AUTOSAR XML (schema 4-0-3)
package /AUTOSAR_Dem/ImplementationDataTypes
  4 x impl type, all with category=TYPE_REFERENCE, implementation-data-type=uint8:
    Dem_OperationCycleIdType: compu {0=DEM_OPCYC_POWER}, range raw 0
    Dem_IndicatorIdType: range raw 0
    Dem_RatioIdType: range raw 0
    Dem_EnableConditionType
package /AUTOSAR_Dem/SwComponentTypes
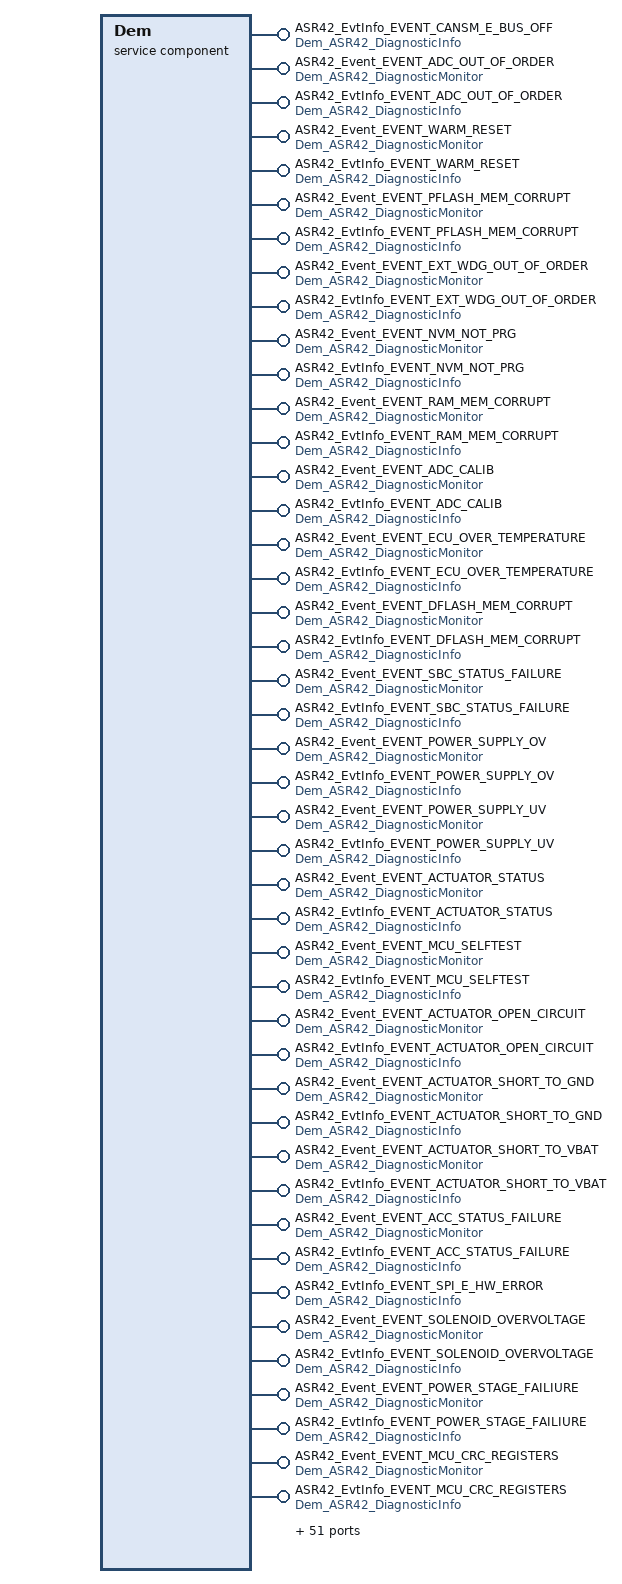
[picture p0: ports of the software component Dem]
  service sw component type Dem
    95 x provide port:
      ASR42_EvtInfo_EVENT_CANSM_E_BUS_OFF: provided-interface=Dem_ASR42_DiagnosticInfo
        provided-com-specs:
          operation=GetEventStatus, queue-length=1
          operation=GetEventFailed, queue-length=1
          operation=GetEventTested, queue-length=1
          operation=GetDTCOfEvent, queue-length=1
          operation=GetFaultDetectionCounter, queue-length=1
          operation=GetEventFreezeFrameData, queue-length=1
          operation=GetEventExtendedDataRecord, queue-length=1
          operation=GetDebouncingOfEvent, queue-length=1
          operation=GetEventExtendedDataRecordEx, queue-length=1
          operation=GetEventFreezeFrameDataEx, queue-length=1
      ASR42_Event_EVENT_ADC_OUT_OF_ORDER: provided-interface=Dem_ASR42_DiagnosticMonitor
        provided-com-specs:
          operation=SetEventStatus, queue-length=1
          operation=ResetEventStatus, queue-length=1
          operation=PrestoreFreezeFrame, queue-length=1
          operation=ClearPrestoredFreezeFrame, queue-length=1
          operation=ResetEventDebounceStatus, queue-length=1
      ASR42_EvtInfo_EVENT_ADC_OUT_OF_ORDER: provided-interface=Dem_ASR42_DiagnosticInfo
        provided-com-specs:
          operation=GetEventStatus, queue-length=1
          operation=GetEventFailed, queue-length=1
          operation=GetEventTested, queue-length=1
          operation=GetDTCOfEvent, queue-length=1
          operation=GetFaultDetectionCounter, queue-length=1
          operation=GetEventFreezeFrameData, queue-length=1
          operation=GetEventExtendedDataRecord, queue-length=1
          operation=GetDebouncingOfEvent, queue-length=1
          operation=GetEventExtendedDataRecordEx, queue-length=1
          operation=GetEventFreezeFrameDataEx, queue-length=1
      ASR42_Event_EVENT_WARM_RESET: provided-interface=Dem_ASR42_DiagnosticMonitor
        provided-com-specs:
          operation=SetEventStatus, queue-length=1
          operation=ResetEventStatus, queue-length=1
          operation=PrestoreFreezeFrame, queue-length=1
          operation=ClearPrestoredFreezeFrame, queue-length=1
          operation=ResetEventDebounceStatus, queue-length=1
      ASR42_EvtInfo_EVENT_WARM_RESET: provided-interface=Dem_ASR42_DiagnosticInfo
        provided-com-specs:
          operation=GetEventStatus, queue-length=1
          operation=GetEventFailed, queue-length=1
          operation=GetEventTested, queue-length=1
          operation=GetDTCOfEvent, queue-length=1
          operation=GetFaultDetectionCounter, queue-length=1
          operation=GetEventFreezeFrameData, queue-length=1
          operation=GetEventExtendedDataRecord, queue-length=1
          operation=GetDebouncingOfEvent, queue-length=1
          operation=GetEventExtendedDataRecordEx, queue-length=1
          operation=GetEventFreezeFrameDataEx, queue-length=1
      ASR42_Event_EVENT_PFLASH_MEM_CORRUPT: provided-interface=Dem_ASR42_DiagnosticMonitor
        provided-com-specs:
          operation=SetEventStatus, queue-length=1
          operation=ResetEventStatus, queue-length=1
          operation=PrestoreFreezeFrame, queue-length=1
          operation=ClearPrestoredFreezeFrame, queue-length=1
          operation=ResetEventDebounceStatus, queue-length=1
      ASR42_EvtInfo_EVENT_PFLASH_MEM_CORRUPT: provided-interface=Dem_ASR42_DiagnosticInfo
        provided-com-specs:
          operation=GetEventStatus, queue-length=1
          operation=GetEventFailed, queue-length=1
          operation=GetEventTested, queue-length=1
          operation=GetDTCOfEvent, queue-length=1
          operation=GetFaultDetectionCounter, queue-length=1
          operation=GetEventFreezeFrameData, queue-length=1
          operation=GetEventExtendedDataRecord, queue-length=1
          operation=GetDebouncingOfEvent, queue-length=1
          operation=GetEventExtendedDataRecordEx, queue-length=1
          operation=GetEventFreezeFrameDataEx, queue-length=1
      ASR42_Event_EVENT_EXT_WDG_OUT_OF_ORDER: provided-interface=Dem_ASR42_DiagnosticMonitor
        provided-com-specs:
          operation=SetEventStatus, queue-length=1
          operation=ResetEventStatus, queue-length=1
          operation=PrestoreFreezeFrame, queue-length=1
          operation=ClearPrestoredFreezeFrame, queue-length=1
          operation=ResetEventDebounceStatus, queue-length=1
      ASR42_EvtInfo_EVENT_EXT_WDG_OUT_OF_ORDER: provided-interface=Dem_ASR42_DiagnosticInfo
        provided-com-specs:
          operation=GetEventStatus, queue-length=1
          operation=GetEventFailed, queue-length=1
          operation=GetEventTested, queue-length=1
          operation=GetDTCOfEvent, queue-length=1
          operation=GetFaultDetectionCounter, queue-length=1
          operation=GetEventFreezeFrameData, queue-length=1
          operation=GetEventExtendedDataRecord, queue-length=1
          operation=GetDebouncingOfEvent, queue-length=1
          operation=GetEventExtendedDataRecordEx, queue-length=1
          operation=GetEventFreezeFrameDataEx, queue-length=1
      ASR42_Event_EVENT_NVM_NOT_PRG: provided-interface=Dem_ASR42_DiagnosticMonitor
        provided-com-specs:
          operation=SetEventStatus, queue-length=1
          operation=ResetEventStatus, queue-length=1
          operation=PrestoreFreezeFrame, queue-length=1
          operation=ClearPrestoredFreezeFrame, queue-length=1
          operation=ResetEventDebounceStatus, queue-length=1
      ASR42_EvtInfo_EVENT_NVM_NOT_PRG: provided-interface=Dem_ASR42_DiagnosticInfo
        provided-com-specs:
          operation=GetEventStatus, queue-length=1
          operation=GetEventFailed, queue-length=1
          operation=GetEventTested, queue-length=1
          operation=GetDTCOfEvent, queue-length=1
          operation=GetFaultDetectionCounter, queue-length=1
          operation=GetEventFreezeFrameData, queue-length=1
          operation=GetEventExtendedDataRecord, queue-length=1
          operation=GetDebouncingOfEvent, queue-length=1
          operation=GetEventExtendedDataRecordEx, queue-length=1
          operation=GetEventFreezeFrameDataEx, queue-length=1
      ASR42_Event_EVENT_RAM_MEM_CORRUPT: provided-interface=Dem_ASR42_DiagnosticMonitor
        provided-com-specs:
          operation=SetEventStatus, queue-length=1
          operation=ResetEventStatus, queue-length=1
          operation=PrestoreFreezeFrame, queue-length=1
          operation=ClearPrestoredFreezeFrame, queue-length=1
          operation=ResetEventDebounceStatus, queue-length=1
      ASR42_EvtInfo_EVENT_RAM_MEM_CORRUPT: provided-interface=Dem_ASR42_DiagnosticInfo
        provided-com-specs:
          operation=GetEventStatus, queue-length=1
          operation=GetEventFailed, queue-length=1
          operation=GetEventTested, queue-length=1
          operation=GetDTCOfEvent, queue-length=1
          operation=GetFaultDetectionCounter, queue-length=1
          operation=GetEventFreezeFrameData, queue-length=1
          operation=GetEventExtendedDataRecord, queue-length=1
          operation=GetDebouncingOfEvent, queue-length=1
          operation=GetEventExtendedDataRecordEx, queue-length=1
          operation=GetEventFreezeFrameDataEx, queue-length=1
      ASR42_Event_EVENT_ADC_CALIB: provided-interface=Dem_ASR42_DiagnosticMonitor
        provided-com-specs:
          operation=SetEventStatus, queue-length=1
          operation=ResetEventStatus, queue-length=1
          operation=PrestoreFreezeFrame, queue-length=1
          operation=ClearPrestoredFreezeFrame, queue-length=1
          operation=ResetEventDebounceStatus, queue-length=1
      ASR42_EvtInfo_EVENT_ADC_CALIB: provided-interface=Dem_ASR42_DiagnosticInfo
        provided-com-specs:
          operation=GetEventStatus, queue-length=1
          operation=GetEventFailed, queue-length=1
          operation=GetEventTested, queue-length=1
          operation=GetDTCOfEvent, queue-length=1
          operation=GetFaultDetectionCounter, queue-length=1
          operation=GetEventFreezeFrameData, queue-length=1
          operation=GetEventExtendedDataRecord, queue-length=1
          operation=GetDebouncingOfEvent, queue-length=1
          operation=GetEventExtendedDataRecordEx, queue-length=1
          operation=GetEventFreezeFrameDataEx, queue-length=1
      ASR42_Event_EVENT_ECU_OVER_TEMPERATURE: provided-interface=Dem_ASR42_DiagnosticMonitor
        provided-com-specs:
          operation=SetEventStatus, queue-length=1
          operation=ResetEventStatus, queue-length=1
          operation=PrestoreFreezeFrame, queue-length=1
          operation=ClearPrestoredFreezeFrame, queue-length=1
          operation=ResetEventDebounceStatus, queue-length=1
      ASR42_EvtInfo_EVENT_ECU_OVER_TEMPERATURE: provided-interface=Dem_ASR42_DiagnosticInfo
        provided-com-specs:
          operation=GetEventStatus, queue-length=1
          operation=GetEventFailed, queue-length=1
          operation=GetEventTested, queue-length=1
          operation=GetDTCOfEvent, queue-length=1
          operation=GetFaultDetectionCounter, queue-length=1
          operation=GetEventFreezeFrameData, queue-length=1
          operation=GetEventExtendedDataRecord, queue-length=1
          operation=GetDebouncingOfEvent, queue-length=1
          operation=GetEventExtendedDataRecordEx, queue-length=1
          operation=GetEventFreezeFrameDataEx, queue-length=1
      ASR42_Event_EVENT_DFLASH_MEM_CORRUPT: provided-interface=Dem_ASR42_DiagnosticMonitor
        provided-com-specs:
          operation=SetEventStatus, queue-length=1
          operation=ResetEventStatus, queue-length=1
          operation=PrestoreFreezeFrame, queue-length=1
          operation=ClearPrestoredFreezeFrame, queue-length=1
          operation=ResetEventDebounceStatus, queue-length=1
      ASR42_EvtInfo_EVENT_DFLASH_MEM_CORRUPT: provided-interface=Dem_ASR42_DiagnosticInfo
        provided-com-specs:
          operation=GetEventStatus, queue-length=1
          operation=GetEventFailed, queue-length=1
          operation=GetEventTested, queue-length=1
          operation=GetDTCOfEvent, queue-length=1
          operation=GetFaultDetectionCounter, queue-length=1
          operation=GetEventFreezeFrameData, queue-length=1
          operation=GetEventExtendedDataRecord, queue-length=1
          operation=GetDebouncingOfEvent, queue-length=1
          operation=GetEventExtendedDataRecordEx, queue-length=1
          operation=GetEventFreezeFrameDataEx, queue-length=1
      ASR42_Event_EVENT_SBC_STATUS_FAILURE: provided-interface=Dem_ASR42_DiagnosticMonitor
        provided-com-specs:
          operation=SetEventStatus, queue-length=1
          operation=ResetEventStatus, queue-length=1
          operation=PrestoreFreezeFrame, queue-length=1
          operation=ClearPrestoredFreezeFrame, queue-length=1
          operation=ResetEventDebounceStatus, queue-length=1
      ASR42_EvtInfo_EVENT_SBC_STATUS_FAILURE: provided-interface=Dem_ASR42_DiagnosticInfo
        provided-com-specs:
          operation=GetEventStatus, queue-length=1
          operation=GetEventFailed, queue-length=1
          operation=GetEventTested, queue-length=1
          operation=GetDTCOfEvent, queue-length=1
          operation=GetFaultDetectionCounter, queue-length=1
          operation=GetEventFreezeFrameData, queue-length=1
          operation=GetEventExtendedDataRecord, queue-length=1
          operation=GetDebouncingOfEvent, queue-length=1
          operation=GetEventExtendedDataRecordEx, queue-length=1
          operation=GetEventFreezeFrameDataEx, queue-length=1
      ASR42_Event_EVENT_POWER_SUPPLY_OV: provided-interface=Dem_ASR42_DiagnosticMonitor
        provided-com-specs:
          operation=SetEventStatus, queue-length=1
          operation=ResetEventStatus, queue-length=1
          operation=PrestoreFreezeFrame, queue-length=1
          operation=ClearPrestoredFreezeFrame, queue-length=1
          operation=ResetEventDebounceStatus, queue-length=1
      ASR42_EvtInfo_EVENT_POWER_SUPPLY_OV: provided-interface=Dem_ASR42_DiagnosticInfo
        provided-com-specs:
          operation=GetEventStatus, queue-length=1
          operation=GetEventFailed, queue-length=1
          operation=GetEventTested, queue-length=1
          operation=GetDTCOfEvent, queue-length=1
          operation=GetFaultDetectionCounter, queue-length=1
          operation=GetEventFreezeFrameData, queue-length=1
          operation=GetEventExtendedDataRecord, queue-length=1
          operation=GetDebouncingOfEvent, queue-length=1
          operation=GetEventExtendedDataRecordEx, queue-length=1
          operation=GetEventFreezeFrameDataEx, queue-length=1
      ASR42_Event_EVENT_POWER_SUPPLY_UV: provided-interface=Dem_ASR42_DiagnosticMonitor
        provided-com-specs:
          operation=SetEventStatus, queue-length=1
          operation=ResetEventStatus, queue-length=1
          operation=PrestoreFreezeFrame, queue-length=1
          operation=ClearPrestoredFreezeFrame, queue-length=1
          operation=ResetEventDebounceStatus, queue-length=1
      ASR42_EvtInfo_EVENT_POWER_SUPPLY_UV: provided-interface=Dem_ASR42_DiagnosticInfo
        provided-com-specs:
          operation=GetEventStatus, queue-length=1
          operation=GetEventFailed, queue-length=1
          operation=GetEventTested, queue-length=1
          operation=GetDTCOfEvent, queue-length=1
          operation=GetFaultDetectionCounter, queue-length=1
          operation=GetEventFreezeFrameData, queue-length=1
          operation=GetEventExtendedDataRecord, queue-length=1
          operation=GetDebouncingOfEvent, queue-length=1
          operation=GetEventExtendedDataRecordEx, queue-length=1
          operation=GetEventFreezeFrameDataEx, queue-length=1
      ASR42_Event_EVENT_ACTUATOR_STATUS: provided-interface=Dem_ASR42_DiagnosticMonitor
        provided-com-specs:
          operation=SetEventStatus, queue-length=1
          operation=ResetEventStatus, queue-length=1
          operation=PrestoreFreezeFrame, queue-length=1
          operation=ClearPrestoredFreezeFrame, queue-length=1
          operation=ResetEventDebounceStatus, queue-length=1
      ASR42_EvtInfo_EVENT_ACTUATOR_STATUS: provided-interface=Dem_ASR42_DiagnosticInfo
        provided-com-specs:
          operation=GetEventStatus, queue-length=1
          operation=GetEventFailed, queue-length=1
          operation=GetEventTested, queue-length=1
          operation=GetDTCOfEvent, queue-length=1
          operation=GetFaultDetectionCounter, queue-length=1
          operation=GetEventFreezeFrameData, queue-length=1
          operation=GetEventExtendedDataRecord, queue-length=1
          operation=GetDebouncingOfEvent, queue-length=1
          operation=GetEventExtendedDataRecordEx, queue-length=1
          operation=GetEventFreezeFrameDataEx, queue-length=1
      ASR42_Event_EVENT_MCU_SELFTEST: provided-interface=Dem_ASR42_DiagnosticMonitor
        provided-com-specs:
          operation=SetEventStatus, queue-length=1
          operation=ResetEventStatus, queue-length=1
          operation=PrestoreFreezeFrame, queue-length=1
          operation=ClearPrestoredFreezeFrame, queue-length=1
          operation=ResetEventDebounceStatus, queue-length=1
      ASR42_EvtInfo_EVENT_MCU_SELFTEST: provided-interface=Dem_ASR42_DiagnosticInfo
        provided-com-specs:
          operation=GetEventStatus, queue-length=1
          operation=GetEventFailed, queue-length=1
          operation=GetEventTested, queue-length=1
          operation=GetDTCOfEvent, queue-length=1
          operation=GetFaultDetectionCounter, queue-length=1
          operation=GetEventFreezeFrameData, queue-length=1
          operation=GetEventExtendedDataRecord, queue-length=1
          operation=GetDebouncingOfEvent, queue-length=1
          operation=GetEventExtendedDataRecordEx, queue-length=1
          operation=GetEventFreezeFrameDataEx, queue-length=1
      ASR42_Event_EVENT_ACTUATOR_OPEN_CIRCUIT: provided-interface=Dem_ASR42_DiagnosticMonitor
        provided-com-specs:
          operation=SetEventStatus, queue-length=1
          operation=ResetEventStatus, queue-length=1
          operation=PrestoreFreezeFrame, queue-length=1
          operation=ClearPrestoredFreezeFrame, queue-length=1
          operation=ResetEventDebounceStatus, queue-length=1
      ASR42_EvtInfo_EVENT_ACTUATOR_OPEN_CIRCUIT: provided-interface=Dem_ASR42_DiagnosticInfo
        provided-com-specs:
          operation=GetEventStatus, queue-length=1
          operation=GetEventFailed, queue-length=1
          operation=GetEventTested, queue-length=1
          operation=GetDTCOfEvent, queue-length=1
          operation=GetFaultDetectionCounter, queue-length=1
          operation=GetEventFreezeFrameData, queue-length=1
          operation=GetEventExtendedDataRecord, queue-length=1
          operation=GetDebouncingOfEvent, queue-length=1
          operation=GetEventExtendedDataRecordEx, queue-length=1
          operation=GetEventFreezeFrameDataEx, queue-length=1
      ASR42_Event_EVENT_ACTUATOR_SHORT_TO_GND: provided-interface=Dem_ASR42_DiagnosticMonitor
        provided-com-specs:
          operation=SetEventStatus, queue-length=1
          operation=ResetEventStatus, queue-length=1
          operation=PrestoreFreezeFrame, queue-length=1
          operation=ClearPrestoredFreezeFrame, queue-length=1
          operation=ResetEventDebounceStatus, queue-length=1
      ASR42_EvtInfo_EVENT_ACTUATOR_SHORT_TO_GND: provided-interface=Dem_ASR42_DiagnosticInfo
        provided-com-specs:
          operation=GetEventStatus, queue-length=1
          operation=GetEventFailed, queue-length=1
          operation=GetEventTested, queue-length=1
          operation=GetDTCOfEvent, queue-length=1
          operation=GetFaultDetectionCounter, queue-length=1
          operation=GetEventFreezeFrameData, queue-length=1
          operation=GetEventExtendedDataRecord, queue-length=1
          operation=GetDebouncingOfEvent, queue-length=1
          operation=GetEventExtendedDataRecordEx, queue-length=1
          operation=GetEventFreezeFrameDataEx, queue-length=1
      ASR42_Event_EVENT_ACTUATOR_SHORT_TO_VBAT: provided-interface=Dem_ASR42_DiagnosticMonitor
        provided-com-specs:
          operation=SetEventStatus, queue-length=1
          operation=ResetEventStatus, queue-length=1
          operation=PrestoreFreezeFrame, queue-length=1
          operation=ClearPrestoredFreezeFrame, queue-length=1
          operation=ResetEventDebounceStatus, queue-length=1
      ASR42_EvtInfo_EVENT_ACTUATOR_SHORT_TO_VBAT: provided-interface=Dem_ASR42_DiagnosticInfo
        provided-com-specs:
          operation=GetEventStatus, queue-length=1
          operation=GetEventFailed, queue-length=1
          operation=GetEventTested, queue-length=1
          operation=GetDTCOfEvent, queue-length=1
          operation=GetFaultDetectionCounter, queue-length=1
          operation=GetEventFreezeFrameData, queue-length=1
          operation=GetEventExtendedDataRecord, queue-length=1
          operation=GetDebouncingOfEvent, queue-length=1
          operation=GetEventExtendedDataRecordEx, queue-length=1
          operation=GetEventFreezeFrameDataEx, queue-length=1
      ASR42_Event_EVENT_ACC_STATUS_FAILURE: provided-interface=Dem_ASR42_DiagnosticMonitor
        provided-com-specs:
          operation=SetEventStatus, queue-length=1
          operation=ResetEventStatus, queue-length=1
          operation=PrestoreFreezeFrame, queue-length=1
          operation=ClearPrestoredFreezeFrame, queue-length=1
          operation=ResetEventDebounceStatus, queue-length=1
      ASR42_EvtInfo_EVENT_ACC_STATUS_FAILURE: provided-interface=Dem_ASR42_DiagnosticInfo
        provided-com-specs:
          operation=GetEventStatus, queue-length=1
          operation=GetEventFailed, queue-length=1
          operation=GetEventTested, queue-length=1
          operation=GetDTCOfEvent, queue-length=1
          operation=GetFaultDetectionCounter, queue-length=1
          operation=GetEventFreezeFrameData, queue-length=1
          operation=GetEventExtendedDataRecord, queue-length=1
          operation=GetDebouncingOfEvent, queue-length=1
          operation=GetEventExtendedDataRecordEx, queue-length=1
          operation=GetEventFreezeFrameDataEx, queue-length=1
      ASR42_EvtInfo_EVENT_SPI_E_HW_ERROR: provided-interface=Dem_ASR42_DiagnosticInfo
        provided-com-specs:
          operation=GetEventStatus, queue-length=1
          operation=GetEventFailed, queue-length=1
          operation=GetEventTested, queue-length=1
          operation=GetDTCOfEvent, queue-length=1
          operation=GetFaultDetectionCounter, queue-length=1
          operation=GetEventFreezeFrameData, queue-length=1
          operation=GetEventExtendedDataRecord, queue-length=1
          operation=GetDebouncingOfEvent, queue-length=1
          operation=GetEventExtendedDataRecordEx, queue-length=1
          operation=GetEventFreezeFrameDataEx, queue-length=1
      ASR42_Event_EVENT_SOLENOID_OVERVOLTAGE: provided-interface=Dem_ASR42_DiagnosticMonitor
        provided-com-specs:
          operation=SetEventStatus, queue-length=1
          operation=ResetEventStatus, queue-length=1
          operation=PrestoreFreezeFrame, queue-length=1
          operation=ClearPrestoredFreezeFrame, queue-length=1
          operation=ResetEventDebounceStatus, queue-length=1
      ASR42_EvtInfo_EVENT_SOLENOID_OVERVOLTAGE: provided-interface=Dem_ASR42_DiagnosticInfo
        provided-com-specs:
          operation=GetEventStatus, queue-length=1
          operation=GetEventFailed, queue-length=1
          operation=GetEventTested, queue-length=1
          operation=GetDTCOfEvent, queue-length=1
          operation=GetFaultDetectionCounter, queue-length=1
          operation=GetEventFreezeFrameData, queue-length=1
          operation=GetEventExtendedDataRecord, queue-length=1
          operation=GetDebouncingOfEvent, queue-length=1
          operation=GetEventExtendedDataRecordEx, queue-length=1
          operation=GetEventFreezeFrameDataEx, queue-length=1
      ASR42_Event_EVENT_POWER_STAGE_FAILIURE: provided-interface=Dem_ASR42_DiagnosticMonitor
        provided-com-specs:
          operation=SetEventStatus, queue-length=1
          operation=ResetEventStatus, queue-length=1
          operation=PrestoreFreezeFrame, queue-length=1
          operation=ClearPrestoredFreezeFrame, queue-length=1
          operation=ResetEventDebounceStatus, queue-length=1
      ASR42_EvtInfo_EVENT_POWER_STAGE_FAILIURE: provided-interface=Dem_ASR42_DiagnosticInfo
        provided-com-specs:
          operation=GetEventStatus, queue-length=1
          operation=GetEventFailed, queue-length=1
          operation=GetEventTested, queue-length=1
          operation=GetDTCOfEvent, queue-length=1
          operation=GetFaultDetectionCounter, queue-length=1
          operation=GetEventFreezeFrameData, queue-length=1
          operation=GetEventExtendedDataRecord, queue-length=1
          operation=GetDebouncingOfEvent, queue-length=1
          operation=GetEventExtendedDataRecordEx, queue-length=1
          operation=GetEventFreezeFrameDataEx, queue-length=1
      ASR42_Event_EVENT_MCU_CRC_REGISTERS: provided-interface=Dem_ASR42_DiagnosticMonitor
        provided-com-specs:
          operation=SetEventStatus, queue-length=1
          operation=ResetEventStatus, queue-length=1
          operation=PrestoreFreezeFrame, queue-length=1
          operation=ClearPrestoredFreezeFrame, queue-length=1
          operation=ResetEventDebounceStatus, queue-length=1
      ASR42_EvtInfo_EVENT_MCU_CRC_REGISTERS: provided-interface=Dem_ASR42_DiagnosticInfo
        provided-com-specs:
          operation=GetEventStatus, queue-length=1
          operation=GetEventFailed, queue-length=1
          operation=GetEventTested, queue-length=1
          operation=GetDTCOfEvent, queue-length=1
          operation=GetFaultDetectionCounter, queue-length=1
          operation=GetEventFreezeFrameData, queue-length=1
          operation=GetEventExtendedDataRecord, queue-length=1
          operation=GetDebouncingOfEvent, queue-length=1
          operation=GetEventExtendedDataRecordEx, queue-length=1
          operation=GetEventFreezeFrameDataEx, queue-length=1
      ASR42_GeneralEvtInfo: provided-interface=Dem_ASR42_GeneralDiagnosticInfo
        provided-com-specs:
          operation=GetEventStatus, queue-length=1
          operation=GetEventFailed, queue-length=1
          operation=GetEventTested, queue-length=1
          operation=GetDTCOfEvent, queue-length=1
          operation=GetFaultDetectionCounter, queue-length=1
          operation=GetEventFreezeFrameData, queue-length=1
          operation=GetEventExtendedDataRecord, queue-length=1
          operation=GetDebouncingOfEvent, queue-length=1
          operation=GetEventExtendedDataRecordEx, queue-length=1
          operation=GetEventFreezeFrameDataEx, queue-length=1
      ASR42_OpCycle_DEM_OPCYC_POWER: provided-com-specs=[{operation=SetOperationCycleState, queue-length=1}, {operation=SetCycleQualified, queue-length=1}], provided-interface=Dem_ASR42_OperationCycle
      ASR42_OverflowIndPrimaryMemory: provided-interface=Dem_ASR42_EvMemOverflowIndication
        provided-com-specs:
          operation=GetEventMemoryOverflow, queue-length=1
          operation=GetNumberOfEventMemoryEntries, queue-length=1
      EvtInfo_EVENT_CANSM_E_BUS_OFF: provided-interface=DiagnosticInfo
        provided-com-specs:
          operation=GetEventStatus, queue-length=1
          operation=GetEventFailed, queue-length=1
          operation=GetEventTested, queue-length=1
          operation=GetDTCOfEvent, queue-length=1
          operation=GetFaultDetectionCounter, queue-length=1
          operation=GetEventFreezeFrameData, queue-length=1
          operation=GetEventExtendedDataRecord, queue-length=1
          operation=GetDebouncingOfEvent, queue-length=1
          operation=GetEventExtendedDataRecordEx, queue-length=1
          operation=GetEventFreezeFrameDataEx, queue-length=1
      Event_EVENT_ADC_OUT_OF_ORDER: provided-interface=DiagnosticMonitor
        provided-com-specs:
          operation=SetEventStatus, queue-length=1
          operation=ResetEventStatus, queue-length=1
          operation=PrestoreFreezeFrame, queue-length=1
          operation=ClearPrestoredFreezeFrame, queue-length=1
          operation=ResetEventDebounceStatus, queue-length=1
      EvtInfo_EVENT_ADC_OUT_OF_ORDER: provided-interface=DiagnosticInfo
        provided-com-specs:
          operation=GetEventStatus, queue-length=1
          operation=GetEventFailed, queue-length=1
          operation=GetEventTested, queue-length=1
          operation=GetDTCOfEvent, queue-length=1
          operation=GetFaultDetectionCounter, queue-length=1
          operation=GetEventFreezeFrameData, queue-length=1
          operation=GetEventExtendedDataRecord, queue-length=1
          operation=GetDebouncingOfEvent, queue-length=1
          operation=GetEventExtendedDataRecordEx, queue-length=1
          operation=GetEventFreezeFrameDataEx, queue-length=1
      Event_EVENT_WARM_RESET: provided-interface=DiagnosticMonitor
        provided-com-specs:
          operation=SetEventStatus, queue-length=1
          operation=ResetEventStatus, queue-length=1
          operation=PrestoreFreezeFrame, queue-length=1
          operation=ClearPrestoredFreezeFrame, queue-length=1
          operation=ResetEventDebounceStatus, queue-length=1
      EvtInfo_EVENT_WARM_RESET: provided-interface=DiagnosticInfo
        provided-com-specs:
          operation=GetEventStatus, queue-length=1
          operation=GetEventFailed, queue-length=1
          operation=GetEventTested, queue-length=1
          operation=GetDTCOfEvent, queue-length=1
          operation=GetFaultDetectionCounter, queue-length=1
          operation=GetEventFreezeFrameData, queue-length=1
          operation=GetEventExtendedDataRecord, queue-length=1
          operation=GetDebouncingOfEvent, queue-length=1
          operation=GetEventExtendedDataRecordEx, queue-length=1
          operation=GetEventFreezeFrameDataEx, queue-length=1
      Event_EVENT_PFLASH_MEM_CORRUPT: provided-interface=DiagnosticMonitor
        provided-com-specs:
          operation=SetEventStatus, queue-length=1
          operation=ResetEventStatus, queue-length=1
          operation=PrestoreFreezeFrame, queue-length=1
          operation=ClearPrestoredFreezeFrame, queue-length=1
          operation=ResetEventDebounceStatus, queue-length=1
      EvtInfo_EVENT_PFLASH_MEM_CORRUPT: provided-interface=DiagnosticInfo
        provided-com-specs:
          operation=GetEventStatus, queue-length=1
          operation=GetEventFailed, queue-length=1
          operation=GetEventTested, queue-length=1
          operation=GetDTCOfEvent, queue-length=1
          operation=GetFaultDetectionCounter, queue-length=1
          operation=GetEventFreezeFrameData, queue-length=1
          operation=GetEventExtendedDataRecord, queue-length=1
          operation=GetDebouncingOfEvent, queue-length=1
          operation=GetEventExtendedDataRecordEx, queue-length=1
          operation=GetEventFreezeFrameDataEx, queue-length=1
      Event_EVENT_EXT_WDG_OUT_OF_ORDER: provided-interface=DiagnosticMonitor
        provided-com-specs:
          operation=SetEventStatus, queue-length=1
          operation=ResetEventStatus, queue-length=1
          operation=PrestoreFreezeFrame, queue-length=1
          operation=ClearPrestoredFreezeFrame, queue-length=1
          operation=ResetEventDebounceStatus, queue-length=1
      EvtInfo_EVENT_EXT_WDG_OUT_OF_ORDER: provided-interface=DiagnosticInfo
        provided-com-specs:
          operation=GetEventStatus, queue-length=1
          operation=GetEventFailed, queue-length=1
          operation=GetEventTested, queue-length=1
          operation=GetDTCOfEvent, queue-length=1
          operation=GetFaultDetectionCounter, queue-length=1
          operation=GetEventFreezeFrameData, queue-length=1
          operation=GetEventExtendedDataRecord, queue-length=1
          operation=GetDebouncingOfEvent, queue-length=1
          operation=GetEventExtendedDataRecordEx, queue-length=1
          operation=GetEventFreezeFrameDataEx, queue-length=1
      Event_EVENT_NVM_NOT_PRG: provided-interface=DiagnosticMonitor
        provided-com-specs:
          operation=SetEventStatus, queue-length=1
          operation=ResetEventStatus, queue-length=1
          operation=PrestoreFreezeFrame, queue-length=1
          operation=ClearPrestoredFreezeFrame, queue-length=1
          operation=ResetEventDebounceStatus, queue-length=1
      EvtInfo_EVENT_NVM_NOT_PRG: provided-interface=DiagnosticInfo
        provided-com-specs:
          operation=GetEventStatus, queue-length=1
          operation=GetEventFailed, queue-length=1
          operation=GetEventTested, queue-length=1
          operation=GetDTCOfEvent, queue-length=1
          operation=GetFaultDetectionCounter, queue-length=1
          operation=GetEventFreezeFrameData, queue-length=1
          operation=GetEventExtendedDataRecord, queue-length=1
          operation=GetDebouncingOfEvent, queue-length=1
          operation=GetEventExtendedDataRecordEx, queue-length=1
          operation=GetEventFreezeFrameDataEx, queue-length=1
      Event_EVENT_RAM_MEM_CORRUPT: provided-interface=DiagnosticMonitor
        provided-com-specs:
          operation=SetEventStatus, queue-length=1
          operation=ResetEventStatus, queue-length=1
          operation=PrestoreFreezeFrame, queue-length=1
          operation=ClearPrestoredFreezeFrame, queue-length=1
          operation=ResetEventDebounceStatus, queue-length=1
      EvtInfo_EVENT_RAM_MEM_CORRUPT: provided-interface=DiagnosticInfo
        provided-com-specs:
          operation=GetEventStatus, queue-length=1
          operation=GetEventFailed, queue-length=1
          operation=GetEventTested, queue-length=1
          operation=GetDTCOfEvent, queue-length=1
          operation=GetFaultDetectionCounter, queue-length=1
          operation=GetEventFreezeFrameData, queue-length=1
          operation=GetEventExtendedDataRecord, queue-length=1
          operation=GetDebouncingOfEvent, queue-length=1
          operation=GetEventExtendedDataRecordEx, queue-length=1
          operation=GetEventFreezeFrameDataEx, queue-length=1
      Event_EVENT_ADC_CALIB: provided-interface=DiagnosticMonitor
        provided-com-specs:
          operation=SetEventStatus, queue-length=1
          operation=ResetEventStatus, queue-length=1
          operation=PrestoreFreezeFrame, queue-length=1
          operation=ClearPrestoredFreezeFrame, queue-length=1
          operation=ResetEventDebounceStatus, queue-length=1
      EvtInfo_EVENT_ADC_CALIB: provided-interface=DiagnosticInfo
        provided-com-specs:
          operation=GetEventStatus, queue-length=1
          operation=GetEventFailed, queue-length=1
          operation=GetEventTested, queue-length=1
          operation=GetDTCOfEvent, queue-length=1
          operation=GetFaultDetectionCounter, queue-length=1
          operation=GetEventFreezeFrameData, queue-length=1
          operation=GetEventExtendedDataRecord, queue-length=1
          operation=GetDebouncingOfEvent, queue-length=1
          operation=GetEventExtendedDataRecordEx, queue-length=1
          operation=GetEventFreezeFrameDataEx, queue-length=1
      Event_EVENT_ECU_OVER_TEMPERATURE: provided-interface=DiagnosticMonitor
        provided-com-specs:
          operation=SetEventStatus, queue-length=1
          operation=ResetEventStatus, queue-length=1
          operation=PrestoreFreezeFrame, queue-length=1
          operation=ClearPrestoredFreezeFrame, queue-length=1
          operation=ResetEventDebounceStatus, queue-length=1
      EvtInfo_EVENT_ECU_OVER_TEMPERATURE: provided-interface=DiagnosticInfo
        provided-com-specs:
          operation=GetEventStatus, queue-length=1
          operation=GetEventFailed, queue-length=1
          operation=GetEventTested, queue-length=1
          operation=GetDTCOfEvent, queue-length=1
          operation=GetFaultDetectionCounter, queue-length=1
          operation=GetEventFreezeFrameData, queue-length=1
          operation=GetEventExtendedDataRecord, queue-length=1
          operation=GetDebouncingOfEvent, queue-length=1
          operation=GetEventExtendedDataRecordEx, queue-length=1
          operation=GetEventFreezeFrameDataEx, queue-length=1
      Event_EVENT_DFLASH_MEM_CORRUPT: provided-interface=DiagnosticMonitor
        provided-com-specs:
          operation=SetEventStatus, queue-length=1
          operation=ResetEventStatus, queue-length=1
          operation=PrestoreFreezeFrame, queue-length=1
          operation=ClearPrestoredFreezeFrame, queue-length=1
          operation=ResetEventDebounceStatus, queue-length=1
      EvtInfo_EVENT_DFLASH_MEM_CORRUPT: provided-interface=DiagnosticInfo
        provided-com-specs:
          operation=GetEventStatus, queue-length=1
          operation=GetEventFailed, queue-length=1
          operation=GetEventTested, queue-length=1
          operation=GetDTCOfEvent, queue-length=1
          operation=GetFaultDetectionCounter, queue-length=1
          operation=GetEventFreezeFrameData, queue-length=1
          operation=GetEventExtendedDataRecord, queue-length=1
          operation=GetDebouncingOfEvent, queue-length=1
          operation=GetEventExtendedDataRecordEx, queue-length=1
          operation=GetEventFreezeFrameDataEx, queue-length=1
      Event_EVENT_SBC_STATUS_FAILURE: provided-interface=DiagnosticMonitor
        provided-com-specs:
          operation=SetEventStatus, queue-length=1
          operation=ResetEventStatus, queue-length=1
          operation=PrestoreFreezeFrame, queue-length=1
          operation=ClearPrestoredFreezeFrame, queue-length=1
          operation=ResetEventDebounceStatus, queue-length=1
      EvtInfo_EVENT_SBC_STATUS_FAILURE: provided-interface=DiagnosticInfo
        provided-com-specs:
          operation=GetEventStatus, queue-length=1
          operation=GetEventFailed, queue-length=1
          operation=GetEventTested, queue-length=1
          operation=GetDTCOfEvent, queue-length=1
          operation=GetFaultDetectionCounter, queue-length=1
          operation=GetEventFreezeFrameData, queue-length=1
          operation=GetEventExtendedDataRecord, queue-length=1
          operation=GetDebouncingOfEvent, queue-length=1
          operation=GetEventExtendedDataRecordEx, queue-length=1
          operation=GetEventFreezeFrameDataEx, queue-length=1
      Event_EVENT_POWER_SUPPLY_OV: provided-interface=DiagnosticMonitor
        provided-com-specs:
          operation=SetEventStatus, queue-length=1
          operation=ResetEventStatus, queue-length=1
          operation=PrestoreFreezeFrame, queue-length=1
          operation=ClearPrestoredFreezeFrame, queue-length=1
          operation=ResetEventDebounceStatus, queue-length=1
      EvtInfo_EVENT_POWER_SUPPLY_OV: provided-interface=DiagnosticInfo
        provided-com-specs:
          operation=GetEventStatus, queue-length=1
          operation=GetEventFailed, queue-length=1
          operation=GetEventTested, queue-length=1
          operation=GetDTCOfEvent, queue-length=1
          operation=GetFaultDetectionCounter, queue-length=1
          operation=GetEventFreezeFrameData, queue-length=1
          operation=GetEventExtendedDataRecord, queue-length=1
          operation=GetDebouncingOfEvent, queue-length=1
          operation=GetEventExtendedDataRecordEx, queue-length=1
          operation=GetEventFreezeFrameDataEx, queue-length=1
      Event_EVENT_POWER_SUPPLY_UV: provided-interface=DiagnosticMonitor
        provided-com-specs:
          operation=SetEventStatus, queue-length=1
          operation=ResetEventStatus, queue-length=1
          operation=PrestoreFreezeFrame, queue-length=1
          operation=ClearPrestoredFreezeFrame, queue-length=1
          operation=ResetEventDebounceStatus, queue-length=1
      EvtInfo_EVENT_POWER_SUPPLY_UV: provided-interface=DiagnosticInfo
        provided-com-specs:
          operation=GetEventStatus, queue-length=1
          operation=GetEventFailed, queue-length=1
          operation=GetEventTested, queue-length=1
          operation=GetDTCOfEvent, queue-length=1
          operation=GetFaultDetectionCounter, queue-length=1
          operation=GetEventFreezeFrameData, queue-length=1
          operation=GetEventExtendedDataRecord, queue-length=1
          operation=GetDebouncingOfEvent, queue-length=1
          operation=GetEventExtendedDataRecordEx, queue-length=1
          operation=GetEventFreezeFrameDataEx, queue-length=1
      Event_EVENT_ACTUATOR_STATUS: provided-interface=DiagnosticMonitor
        provided-com-specs:
          operation=SetEventStatus, queue-length=1
          operation=ResetEventStatus, queue-length=1
          operation=PrestoreFreezeFrame, queue-length=1
          operation=ClearPrestoredFreezeFrame, queue-length=1
          operation=ResetEventDebounceStatus, queue-length=1
      EvtInfo_EVENT_ACTUATOR_STATUS: provided-interface=DiagnosticInfo
        provided-com-specs:
          operation=GetEventStatus, queue-length=1
          operation=GetEventFailed, queue-length=1
          operation=GetEventTested, queue-length=1
          operation=GetDTCOfEvent, queue-length=1
          operation=GetFaultDetectionCounter, queue-length=1
          operation=GetEventFreezeFrameData, queue-length=1
          operation=GetEventExtendedDataRecord, queue-length=1
          operation=GetDebouncingOfEvent, queue-length=1
          operation=GetEventExtendedDataRecordEx, queue-length=1
          operation=GetEventFreezeFrameDataEx, queue-length=1
      Event_EVENT_MCU_SELFTEST: provided-interface=DiagnosticMonitor
        provided-com-specs:
          operation=SetEventStatus, queue-length=1
          operation=ResetEventStatus, queue-length=1
          operation=PrestoreFreezeFrame, queue-length=1
          operation=ClearPrestoredFreezeFrame, queue-length=1
          operation=ResetEventDebounceStatus, queue-length=1
      EvtInfo_EVENT_MCU_SELFTEST: provided-interface=DiagnosticInfo
        provided-com-specs:
          operation=GetEventStatus, queue-length=1
          operation=GetEventFailed, queue-length=1
          operation=GetEventTested, queue-length=1
          operation=GetDTCOfEvent, queue-length=1
          operation=GetFaultDetectionCounter, queue-length=1
          operation=GetEventFreezeFrameData, queue-length=1
          operation=GetEventExtendedDataRecord, queue-length=1
          operation=GetDebouncingOfEvent, queue-length=1
          operation=GetEventExtendedDataRecordEx, queue-length=1
          operation=GetEventFreezeFrameDataEx, queue-length=1
      Event_EVENT_ACTUATOR_OPEN_CIRCUIT: provided-interface=DiagnosticMonitor
        provided-com-specs:
          operation=SetEventStatus, queue-length=1
          operation=ResetEventStatus, queue-length=1
          operation=PrestoreFreezeFrame, queue-length=1
          operation=ClearPrestoredFreezeFrame, queue-length=1
          operation=ResetEventDebounceStatus, queue-length=1
      EvtInfo_EVENT_ACTUATOR_OPEN_CIRCUIT: provided-interface=DiagnosticInfo
        provided-com-specs:
          operation=GetEventStatus, queue-length=1
          operation=GetEventFailed, queue-length=1
          operation=GetEventTested, queue-length=1
          operation=GetDTCOfEvent, queue-length=1
          operation=GetFaultDetectionCounter, queue-length=1
          operation=GetEventFreezeFrameData, queue-length=1
          operation=GetEventExtendedDataRecord, queue-length=1
          operation=GetDebouncingOfEvent, queue-length=1
          operation=GetEventExtendedDataRecordEx, queue-length=1
          operation=GetEventFreezeFrameDataEx, queue-length=1
      Event_EVENT_ACTUATOR_SHORT_TO_GND: provided-interface=DiagnosticMonitor
        provided-com-specs:
          operation=SetEventStatus, queue-length=1
          operation=ResetEventStatus, queue-length=1
          operation=PrestoreFreezeFrame, queue-length=1
          operation=ClearPrestoredFreezeFrame, queue-length=1
          operation=ResetEventDebounceStatus, queue-length=1
      EvtInfo_EVENT_ACTUATOR_SHORT_TO_GND: provided-interface=DiagnosticInfo
        provided-com-specs:
          operation=GetEventStatus, queue-length=1
          operation=GetEventFailed, queue-length=1
          operation=GetEventTested, queue-length=1
          operation=GetDTCOfEvent, queue-length=1
          operation=GetFaultDetectionCounter, queue-length=1
          operation=GetEventFreezeFrameData, queue-length=1
          operation=GetEventExtendedDataRecord, queue-length=1
          operation=GetDebouncingOfEvent, queue-length=1
          operation=GetEventExtendedDataRecordEx, queue-length=1
          operation=GetEventFreezeFrameDataEx, queue-length=1
      Event_EVENT_ACTUATOR_SHORT_TO_VBAT: provided-interface=DiagnosticMonitor
        provided-com-specs:
          operation=SetEventStatus, queue-length=1
          operation=ResetEventStatus, queue-length=1
          operation=PrestoreFreezeFrame, queue-length=1
          operation=ClearPrestoredFreezeFrame, queue-length=1
          operation=ResetEventDebounceStatus, queue-length=1
      EvtInfo_EVENT_ACTUATOR_SHORT_TO_VBAT: provided-interface=DiagnosticInfo
        provided-com-specs:
          operation=GetEventStatus, queue-length=1
          operation=GetEventFailed, queue-length=1
          operation=GetEventTested, queue-length=1
          operation=GetDTCOfEvent, queue-length=1
          operation=GetFaultDetectionCounter, queue-length=1
          operation=GetEventFreezeFrameData, queue-length=1
          operation=GetEventExtendedDataRecord, queue-length=1
          operation=GetDebouncingOfEvent, queue-length=1
          operation=GetEventExtendedDataRecordEx, queue-length=1
          operation=GetEventFreezeFrameDataEx, queue-length=1
      Event_EVENT_ACC_STATUS_FAILURE: provided-interface=DiagnosticMonitor
        provided-com-specs:
          operation=SetEventStatus, queue-length=1
          operation=ResetEventStatus, queue-length=1
          operation=PrestoreFreezeFrame, queue-length=1
          operation=ClearPrestoredFreezeFrame, queue-length=1
          operation=ResetEventDebounceStatus, queue-length=1
      EvtInfo_EVENT_ACC_STATUS_FAILURE: provided-interface=DiagnosticInfo
        provided-com-specs:
          operation=GetEventStatus, queue-length=1
          operation=GetEventFailed, queue-length=1
          operation=GetEventTested, queue-length=1
          operation=GetDTCOfEvent, queue-length=1
          operation=GetFaultDetectionCounter, queue-length=1
          operation=GetEventFreezeFrameData, queue-length=1
          operation=GetEventExtendedDataRecord, queue-length=1
          operation=GetDebouncingOfEvent, queue-length=1
          operation=GetEventExtendedDataRecordEx, queue-length=1
          operation=GetEventFreezeFrameDataEx, queue-length=1
      EvtInfo_EVENT_SPI_E_HW_ERROR: provided-interface=DiagnosticInfo
        provided-com-specs:
          operation=GetEventStatus, queue-length=1
          operation=GetEventFailed, queue-length=1
          operation=GetEventTested, queue-length=1
          operation=GetDTCOfEvent, queue-length=1
          operation=GetFaultDetectionCounter, queue-length=1
          operation=GetEventFreezeFrameData, queue-length=1
          operation=GetEventExtendedDataRecord, queue-length=1
          operation=GetDebouncingOfEvent, queue-length=1
          operation=GetEventExtendedDataRecordEx, queue-length=1
          operation=GetEventFreezeFrameDataEx, queue-length=1
      Event_EVENT_SOLENOID_OVERVOLTAGE: provided-interface=DiagnosticMonitor
        provided-com-specs:
          operation=SetEventStatus, queue-length=1
          operation=ResetEventStatus, queue-length=1
          operation=PrestoreFreezeFrame, queue-length=1
          operation=ClearPrestoredFreezeFrame, queue-length=1
          operation=ResetEventDebounceStatus, queue-length=1
      EvtInfo_EVENT_SOLENOID_OVERVOLTAGE: provided-interface=DiagnosticInfo
        provided-com-specs:
          operation=GetEventStatus, queue-length=1
          operation=GetEventFailed, queue-length=1
          operation=GetEventTested, queue-length=1
          operation=GetDTCOfEvent, queue-length=1
          operation=GetFaultDetectionCounter, queue-length=1
          operation=GetEventFreezeFrameData, queue-length=1
          operation=GetEventExtendedDataRecord, queue-length=1
          operation=GetDebouncingOfEvent, queue-length=1
          operation=GetEventExtendedDataRecordEx, queue-length=1
          operation=GetEventFreezeFrameDataEx, queue-length=1
      Event_EVENT_POWER_STAGE_FAILIURE: provided-interface=DiagnosticMonitor
        provided-com-specs:
          operation=SetEventStatus, queue-length=1
          operation=ResetEventStatus, queue-length=1
          operation=PrestoreFreezeFrame, queue-length=1
          operation=ClearPrestoredFreezeFrame, queue-length=1
          operation=ResetEventDebounceStatus, queue-length=1
      EvtInfo_EVENT_POWER_STAGE_FAILIURE: provided-interface=DiagnosticInfo
        provided-com-specs:
          operation=GetEventStatus, queue-length=1
          operation=GetEventFailed, queue-length=1
          operation=GetEventTested, queue-length=1
          operation=GetDTCOfEvent, queue-length=1
          operation=GetFaultDetectionCounter, queue-length=1
          operation=GetEventFreezeFrameData, queue-length=1
          operation=GetEventExtendedDataRecord, queue-length=1
          operation=GetDebouncingOfEvent, queue-length=1
          operation=GetEventExtendedDataRecordEx, queue-length=1
          operation=GetEventFreezeFrameDataEx, queue-length=1
      Event_EVENT_MCU_CRC_REGISTERS: provided-interface=DiagnosticMonitor
        provided-com-specs:
          operation=SetEventStatus, queue-length=1
          operation=ResetEventStatus, queue-length=1
          operation=PrestoreFreezeFrame, queue-length=1
          operation=ClearPrestoredFreezeFrame, queue-length=1
          operation=ResetEventDebounceStatus, queue-length=1
      EvtInfo_EVENT_MCU_CRC_REGISTERS: provided-interface=DiagnosticInfo
        provided-com-specs:
          operation=GetEventStatus, queue-length=1
          operation=GetEventFailed, queue-length=1
          operation=GetEventTested, queue-length=1
          operation=GetDTCOfEvent, queue-length=1
          operation=GetFaultDetectionCounter, queue-length=1
          operation=GetEventFreezeFrameData, queue-length=1
          operation=GetEventExtendedDataRecord, queue-length=1
          operation=GetDebouncingOfEvent, queue-length=1
          operation=GetEventExtendedDataRecordEx, queue-length=1
          operation=GetEventFreezeFrameDataEx, queue-length=1
      GeneralEvtInfo: provided-interface=GeneralDiagnosticInfo
        provided-com-specs:
          operation=GetEventStatus, queue-length=1
          operation=GetEventFailed, queue-length=1
          operation=GetEventTested, queue-length=1
          operation=GetDTCOfEvent, queue-length=1
          operation=GetFaultDetectionCounter, queue-length=1
          operation=GetEventFreezeFrameData, queue-length=1
          operation=GetEventExtendedDataRecord, queue-length=1
          operation=GetDebouncingOfEvent, queue-length=1
          operation=GetEventExtendedDataRecordEx, queue-length=1
          operation=GetEventFreezeFrameDataEx, queue-length=1
      OpCycle_DEM_OPCYC_POWER: provided-com-specs=[{operation=SetOperationCycleState, queue-length=1}, {operation=SetCycleQualified, queue-length=1}], provided-interface=OperationCycle
      OverflowIndPrimaryMemory: provided-interface=EvMemOverflowIndication
        provided-com-specs:
          operation=GetEventMemoryOverflow, queue-length=1
          operation=GetNumberOfEventMemoryEntries, queue-length=1
      CddIf: server-com-spec{operation=ClearDTC, queue-length=1}, provided-interface=CddIf
    behavior DemIntBeh: handle-termination-and-restart=NO-SUPPORT, included-data-type-set=data-type=[Dem_ASR42_EventStatusType, Dem_ASR42_InitMonitorReasonType, Dem_ASR42_IndicatorStatusType, Dem_EventStatusType, Dem_InitMonitorReasonType, Dem_IndicatorStatusType, Dem_EnableConditionType]
      699 x operation invoked event:
        ASR42_EV_GetEventStatus_EvtEVENT_CANSM_E_BUS_OFF: start-on-event=RE_GetEventStatus, operation=ASR42_EvtInfo_EVENT_CANSM_E_BUS_OFF.GetEventStatus
        ASR42_EV_GetEventFailed_EvtEVENT_CANSM_E_BUS_OFF: start-on-event=RE_GetEventFailed, operation=ASR42_EvtInfo_EVENT_CANSM_E_BUS_OFF.GetEventFailed
        ASR42_EV_GetEventTested_EvtEVENT_CANSM_E_BUS_OFF: start-on-event=RE_GetEventTested, operation=ASR42_EvtInfo_EVENT_CANSM_E_BUS_OFF.GetEventTested
        ASR42_EV_GetDTCOfEvent_EvtEVENT_CANSM_E_BUS_OFF: start-on-event=RE_GetDTCOfEvent, operation=ASR42_EvtInfo_EVENT_CANSM_E_BUS_OFF.GetDTCOfEvent
        ASR42_EV_GetFDC_EvtEVENT_CANSM_E_BUS_OFF: start-on-event=RE_GetFaultDetectionCounter, operation=ASR42_EvtInfo_EVENT_CANSM_E_BUS_OFF.GetFaultDetectionCounter
        ASR42_EV_GetEventFF_EvtEVENT_CANSM_E_BUS_OFF: start-on-event=RE_GetEventFreezeFrameData, operation=ASR42_EvtInfo_EVENT_CANSM_E_BUS_OFF.GetEventFreezeFrameData
        ASR42_EV_GetEventEDR_EvtEVENT_CANSM_E_BUS_OFF: start-on-event=RE_GetEventExtendedDataRecord, operation=ASR42_EvtInfo_EVENT_CANSM_E_BUS_OFF.GetEventExtendedDataRecord
        ASR42_EV_GetDebouncingOfEvent_EvtEVENT_CANSM_E_BUS_OFF: start-on-event=RE_GetDebouncingOfEvent, operation=ASR42_EvtInfo_EVENT_CANSM_E_BUS_OFF.GetDebouncingOfEvent
        ASR42_EV_GetEventFFEx_EvtEVENT_CANSM_E_BUS_OFF: start-on-event=RE_GetEventFreezeFrameDataEx, operation=ASR42_EvtInfo_EVENT_CANSM_E_BUS_OFF.GetEventFreezeFrameDataEx
        ASR42_EV_GetEventEDREx_EvtEVENT_CANSM_E_BUS_OFF: start-on-event=RE_GetEventExtendedDataRecordEx, operation=ASR42_EvtInfo_EVENT_CANSM_E_BUS_OFF.GetEventExtendedDataRecordEx
        ASR42_EV_SetEventStatus_EvtEVENT_ADC_OUT_OF_ORDER: start-on-event=RE_SetEventStatus, operation=ASR42_Event_EVENT_ADC_OUT_OF_ORDER.SetEventStatus
        ASR42_EV_ResetEventStatus_EvtEVENT_ADC_OUT_OF_ORDER: start-on-event=RE_ResetEventStatus, operation=ASR42_Event_EVENT_ADC_OUT_OF_ORDER.ResetEventStatus
        ASR42_EV_PrestoreFreezeFrame_EvtEVENT_ADC_OUT_OF_ORDER: start-on-event=RE_PrestoreFreezeFrame, operation=ASR42_Event_EVENT_ADC_OUT_OF_ORDER.PrestoreFreezeFrame
        ASR42_EV_ClearPrestoredFF_EvtEVENT_ADC_OUT_OF_ORDER: start-on-event=RE_ClearPrestoredFreezeFrame, operation=ASR42_Event_EVENT_ADC_OUT_OF_ORDER.ClearPrestoredFreezeFrame
        ASR42_EV_ResetEventDebounceStatus_EvtEVENT_ADC_OUT_OF_ORDER: start-on-event=RE_ResetEventDebounceStatus, operation=ASR42_Event_EVENT_ADC_OUT_OF_ORDER.ResetEventDebounceStatus
        ASR42_EV_GetEventStatus_EvtEVENT_ADC_OUT_OF_ORDER: start-on-event=RE_GetEventStatus, operation=ASR42_EvtInfo_EVENT_ADC_OUT_OF_ORDER.GetEventStatus
        ASR42_EV_GetEventFailed_EvtEVENT_ADC_OUT_OF_ORDER: start-on-event=RE_GetEventFailed, operation=ASR42_EvtInfo_EVENT_ADC_OUT_OF_ORDER.GetEventFailed
        ASR42_EV_GetEventTested_EvtEVENT_ADC_OUT_OF_ORDER: start-on-event=RE_GetEventTested, operation=ASR42_EvtInfo_EVENT_ADC_OUT_OF_ORDER.GetEventTested
        ASR42_EV_GetDTCOfEvent_EvtEVENT_ADC_OUT_OF_ORDER: start-on-event=RE_GetDTCOfEvent, operation=ASR42_EvtInfo_EVENT_ADC_OUT_OF_ORDER.GetDTCOfEvent
        ASR42_EV_GetFDC_EvtEVENT_ADC_OUT_OF_ORDER: start-on-event=RE_GetFaultDetectionCounter, operation=ASR42_EvtInfo_EVENT_ADC_OUT_OF_ORDER.GetFaultDetectionCounter
        ASR42_EV_GetEventFF_EvtEVENT_ADC_OUT_OF_ORDER: start-on-event=RE_GetEventFreezeFrameData, operation=ASR42_EvtInfo_EVENT_ADC_OUT_OF_ORDER.GetEventFreezeFrameData
        ASR42_EV_GetEventEDR_EvtEVENT_ADC_OUT_OF_ORDER: start-on-event=RE_GetEventExtendedDataRecord, operation=ASR42_EvtInfo_EVENT_ADC_OUT_OF_ORDER.GetEventExtendedDataRecord
        ASR42_EV_GetDebouncingOfEvent_EvtEVENT_ADC_OUT_OF_ORDER: start-on-event=RE_GetDebouncingOfEvent, operation=ASR42_EvtInfo_EVENT_ADC_OUT_OF_ORDER.GetDebouncingOfEvent
        ASR42_EV_GetEventFFEx_EvtEVENT_ADC_OUT_OF_ORDER: start-on-event=RE_GetEventFreezeFrameDataEx, operation=ASR42_EvtInfo_EVENT_ADC_OUT_OF_ORDER.GetEventFreezeFrameDataEx
        ASR42_EV_GetEventEDREx_EvtEVENT_ADC_OUT_OF_ORDER: start-on-event=RE_GetEventExtendedDataRecordEx, operation=ASR42_EvtInfo_EVENT_ADC_OUT_OF_ORDER.GetEventExtendedDataRecordEx
        ASR42_EV_SetEventStatus_EvtEVENT_WARM_RESET: start-on-event=RE_SetEventStatus, operation=ASR42_Event_EVENT_WARM_RESET.SetEventStatus
        ASR42_EV_ResetEventStatus_EvtEVENT_WARM_RESET: start-on-event=RE_ResetEventStatus, operation=ASR42_Event_EVENT_WARM_RESET.ResetEventStatus
        ASR42_EV_PrestoreFreezeFrame_EvtEVENT_WARM_RESET: start-on-event=RE_PrestoreFreezeFrame, operation=ASR42_Event_EVENT_WARM_RESET.PrestoreFreezeFrame
        ASR42_EV_ClearPrestoredFF_EvtEVENT_WARM_RESET: start-on-event=RE_ClearPrestoredFreezeFrame, operation=ASR42_Event_EVENT_WARM_RESET.ClearPrestoredFreezeFrame
        ASR42_EV_ResetEventDebounceStatus_EvtEVENT_WARM_RESET: start-on-event=RE_ResetEventDebounceStatus, operation=ASR42_Event_EVENT_WARM_RESET.ResetEventDebounceStatus
        ASR42_EV_GetEventStatus_EvtEVENT_WARM_RESET: start-on-event=RE_GetEventStatus, operation=ASR42_EvtInfo_EVENT_WARM_RESET.GetEventStatus
        ASR42_EV_GetEventFailed_EvtEVENT_WARM_RESET: start-on-event=RE_GetEventFailed, operation=ASR42_EvtInfo_EVENT_WARM_RESET.GetEventFailed
        ASR42_EV_GetEventTested_EvtEVENT_WARM_RESET: start-on-event=RE_GetEventTested, operation=ASR42_EvtInfo_EVENT_WARM_RESET.GetEventTested
        ASR42_EV_GetDTCOfEvent_EvtEVENT_WARM_RESET: start-on-event=RE_GetDTCOfEvent, operation=ASR42_EvtInfo_EVENT_WARM_RESET.GetDTCOfEvent
        ASR42_EV_GetFDC_EvtEVENT_WARM_RESET: start-on-event=RE_GetFaultDetectionCounter, operation=ASR42_EvtInfo_EVENT_WARM_RESET.GetFaultDetectionCounter
        ASR42_EV_GetEventFF_EvtEVENT_WARM_RESET: start-on-event=RE_GetEventFreezeFrameData, operation=ASR42_EvtInfo_EVENT_WARM_RESET.GetEventFreezeFrameData
        ASR42_EV_GetEventEDR_EvtEVENT_WARM_RESET: start-on-event=RE_GetEventExtendedDataRecord, operation=ASR42_EvtInfo_EVENT_WARM_RESET.GetEventExtendedDataRecord
        ASR42_EV_GetDebouncingOfEvent_EvtEVENT_WARM_RESET: start-on-event=RE_GetDebouncingOfEvent, operation=ASR42_EvtInfo_EVENT_WARM_RESET.GetDebouncingOfEvent
        ASR42_EV_GetEventFFEx_EvtEVENT_WARM_RESET: start-on-event=RE_GetEventFreezeFrameDataEx, operation=ASR42_EvtInfo_EVENT_WARM_RESET.GetEventFreezeFrameDataEx
        ASR42_EV_GetEventEDREx_EvtEVENT_WARM_RESET: start-on-event=RE_GetEventExtendedDataRecordEx, operation=ASR42_EvtInfo_EVENT_WARM_RESET.GetEventExtendedDataRecordEx
        ASR42_EV_SetEventStatus_EvtEVENT_PFLASH_MEM_CORRUPT: start-on-event=RE_SetEventStatus, operation=ASR42_Event_EVENT_PFLASH_MEM_CORRUPT.SetEventStatus
        ASR42_EV_ResetEventStatus_EvtEVENT_PFLASH_MEM_CORRUPT: start-on-event=RE_ResetEventStatus, operation=ASR42_Event_EVENT_PFLASH_MEM_CORRUPT.ResetEventStatus
        ASR42_EV_PrestoreFreezeFrame_EvtEVENT_PFLASH_MEM_CORRUPT: start-on-event=RE_PrestoreFreezeFrame, operation=ASR42_Event_EVENT_PFLASH_MEM_CORRUPT.PrestoreFreezeFrame
        ASR42_EV_ClearPrestoredFF_EvtEVENT_PFLASH_MEM_CORRUPT: start-on-event=RE_ClearPrestoredFreezeFrame, operation=ASR42_Event_EVENT_PFLASH_MEM_CORRUPT.ClearPrestoredFreezeFrame
        ASR42_EV_ResetEventDebounceStatus_EvtEVENT_PFLASH_MEM_CORRUPT: start-on-event=RE_ResetEventDebounceStatus, operation=ASR42_Event_EVENT_PFLASH_MEM_CORRUPT.ResetEventDebounceStatus
        ASR42_EV_GetEventStatus_EvtEVENT_PFLASH_MEM_CORRUPT: start-on-event=RE_GetEventStatus, operation=ASR42_EvtInfo_EVENT_PFLASH_MEM_CORRUPT.GetEventStatus
        ASR42_EV_GetEventFailed_EvtEVENT_PFLASH_MEM_CORRUPT: start-on-event=RE_GetEventFailed, operation=ASR42_EvtInfo_EVENT_PFLASH_MEM_CORRUPT.GetEventFailed
        ASR42_EV_GetEventTested_EvtEVENT_PFLASH_MEM_CORRUPT: start-on-event=RE_GetEventTested, operation=ASR42_EvtInfo_EVENT_PFLASH_MEM_CORRUPT.GetEventTested
        ASR42_EV_GetDTCOfEvent_EvtEVENT_PFLASH_MEM_CORRUPT: start-on-event=RE_GetDTCOfEvent, operation=ASR42_EvtInfo_EVENT_PFLASH_MEM_CORRUPT.GetDTCOfEvent
        ASR42_EV_GetFDC_EvtEVENT_PFLASH_MEM_CORRUPT: start-on-event=RE_GetFaultDetectionCounter, operation=ASR42_EvtInfo_EVENT_PFLASH_MEM_CORRUPT.GetFaultDetectionCounter
        ASR42_EV_GetEventFF_EvtEVENT_PFLASH_MEM_CORRUPT: start-on-event=RE_GetEventFreezeFrameData, operation=ASR42_EvtInfo_EVENT_PFLASH_MEM_CORRUPT.GetEventFreezeFrameData
        ASR42_EV_GetEventEDR_EvtEVENT_PFLASH_MEM_CORRUPT: start-on-event=RE_GetEventExtendedDataRecord, operation=ASR42_EvtInfo_EVENT_PFLASH_MEM_CORRUPT.GetEventExtendedDataRecord
        ASR42_EV_GetDebouncingOfEvent_EvtEVENT_PFLASH_MEM_CORRUPT: start-on-event=RE_GetDebouncingOfEvent, operation=ASR42_EvtInfo_EVENT_PFLASH_MEM_CORRUPT.GetDebouncingOfEvent
        ASR42_EV_GetEventFFEx_EvtEVENT_PFLASH_MEM_CORRUPT: start-on-event=RE_GetEventFreezeFrameDataEx, operation=ASR42_EvtInfo_EVENT_PFLASH_MEM_CORRUPT.GetEventFreezeFrameDataEx
        ASR42_EV_GetEventEDREx_EvtEVENT_PFLASH_MEM_CORRUPT: start-on-event=RE_GetEventExtendedDataRecordEx, operation=ASR42_EvtInfo_EVENT_PFLASH_MEM_CORRUPT.GetEventExtendedDataRecordEx
        ASR42_EV_SetEventStatus_EvtEVENT_EXT_WDG_OUT_OF_ORDER: start-on-event=RE_SetEventStatus, operation=ASR42_Event_EVENT_EXT_WDG_OUT_OF_ORDER.SetEventStatus
        ASR42_EV_ResetEventStatus_EvtEVENT_EXT_WDG_OUT_OF_ORDER: start-on-event=RE_ResetEventStatus, operation=ASR42_Event_EVENT_EXT_WDG_OUT_OF_ORDER.ResetEventStatus
        ASR42_EV_PrestoreFreezeFrame_EvtEVENT_EXT_WDG_OUT_OF_ORDER: start-on-event=RE_PrestoreFreezeFrame, operation=ASR42_Event_EVENT_EXT_WDG_OUT_OF_ORDER.PrestoreFreezeFrame
        ASR42_EV_ClearPrestoredFF_EvtEVENT_EXT_WDG_OUT_OF_ORDER: start-on-event=RE_ClearPrestoredFreezeFrame, operation=ASR42_Event_EVENT_EXT_WDG_OUT_OF_ORDER.ClearPrestoredFreezeFrame
        ASR42_EV_ResetEventDebounceStatus_EvtEVENT_EXT_WDG_OUT_OF_ORDER: start-on-event=RE_ResetEventDebounceStatus, operation=ASR42_Event_EVENT_EXT_WDG_OUT_OF_ORDER.ResetEventDebounceStatus
        ASR42_EV_GetEventStatus_EvtEVENT_EXT_WDG_OUT_OF_ORDER: start-on-event=RE_GetEventStatus, operation=ASR42_EvtInfo_EVENT_EXT_WDG_OUT_OF_ORDER.GetEventStatus
        ASR42_EV_GetEventFailed_EvtEVENT_EXT_WDG_OUT_OF_ORDER: start-on-event=RE_GetEventFailed, operation=ASR42_EvtInfo_EVENT_EXT_WDG_OUT_OF_ORDER.GetEventFailed
        ASR42_EV_GetEventTested_EvtEVENT_EXT_WDG_OUT_OF_ORDER: start-on-event=RE_GetEventTested, operation=ASR42_EvtInfo_EVENT_EXT_WDG_OUT_OF_ORDER.GetEventTested
        ASR42_EV_GetDTCOfEvent_EvtEVENT_EXT_WDG_OUT_OF_ORDER: start-on-event=RE_GetDTCOfEvent, operation=ASR42_EvtInfo_EVENT_EXT_WDG_OUT_OF_ORDER.GetDTCOfEvent
        ASR42_EV_GetFDC_EvtEVENT_EXT_WDG_OUT_OF_ORDER: start-on-event=RE_GetFaultDetectionCounter, operation=ASR42_EvtInfo_EVENT_EXT_WDG_OUT_OF_ORDER.GetFaultDetectionCounter
        ASR42_EV_GetEventFF_EvtEVENT_EXT_WDG_OUT_OF_ORDER: start-on-event=RE_GetEventFreezeFrameData, operation=ASR42_EvtInfo_EVENT_EXT_WDG_OUT_OF_ORDER.GetEventFreezeFrameData
        ASR42_EV_GetEventEDR_EvtEVENT_EXT_WDG_OUT_OF_ORDER: start-on-event=RE_GetEventExtendedDataRecord, operation=ASR42_EvtInfo_EVENT_EXT_WDG_OUT_OF_ORDER.GetEventExtendedDataRecord
        ASR42_EV_GetDebouncingOfEvent_EvtEVENT_EXT_WDG_OUT_OF_ORDER: start-on-event=RE_GetDebouncingOfEvent, operation=ASR42_EvtInfo_EVENT_EXT_WDG_OUT_OF_ORDER.GetDebouncingOfEvent
        ASR42_EV_GetEventFFEx_EvtEVENT_EXT_WDG_OUT_OF_ORDER: start-on-event=RE_GetEventFreezeFrameDataEx, operation=ASR42_EvtInfo_EVENT_EXT_WDG_OUT_OF_ORDER.GetEventFreezeFrameDataEx
        ASR42_EV_GetEventEDREx_EvtEVENT_EXT_WDG_OUT_OF_ORDER: start-on-event=RE_GetEventExtendedDataRecordEx, operation=ASR42_EvtInfo_EVENT_EXT_WDG_OUT_OF_ORDER.GetEventExtendedDataRecordEx
        ASR42_EV_SetEventStatus_EvtEVENT_NVM_NOT_PRG: start-on-event=RE_SetEventStatus, operation=ASR42_Event_EVENT_NVM_NOT_PRG.SetEventStatus
        ASR42_EV_ResetEventStatus_EvtEVENT_NVM_NOT_PRG: start-on-event=RE_ResetEventStatus, operation=ASR42_Event_EVENT_NVM_NOT_PRG.ResetEventStatus
        ASR42_EV_PrestoreFreezeFrame_EvtEVENT_NVM_NOT_PRG: start-on-event=RE_PrestoreFreezeFrame, operation=ASR42_Event_EVENT_NVM_NOT_PRG.PrestoreFreezeFrame
        ASR42_EV_ClearPrestoredFF_EvtEVENT_NVM_NOT_PRG: start-on-event=RE_ClearPrestoredFreezeFrame, operation=ASR42_Event_EVENT_NVM_NOT_PRG.ClearPrestoredFreezeFrame
        ASR42_EV_ResetEventDebounceStatus_EvtEVENT_NVM_NOT_PRG: start-on-event=RE_ResetEventDebounceStatus, operation=ASR42_Event_EVENT_NVM_NOT_PRG.ResetEventDebounceStatus
        ASR42_EV_GetEventStatus_EvtEVENT_NVM_NOT_PRG: start-on-event=RE_GetEventStatus, operation=ASR42_EvtInfo_EVENT_NVM_NOT_PRG.GetEventStatus
        ASR42_EV_GetEventFailed_EvtEVENT_NVM_NOT_PRG: start-on-event=RE_GetEventFailed, operation=ASR42_EvtInfo_EVENT_NVM_NOT_PRG.GetEventFailed
        ASR42_EV_GetEventTested_EvtEVENT_NVM_NOT_PRG: start-on-event=RE_GetEventTested, operation=ASR42_EvtInfo_EVENT_NVM_NOT_PRG.GetEventTested
        ASR42_EV_GetDTCOfEvent_EvtEVENT_NVM_NOT_PRG: start-on-event=RE_GetDTCOfEvent, operation=ASR42_EvtInfo_EVENT_NVM_NOT_PRG.GetDTCOfEvent
        ASR42_EV_GetFDC_EvtEVENT_NVM_NOT_PRG: start-on-event=RE_GetFaultDetectionCounter, operation=ASR42_EvtInfo_EVENT_NVM_NOT_PRG.GetFaultDetectionCounter
        ASR42_EV_GetEventFF_EvtEVENT_NVM_NOT_PRG: start-on-event=RE_GetEventFreezeFrameData, operation=ASR42_EvtInfo_EVENT_NVM_NOT_PRG.GetEventFreezeFrameData
        ASR42_EV_GetEventEDR_EvtEVENT_NVM_NOT_PRG: start-on-event=RE_GetEventExtendedDataRecord, operation=ASR42_EvtInfo_EVENT_NVM_NOT_PRG.GetEventExtendedDataRecord
        ASR42_EV_GetDebouncingOfEvent_EvtEVENT_NVM_NOT_PRG: start-on-event=RE_GetDebouncingOfEvent, operation=ASR42_EvtInfo_EVENT_NVM_NOT_PRG.GetDebouncingOfEvent
        ASR42_EV_GetEventFFEx_EvtEVENT_NVM_NOT_PRG: start-on-event=RE_GetEventFreezeFrameDataEx, operation=ASR42_EvtInfo_EVENT_NVM_NOT_PRG.GetEventFreezeFrameDataEx
        ASR42_EV_GetEventEDREx_EvtEVENT_NVM_NOT_PRG: start-on-event=RE_GetEventExtendedDataRecordEx, operation=ASR42_EvtInfo_EVENT_NVM_NOT_PRG.GetEventExtendedDataRecordEx
        ASR42_EV_SetEventStatus_EvtEVENT_RAM_MEM_CORRUPT: start-on-event=RE_SetEventStatus, operation=ASR42_Event_EVENT_RAM_MEM_CORRUPT.SetEventStatus
        ASR42_EV_ResetEventStatus_EvtEVENT_RAM_MEM_CORRUPT: start-on-event=RE_ResetEventStatus, operation=ASR42_Event_EVENT_RAM_MEM_CORRUPT.ResetEventStatus
        ASR42_EV_PrestoreFreezeFrame_EvtEVENT_RAM_MEM_CORRUPT: start-on-event=RE_PrestoreFreezeFrame, operation=ASR42_Event_EVENT_RAM_MEM_CORRUPT.PrestoreFreezeFrame
        ASR42_EV_ClearPrestoredFF_EvtEVENT_RAM_MEM_CORRUPT: start-on-event=RE_ClearPrestoredFreezeFrame, operation=ASR42_Event_EVENT_RAM_MEM_CORRUPT.ClearPrestoredFreezeFrame
        ASR42_EV_ResetEventDebounceStatus_EvtEVENT_RAM_MEM_CORRUPT: start-on-event=RE_ResetEventDebounceStatus, operation=ASR42_Event_EVENT_RAM_MEM_CORRUPT.ResetEventDebounceStatus
        ASR42_EV_GetEventStatus_EvtEVENT_RAM_MEM_CORRUPT: start-on-event=RE_GetEventStatus, operation=ASR42_EvtInfo_EVENT_RAM_MEM_CORRUPT.GetEventStatus
        ASR42_EV_GetEventFailed_EvtEVENT_RAM_MEM_CORRUPT: start-on-event=RE_GetEventFailed, operation=ASR42_EvtInfo_EVENT_RAM_MEM_CORRUPT.GetEventFailed
        ASR42_EV_GetEventTested_EvtEVENT_RAM_MEM_CORRUPT: start-on-event=RE_GetEventTested, operation=ASR42_EvtInfo_EVENT_RAM_MEM_CORRUPT.GetEventTested
        ASR42_EV_GetDTCOfEvent_EvtEVENT_RAM_MEM_CORRUPT: start-on-event=RE_GetDTCOfEvent, operation=ASR42_EvtInfo_EVENT_RAM_MEM_CORRUPT.GetDTCOfEvent
        ASR42_EV_GetFDC_EvtEVENT_RAM_MEM_CORRUPT: start-on-event=RE_GetFaultDetectionCounter, operation=ASR42_EvtInfo_EVENT_RAM_MEM_CORRUPT.GetFaultDetectionCounter
        ASR42_EV_GetEventFF_EvtEVENT_RAM_MEM_CORRUPT: start-on-event=RE_GetEventFreezeFrameData, operation=ASR42_EvtInfo_EVENT_RAM_MEM_CORRUPT.GetEventFreezeFrameData
        ASR42_EV_GetEventEDR_EvtEVENT_RAM_MEM_CORRUPT: start-on-event=RE_GetEventExtendedDataRecord, operation=ASR42_EvtInfo_EVENT_RAM_MEM_CORRUPT.GetEventExtendedDataRecord
        ASR42_EV_GetDebouncingOfEvent_EvtEVENT_RAM_MEM_CORRUPT: start-on-event=RE_GetDebouncingOfEvent, operation=ASR42_EvtInfo_EVENT_RAM_MEM_CORRUPT.GetDebouncingOfEvent
        ASR42_EV_GetEventFFEx_EvtEVENT_RAM_MEM_CORRUPT: start-on-event=RE_GetEventFreezeFrameDataEx, operation=ASR42_EvtInfo_EVENT_RAM_MEM_CORRUPT.GetEventFreezeFrameDataEx
        ASR42_EV_GetEventEDREx_EvtEVENT_RAM_MEM_CORRUPT: start-on-event=RE_GetEventExtendedDataRecordEx, operation=ASR42_EvtInfo_EVENT_RAM_MEM_CORRUPT.GetEventExtendedDataRecordEx
        ASR42_EV_SetEventStatus_EvtEVENT_ADC_CALIB: start-on-event=RE_SetEventStatus, operation=ASR42_Event_EVENT_ADC_CALIB.SetEventStatus
        ASR42_EV_ResetEventStatus_EvtEVENT_ADC_CALIB: start-on-event=RE_ResetEventStatus, operation=ASR42_Event_EVENT_ADC_CALIB.ResetEventStatus
        ASR42_EV_PrestoreFreezeFrame_EvtEVENT_ADC_CALIB: start-on-event=RE_PrestoreFreezeFrame, operation=ASR42_Event_EVENT_ADC_CALIB.PrestoreFreezeFrame
        ASR42_EV_ClearPrestoredFF_EvtEVENT_ADC_CALIB: start-on-event=RE_ClearPrestoredFreezeFrame, operation=ASR42_Event_EVENT_ADC_CALIB.ClearPrestoredFreezeFrame
        ASR42_EV_ResetEventDebounceStatus_EvtEVENT_ADC_CALIB: start-on-event=RE_ResetEventDebounceStatus, operation=ASR42_Event_EVENT_ADC_CALIB.ResetEventDebounceStatus
        ASR42_EV_GetEventStatus_EvtEVENT_ADC_CALIB: start-on-event=RE_GetEventStatus, operation=ASR42_EvtInfo_EVENT_ADC_CALIB.GetEventStatus
        ASR42_EV_GetEventFailed_EvtEVENT_ADC_CALIB: start-on-event=RE_GetEventFailed, operation=ASR42_EvtInfo_EVENT_ADC_CALIB.GetEventFailed
        ASR42_EV_GetEventTested_EvtEVENT_ADC_CALIB: start-on-event=RE_GetEventTested, operation=ASR42_EvtInfo_EVENT_ADC_CALIB.GetEventTested
        ASR42_EV_GetDTCOfEvent_EvtEVENT_ADC_CALIB: start-on-event=RE_GetDTCOfEvent, operation=ASR42_EvtInfo_EVENT_ADC_CALIB.GetDTCOfEvent
        ASR42_EV_GetFDC_EvtEVENT_ADC_CALIB: start-on-event=RE_GetFaultDetectionCounter, operation=ASR42_EvtInfo_EVENT_ADC_CALIB.GetFaultDetectionCounter
        ASR42_EV_GetEventFF_EvtEVENT_ADC_CALIB: start-on-event=RE_GetEventFreezeFrameData, operation=ASR42_EvtInfo_EVENT_ADC_CALIB.GetEventFreezeFrameData
        ASR42_EV_GetEventEDR_EvtEVENT_ADC_CALIB: start-on-event=RE_GetEventExtendedDataRecord, operation=ASR42_EvtInfo_EVENT_ADC_CALIB.GetEventExtendedDataRecord
        ASR42_EV_GetDebouncingOfEvent_EvtEVENT_ADC_CALIB: start-on-event=RE_GetDebouncingOfEvent, operation=ASR42_EvtInfo_EVENT_ADC_CALIB.GetDebouncingOfEvent
        ASR42_EV_GetEventFFEx_EvtEVENT_ADC_CALIB: start-on-event=RE_GetEventFreezeFrameDataEx, operation=ASR42_EvtInfo_EVENT_ADC_CALIB.GetEventFreezeFrameDataEx
        ASR42_EV_GetEventEDREx_EvtEVENT_ADC_CALIB: start-on-event=RE_GetEventExtendedDataRecordEx, operation=ASR42_EvtInfo_EVENT_ADC_CALIB.GetEventExtendedDataRecordEx
        ASR42_EV_SetEventStatus_EvtEVENT_ECU_OVER_TEMPERATURE: start-on-event=RE_SetEventStatus, operation=ASR42_Event_EVENT_ECU_OVER_TEMPERATURE.SetEventStatus
        ASR42_EV_ResetEventStatus_EvtEVENT_ECU_OVER_TEMPERATURE: start-on-event=RE_ResetEventStatus, operation=ASR42_Event_EVENT_ECU_OVER_TEMPERATURE.ResetEventStatus
        ASR42_EV_PrestoreFreezeFrame_EvtEVENT_ECU_OVER_TEMPERATURE: start-on-event=RE_PrestoreFreezeFrame, operation=ASR42_Event_EVENT_ECU_OVER_TEMPERATURE.PrestoreFreezeFrame
        ASR42_EV_ClearPrestoredFF_EvtEVENT_ECU_OVER_TEMPERATURE: start-on-event=RE_ClearPrestoredFreezeFrame, operation=ASR42_Event_EVENT_ECU_OVER_TEMPERATURE.ClearPrestoredFreezeFrame
        ASR42_EV_ResetEventDebounceStatus_EvtEVENT_ECU_OVER_TEMPERATURE: start-on-event=RE_ResetEventDebounceStatus, operation=ASR42_Event_EVENT_ECU_OVER_TEMPERATURE.ResetEventDebounceStatus
        ASR42_EV_GetEventStatus_EvtEVENT_ECU_OVER_TEMPERATURE: start-on-event=RE_GetEventStatus, operation=ASR42_EvtInfo_EVENT_ECU_OVER_TEMPERATURE.GetEventStatus
        ASR42_EV_GetEventFailed_EvtEVENT_ECU_OVER_TEMPERATURE: start-on-event=RE_GetEventFailed, operation=ASR42_EvtInfo_EVENT_ECU_OVER_TEMPERATURE.GetEventFailed
        ASR42_EV_GetEventTested_EvtEVENT_ECU_OVER_TEMPERATURE: start-on-event=RE_GetEventTested, operation=ASR42_EvtInfo_EVENT_ECU_OVER_TEMPERATURE.GetEventTested
        ASR42_EV_GetDTCOfEvent_EvtEVENT_ECU_OVER_TEMPERATURE: start-on-event=RE_GetDTCOfEvent, operation=ASR42_EvtInfo_EVENT_ECU_OVER_TEMPERATURE.GetDTCOfEvent
        ASR42_EV_GetFDC_EvtEVENT_ECU_OVER_TEMPERATURE: start-on-event=RE_GetFaultDetectionCounter, operation=ASR42_EvtInfo_EVENT_ECU_OVER_TEMPERATURE.GetFaultDetectionCounter
        ASR42_EV_GetEventFF_EvtEVENT_ECU_OVER_TEMPERATURE: start-on-event=RE_GetEventFreezeFrameData, operation=ASR42_EvtInfo_EVENT_ECU_OVER_TEMPERATURE.GetEventFreezeFrameData
        ASR42_EV_GetEventEDR_EvtEVENT_ECU_OVER_TEMPERATURE: start-on-event=RE_GetEventExtendedDataRecord, operation=ASR42_EvtInfo_EVENT_ECU_OVER_TEMPERATURE.GetEventExtendedDataRecord
        ASR42_EV_GetDebouncingOfEvent_EvtEVENT_ECU_OVER_TEMPERATURE: start-on-event=RE_GetDebouncingOfEvent, operation=ASR42_EvtInfo_EVENT_ECU_OVER_TEMPERATURE.GetDebouncingOfEvent
        ASR42_EV_GetEventFFEx_EvtEVENT_ECU_OVER_TEMPERATURE: start-on-event=RE_GetEventFreezeFrameDataEx, operation=ASR42_EvtInfo_EVENT_ECU_OVER_TEMPERATURE.GetEventFreezeFrameDataEx
        ASR42_EV_GetEventEDREx_EvtEVENT_ECU_OVER_TEMPERATURE: start-on-event=RE_GetEventExtendedDataRecordEx, operation=ASR42_EvtInfo_EVENT_ECU_OVER_TEMPERATURE.GetEventExtendedDataRecordEx
        ASR42_EV_SetEventStatus_EvtEVENT_DFLASH_MEM_CORRUPT: start-on-event=RE_SetEventStatus, operation=ASR42_Event_EVENT_DFLASH_MEM_CORRUPT.SetEventStatus
        ASR42_EV_ResetEventStatus_EvtEVENT_DFLASH_MEM_CORRUPT: start-on-event=RE_ResetEventStatus, operation=ASR42_Event_EVENT_DFLASH_MEM_CORRUPT.ResetEventStatus
        ASR42_EV_PrestoreFreezeFrame_EvtEVENT_DFLASH_MEM_CORRUPT: start-on-event=RE_PrestoreFreezeFrame, operation=ASR42_Event_EVENT_DFLASH_MEM_CORRUPT.PrestoreFreezeFrame
        ASR42_EV_ClearPrestoredFF_EvtEVENT_DFLASH_MEM_CORRUPT: start-on-event=RE_ClearPrestoredFreezeFrame, operation=ASR42_Event_EVENT_DFLASH_MEM_CORRUPT.ClearPrestoredFreezeFrame
        ASR42_EV_ResetEventDebounceStatus_EvtEVENT_DFLASH_MEM_CORRUPT: start-on-event=RE_ResetEventDebounceStatus, operation=ASR42_Event_EVENT_DFLASH_MEM_CORRUPT.ResetEventDebounceStatus
        ASR42_EV_GetEventStatus_EvtEVENT_DFLASH_MEM_CORRUPT: start-on-event=RE_GetEventStatus, operation=ASR42_EvtInfo_EVENT_DFLASH_MEM_CORRUPT.GetEventStatus
        ASR42_EV_GetEventFailed_EvtEVENT_DFLASH_MEM_CORRUPT: start-on-event=RE_GetEventFailed, operation=ASR42_EvtInfo_EVENT_DFLASH_MEM_CORRUPT.GetEventFailed
        ASR42_EV_GetEventTested_EvtEVENT_DFLASH_MEM_CORRUPT: start-on-event=RE_GetEventTested, operation=ASR42_EvtInfo_EVENT_DFLASH_MEM_CORRUPT.GetEventTested
        ASR42_EV_GetDTCOfEvent_EvtEVENT_DFLASH_MEM_CORRUPT: start-on-event=RE_GetDTCOfEvent, operation=ASR42_EvtInfo_EVENT_DFLASH_MEM_CORRUPT.GetDTCOfEvent
        ASR42_EV_GetFDC_EvtEVENT_DFLASH_MEM_CORRUPT: start-on-event=RE_GetFaultDetectionCounter, operation=ASR42_EvtInfo_EVENT_DFLASH_MEM_CORRUPT.GetFaultDetectionCounter
        ASR42_EV_GetEventFF_EvtEVENT_DFLASH_MEM_CORRUPT: start-on-event=RE_GetEventFreezeFrameData, operation=ASR42_EvtInfo_EVENT_DFLASH_MEM_CORRUPT.GetEventFreezeFrameData
        ASR42_EV_GetEventEDR_EvtEVENT_DFLASH_MEM_CORRUPT: start-on-event=RE_GetEventExtendedDataRecord, operation=ASR42_EvtInfo_EVENT_DFLASH_MEM_CORRUPT.GetEventExtendedDataRecord
        ASR42_EV_GetDebouncingOfEvent_EvtEVENT_DFLASH_MEM_CORRUPT: start-on-event=RE_GetDebouncingOfEvent, operation=ASR42_EvtInfo_EVENT_DFLASH_MEM_CORRUPT.GetDebouncingOfEvent
        ASR42_EV_GetEventFFEx_EvtEVENT_DFLASH_MEM_CORRUPT: start-on-event=RE_GetEventFreezeFrameDataEx, operation=ASR42_EvtInfo_EVENT_DFLASH_MEM_CORRUPT.GetEventFreezeFrameDataEx
        ASR42_EV_GetEventEDREx_EvtEVENT_DFLASH_MEM_CORRUPT: start-on-event=RE_GetEventExtendedDataRecordEx, operation=ASR42_EvtInfo_EVENT_DFLASH_MEM_CORRUPT.GetEventExtendedDataRecordEx
        ASR42_EV_SetEventStatus_EvtEVENT_SBC_STATUS_FAILURE: start-on-event=RE_SetEventStatus, operation=ASR42_Event_EVENT_SBC_STATUS_FAILURE.SetEventStatus
        ASR42_EV_ResetEventStatus_EvtEVENT_SBC_STATUS_FAILURE: start-on-event=RE_ResetEventStatus, operation=ASR42_Event_EVENT_SBC_STATUS_FAILURE.ResetEventStatus
        ASR42_EV_PrestoreFreezeFrame_EvtEVENT_SBC_STATUS_FAILURE: start-on-event=RE_PrestoreFreezeFrame, operation=ASR42_Event_EVENT_SBC_STATUS_FAILURE.PrestoreFreezeFrame
        ASR42_EV_ClearPrestoredFF_EvtEVENT_SBC_STATUS_FAILURE: start-on-event=RE_ClearPrestoredFreezeFrame, operation=ASR42_Event_EVENT_SBC_STATUS_FAILURE.ClearPrestoredFreezeFrame
        ASR42_EV_ResetEventDebounceStatus_EvtEVENT_SBC_STATUS_FAILURE: start-on-event=RE_ResetEventDebounceStatus, operation=ASR42_Event_EVENT_SBC_STATUS_FAILURE.ResetEventDebounceStatus
        ASR42_EV_GetEventStatus_EvtEVENT_SBC_STATUS_FAILURE: start-on-event=RE_GetEventStatus, operation=ASR42_EvtInfo_EVENT_SBC_STATUS_FAILURE.GetEventStatus
        ASR42_EV_GetEventFailed_EvtEVENT_SBC_STATUS_FAILURE: start-on-event=RE_GetEventFailed, operation=ASR42_EvtInfo_EVENT_SBC_STATUS_FAILURE.GetEventFailed
        ASR42_EV_GetEventTested_EvtEVENT_SBC_STATUS_FAILURE: start-on-event=RE_GetEventTested, operation=ASR42_EvtInfo_EVENT_SBC_STATUS_FAILURE.GetEventTested
        ASR42_EV_GetDTCOfEvent_EvtEVENT_SBC_STATUS_FAILURE: start-on-event=RE_GetDTCOfEvent, operation=ASR42_EvtInfo_EVENT_SBC_STATUS_FAILURE.GetDTCOfEvent
        ASR42_EV_GetFDC_EvtEVENT_SBC_STATUS_FAILURE: start-on-event=RE_GetFaultDetectionCounter, operation=ASR42_EvtInfo_EVENT_SBC_STATUS_FAILURE.GetFaultDetectionCounter
        ASR42_EV_GetEventFF_EvtEVENT_SBC_STATUS_FAILURE: start-on-event=RE_GetEventFreezeFrameData, operation=ASR42_EvtInfo_EVENT_SBC_STATUS_FAILURE.GetEventFreezeFrameData
        ASR42_EV_GetEventEDR_EvtEVENT_SBC_STATUS_FAILURE: start-on-event=RE_GetEventExtendedDataRecord, operation=ASR42_EvtInfo_EVENT_SBC_STATUS_FAILURE.GetEventExtendedDataRecord
        ASR42_EV_GetDebouncingOfEvent_EvtEVENT_SBC_STATUS_FAILURE: start-on-event=RE_GetDebouncingOfEvent, operation=ASR42_EvtInfo_EVENT_SBC_STATUS_FAILURE.GetDebouncingOfEvent
        ASR42_EV_GetEventFFEx_EvtEVENT_SBC_STATUS_FAILURE: start-on-event=RE_GetEventFreezeFrameDataEx, operation=ASR42_EvtInfo_EVENT_SBC_STATUS_FAILURE.GetEventFreezeFrameDataEx
        ASR42_EV_GetEventEDREx_EvtEVENT_SBC_STATUS_FAILURE: start-on-event=RE_GetEventExtendedDataRecordEx, operation=ASR42_EvtInfo_EVENT_SBC_STATUS_FAILURE.GetEventExtendedDataRecordEx
        ASR42_EV_SetEventStatus_EvtEVENT_POWER_SUPPLY_OV: start-on-event=RE_SetEventStatus, operation=ASR42_Event_EVENT_POWER_SUPPLY_OV.SetEventStatus
        ASR42_EV_ResetEventStatus_EvtEVENT_POWER_SUPPLY_OV: start-on-event=RE_ResetEventStatus, operation=ASR42_Event_EVENT_POWER_SUPPLY_OV.ResetEventStatus
        ASR42_EV_PrestoreFreezeFrame_EvtEVENT_POWER_SUPPLY_OV: start-on-event=RE_PrestoreFreezeFrame, operation=ASR42_Event_EVENT_POWER_SUPPLY_OV.PrestoreFreezeFrame
        ASR42_EV_ClearPrestoredFF_EvtEVENT_POWER_SUPPLY_OV: start-on-event=RE_ClearPrestoredFreezeFrame, operation=ASR42_Event_EVENT_POWER_SUPPLY_OV.ClearPrestoredFreezeFrame
        ASR42_EV_ResetEventDebounceStatus_EvtEVENT_POWER_SUPPLY_OV: start-on-event=RE_ResetEventDebounceStatus, operation=ASR42_Event_EVENT_POWER_SUPPLY_OV.ResetEventDebounceStatus
        ASR42_EV_GetEventStatus_EvtEVENT_POWER_SUPPLY_OV: start-on-event=RE_GetEventStatus, operation=ASR42_EvtInfo_EVENT_POWER_SUPPLY_OV.GetEventStatus
        ASR42_EV_GetEventFailed_EvtEVENT_POWER_SUPPLY_OV: start-on-event=RE_GetEventFailed, operation=ASR42_EvtInfo_EVENT_POWER_SUPPLY_OV.GetEventFailed
        ASR42_EV_GetEventTested_EvtEVENT_POWER_SUPPLY_OV: start-on-event=RE_GetEventTested, operation=ASR42_EvtInfo_EVENT_POWER_SUPPLY_OV.GetEventTested
        ASR42_EV_GetDTCOfEvent_EvtEVENT_POWER_SUPPLY_OV: start-on-event=RE_GetDTCOfEvent, operation=ASR42_EvtInfo_EVENT_POWER_SUPPLY_OV.GetDTCOfEvent
        ASR42_EV_GetFDC_EvtEVENT_POWER_SUPPLY_OV: start-on-event=RE_GetFaultDetectionCounter, operation=ASR42_EvtInfo_EVENT_POWER_SUPPLY_OV.GetFaultDetectionCounter
        ASR42_EV_GetEventFF_EvtEVENT_POWER_SUPPLY_OV: start-on-event=RE_GetEventFreezeFrameData, operation=ASR42_EvtInfo_EVENT_POWER_SUPPLY_OV.GetEventFreezeFrameData
        ASR42_EV_GetEventEDR_EvtEVENT_POWER_SUPPLY_OV: start-on-event=RE_GetEventExtendedDataRecord, operation=ASR42_EvtInfo_EVENT_POWER_SUPPLY_OV.GetEventExtendedDataRecord
        ASR42_EV_GetDebouncingOfEvent_EvtEVENT_POWER_SUPPLY_OV: start-on-event=RE_GetDebouncingOfEvent, operation=ASR42_EvtInfo_EVENT_POWER_SUPPLY_OV.GetDebouncingOfEvent
        ASR42_EV_GetEventFFEx_EvtEVENT_POWER_SUPPLY_OV: start-on-event=RE_GetEventFreezeFrameDataEx, operation=ASR42_EvtInfo_EVENT_POWER_SUPPLY_OV.GetEventFreezeFrameDataEx
        ASR42_EV_GetEventEDREx_EvtEVENT_POWER_SUPPLY_OV: start-on-event=RE_GetEventExtendedDataRecordEx, operation=ASR42_EvtInfo_EVENT_POWER_SUPPLY_OV.GetEventExtendedDataRecordEx
        ASR42_EV_SetEventStatus_EvtEVENT_POWER_SUPPLY_UV: start-on-event=RE_SetEventStatus, operation=ASR42_Event_EVENT_POWER_SUPPLY_UV.SetEventStatus
        ASR42_EV_ResetEventStatus_EvtEVENT_POWER_SUPPLY_UV: start-on-event=RE_ResetEventStatus, operation=ASR42_Event_EVENT_POWER_SUPPLY_UV.ResetEventStatus
        ASR42_EV_PrestoreFreezeFrame_EvtEVENT_POWER_SUPPLY_UV: start-on-event=RE_PrestoreFreezeFrame, operation=ASR42_Event_EVENT_POWER_SUPPLY_UV.PrestoreFreezeFrame
        ASR42_EV_ClearPrestoredFF_EvtEVENT_POWER_SUPPLY_UV: start-on-event=RE_ClearPrestoredFreezeFrame, operation=ASR42_Event_EVENT_POWER_SUPPLY_UV.ClearPrestoredFreezeFrame
        ASR42_EV_ResetEventDebounceStatus_EvtEVENT_POWER_SUPPLY_UV: start-on-event=RE_ResetEventDebounceStatus, operation=ASR42_Event_EVENT_POWER_SUPPLY_UV.ResetEventDebounceStatus
        ASR42_EV_GetEventStatus_EvtEVENT_POWER_SUPPLY_UV: start-on-event=RE_GetEventStatus, operation=ASR42_EvtInfo_EVENT_POWER_SUPPLY_UV.GetEventStatus
        ASR42_EV_GetEventFailed_EvtEVENT_POWER_SUPPLY_UV: start-on-event=RE_GetEventFailed, operation=ASR42_EvtInfo_EVENT_POWER_SUPPLY_UV.GetEventFailed
        ASR42_EV_GetEventTested_EvtEVENT_POWER_SUPPLY_UV: start-on-event=RE_GetEventTested, operation=ASR42_EvtInfo_EVENT_POWER_SUPPLY_UV.GetEventTested
        ASR42_EV_GetDTCOfEvent_EvtEVENT_POWER_SUPPLY_UV: start-on-event=RE_GetDTCOfEvent, operation=ASR42_EvtInfo_EVENT_POWER_SUPPLY_UV.GetDTCOfEvent
        ASR42_EV_GetFDC_EvtEVENT_POWER_SUPPLY_UV: start-on-event=RE_GetFaultDetectionCounter, operation=ASR42_EvtInfo_EVENT_POWER_SUPPLY_UV.GetFaultDetectionCounter
        ASR42_EV_GetEventFF_EvtEVENT_POWER_SUPPLY_UV: start-on-event=RE_GetEventFreezeFrameData, operation=ASR42_EvtInfo_EVENT_POWER_SUPPLY_UV.GetEventFreezeFrameData
        ASR42_EV_GetEventEDR_EvtEVENT_POWER_SUPPLY_UV: start-on-event=RE_GetEventExtendedDataRecord, operation=ASR42_EvtInfo_EVENT_POWER_SUPPLY_UV.GetEventExtendedDataRecord
        ASR42_EV_GetDebouncingOfEvent_EvtEVENT_POWER_SUPPLY_UV: start-on-event=RE_GetDebouncingOfEvent, operation=ASR42_EvtInfo_EVENT_POWER_SUPPLY_UV.GetDebouncingOfEvent
        ASR42_EV_GetEventFFEx_EvtEVENT_POWER_SUPPLY_UV: start-on-event=RE_GetEventFreezeFrameDataEx, operation=ASR42_EvtInfo_EVENT_POWER_SUPPLY_UV.GetEventFreezeFrameDataEx
        ASR42_EV_GetEventEDREx_EvtEVENT_POWER_SUPPLY_UV: start-on-event=RE_GetEventExtendedDataRecordEx, operation=ASR42_EvtInfo_EVENT_POWER_SUPPLY_UV.GetEventExtendedDataRecordEx
        ASR42_EV_SetEventStatus_EvtEVENT_ACTUATOR_STATUS: start-on-event=RE_SetEventStatus, operation=ASR42_Event_EVENT_ACTUATOR_STATUS.SetEventStatus
        ASR42_EV_ResetEventStatus_EvtEVENT_ACTUATOR_STATUS: start-on-event=RE_ResetEventStatus, operation=ASR42_Event_EVENT_ACTUATOR_STATUS.ResetEventStatus
        ASR42_EV_PrestoreFreezeFrame_EvtEVENT_ACTUATOR_STATUS: start-on-event=RE_PrestoreFreezeFrame, operation=ASR42_Event_EVENT_ACTUATOR_STATUS.PrestoreFreezeFrame
        ASR42_EV_ClearPrestoredFF_EvtEVENT_ACTUATOR_STATUS: start-on-event=RE_ClearPrestoredFreezeFrame, operation=ASR42_Event_EVENT_ACTUATOR_STATUS.ClearPrestoredFreezeFrame
        ASR42_EV_ResetEventDebounceStatus_EvtEVENT_ACTUATOR_STATUS: start-on-event=RE_ResetEventDebounceStatus, operation=ASR42_Event_EVENT_ACTUATOR_STATUS.ResetEventDebounceStatus
        ASR42_EV_GetEventStatus_EvtEVENT_ACTUATOR_STATUS: start-on-event=RE_GetEventStatus, operation=ASR42_EvtInfo_EVENT_ACTUATOR_STATUS.GetEventStatus
        ASR42_EV_GetEventFailed_EvtEVENT_ACTUATOR_STATUS: start-on-event=RE_GetEventFailed, operation=ASR42_EvtInfo_EVENT_ACTUATOR_STATUS.GetEventFailed
        ASR42_EV_GetEventTested_EvtEVENT_ACTUATOR_STATUS: start-on-event=RE_GetEventTested, operation=ASR42_EvtInfo_EVENT_ACTUATOR_STATUS.GetEventTested
        ASR42_EV_GetDTCOfEvent_EvtEVENT_ACTUATOR_STATUS: start-on-event=RE_GetDTCOfEvent, operation=ASR42_EvtInfo_EVENT_ACTUATOR_STATUS.GetDTCOfEvent
        ASR42_EV_GetFDC_EvtEVENT_ACTUATOR_STATUS: start-on-event=RE_GetFaultDetectionCounter, operation=ASR42_EvtInfo_EVENT_ACTUATOR_STATUS.GetFaultDetectionCounter
        ASR42_EV_GetEventFF_EvtEVENT_ACTUATOR_STATUS: start-on-event=RE_GetEventFreezeFrameData, operation=ASR42_EvtInfo_EVENT_ACTUATOR_STATUS.GetEventFreezeFrameData
        ASR42_EV_GetEventEDR_EvtEVENT_ACTUATOR_STATUS: start-on-event=RE_GetEventExtendedDataRecord, operation=ASR42_EvtInfo_EVENT_ACTUATOR_STATUS.GetEventExtendedDataRecord
        ASR42_EV_GetDebouncingOfEvent_EvtEVENT_ACTUATOR_STATUS: start-on-event=RE_GetDebouncingOfEvent, operation=ASR42_EvtInfo_EVENT_ACTUATOR_STATUS.GetDebouncingOfEvent
        ASR42_EV_GetEventFFEx_EvtEVENT_ACTUATOR_STATUS: start-on-event=RE_GetEventFreezeFrameDataEx, operation=ASR42_EvtInfo_EVENT_ACTUATOR_STATUS.GetEventFreezeFrameDataEx
        ASR42_EV_GetEventEDREx_EvtEVENT_ACTUATOR_STATUS: start-on-event=RE_GetEventExtendedDataRecordEx, operation=ASR42_EvtInfo_EVENT_ACTUATOR_STATUS.GetEventExtendedDataRecordEx
        ASR42_EV_SetEventStatus_EvtEVENT_MCU_SELFTEST: start-on-event=RE_SetEventStatus, operation=ASR42_Event_EVENT_MCU_SELFTEST.SetEventStatus
        ASR42_EV_ResetEventStatus_EvtEVENT_MCU_SELFTEST: start-on-event=RE_ResetEventStatus, operation=ASR42_Event_EVENT_MCU_SELFTEST.ResetEventStatus
        ASR42_EV_PrestoreFreezeFrame_EvtEVENT_MCU_SELFTEST: start-on-event=RE_PrestoreFreezeFrame, operation=ASR42_Event_EVENT_MCU_SELFTEST.PrestoreFreezeFrame
        ASR42_EV_ClearPrestoredFF_EvtEVENT_MCU_SELFTEST: start-on-event=RE_ClearPrestoredFreezeFrame, operation=ASR42_Event_EVENT_MCU_SELFTEST.ClearPrestoredFreezeFrame
        ASR42_EV_ResetEventDebounceStatus_EvtEVENT_MCU_SELFTEST: start-on-event=RE_ResetEventDebounceStatus, operation=ASR42_Event_EVENT_MCU_SELFTEST.ResetEventDebounceStatus
        ASR42_EV_GetEventStatus_EvtEVENT_MCU_SELFTEST: start-on-event=RE_GetEventStatus, operation=ASR42_EvtInfo_EVENT_MCU_SELFTEST.GetEventStatus
        ASR42_EV_GetEventFailed_EvtEVENT_MCU_SELFTEST: start-on-event=RE_GetEventFailed, operation=ASR42_EvtInfo_EVENT_MCU_SELFTEST.GetEventFailed
        ASR42_EV_GetEventTested_EvtEVENT_MCU_SELFTEST: start-on-event=RE_GetEventTested, operation=ASR42_EvtInfo_EVENT_MCU_SELFTEST.GetEventTested
        ASR42_EV_GetDTCOfEvent_EvtEVENT_MCU_SELFTEST: start-on-event=RE_GetDTCOfEvent, operation=ASR42_EvtInfo_EVENT_MCU_SELFTEST.GetDTCOfEvent
        ASR42_EV_GetFDC_EvtEVENT_MCU_SELFTEST: start-on-event=RE_GetFaultDetectionCounter, operation=ASR42_EvtInfo_EVENT_MCU_SELFTEST.GetFaultDetectionCounter
        ASR42_EV_GetEventFF_EvtEVENT_MCU_SELFTEST: start-on-event=RE_GetEventFreezeFrameData, operation=ASR42_EvtInfo_EVENT_MCU_SELFTEST.GetEventFreezeFrameData
        ASR42_EV_GetEventEDR_EvtEVENT_MCU_SELFTEST: start-on-event=RE_GetEventExtendedDataRecord, operation=ASR42_EvtInfo_EVENT_MCU_SELFTEST.GetEventExtendedDataRecord
        ASR42_EV_GetDebouncingOfEvent_EvtEVENT_MCU_SELFTEST: start-on-event=RE_GetDebouncingOfEvent, operation=ASR42_EvtInfo_EVENT_MCU_SELFTEST.GetDebouncingOfEvent
        ASR42_EV_GetEventFFEx_EvtEVENT_MCU_SELFTEST: start-on-event=RE_GetEventFreezeFrameDataEx, operation=ASR42_EvtInfo_EVENT_MCU_SELFTEST.GetEventFreezeFrameDataEx
        ASR42_EV_GetEventEDREx_EvtEVENT_MCU_SELFTEST: start-on-event=RE_GetEventExtendedDataRecordEx, operation=ASR42_EvtInfo_EVENT_MCU_SELFTEST.GetEventExtendedDataRecordEx
        ASR42_EV_SetEventStatus_EvtEVENT_ACTUATOR_OPEN_CIRCUIT: start-on-event=RE_SetEventStatus, operation=ASR42_Event_EVENT_ACTUATOR_OPEN_CIRCUIT.SetEventStatus
        ASR42_EV_ResetEventStatus_EvtEVENT_ACTUATOR_OPEN_CIRCUIT: start-on-event=RE_ResetEventStatus, operation=ASR42_Event_EVENT_ACTUATOR_OPEN_CIRCUIT.ResetEventStatus
        ASR42_EV_PrestoreFreezeFrame_EvtEVENT_ACTUATOR_OPEN_CIRCUIT: start-on-event=RE_PrestoreFreezeFrame, operation=ASR42_Event_EVENT_ACTUATOR_OPEN_CIRCUIT.PrestoreFreezeFrame
        ASR42_EV_ClearPrestoredFF_EvtEVENT_ACTUATOR_OPEN_CIRCUIT: start-on-event=RE_ClearPrestoredFreezeFrame, operation=ASR42_Event_EVENT_ACTUATOR_OPEN_CIRCUIT.ClearPrestoredFreezeFrame
        ASR42_EV_ResetEventDebounceStatus_EvtEVENT_ACTUATOR_OPEN_CIRCUIT: start-on-event=RE_ResetEventDebounceStatus, operation=ASR42_Event_EVENT_ACTUATOR_OPEN_CIRCUIT.ResetEventDebounceStatus
        ASR42_EV_GetEventStatus_EvtEVENT_ACTUATOR_OPEN_CIRCUIT: start-on-event=RE_GetEventStatus, operation=ASR42_EvtInfo_EVENT_ACTUATOR_OPEN_CIRCUIT.GetEventStatus
        ASR42_EV_GetEventFailed_EvtEVENT_ACTUATOR_OPEN_CIRCUIT: start-on-event=RE_GetEventFailed, operation=ASR42_EvtInfo_EVENT_ACTUATOR_OPEN_CIRCUIT.GetEventFailed
        ASR42_EV_GetEventTested_EvtEVENT_ACTUATOR_OPEN_CIRCUIT: start-on-event=RE_GetEventTested, operation=ASR42_EvtInfo_EVENT_ACTUATOR_OPEN_CIRCUIT.GetEventTested
        ASR42_EV_GetDTCOfEvent_EvtEVENT_ACTUATOR_OPEN_CIRCUIT: start-on-event=RE_GetDTCOfEvent, operation=ASR42_EvtInfo_EVENT_ACTUATOR_OPEN_CIRCUIT.GetDTCOfEvent
        ASR42_EV_GetFDC_EvtEVENT_ACTUATOR_OPEN_CIRCUIT: start-on-event=RE_GetFaultDetectionCounter, operation=ASR42_EvtInfo_EVENT_ACTUATOR_OPEN_CIRCUIT.GetFaultDetectionCounter
        ASR42_EV_GetEventFF_EvtEVENT_ACTUATOR_OPEN_CIRCUIT: start-on-event=RE_GetEventFreezeFrameData, operation=ASR42_EvtInfo_EVENT_ACTUATOR_OPEN_CIRCUIT.GetEventFreezeFrameData
        ASR42_EV_GetEventEDR_EvtEVENT_ACTUATOR_OPEN_CIRCUIT: start-on-event=RE_GetEventExtendedDataRecord, operation=ASR42_EvtInfo_EVENT_ACTUATOR_OPEN_CIRCUIT.GetEventExtendedDataRecord
        ASR42_EV_GetDebouncingOfEvent_EvtEVENT_ACTUATOR_OPEN_CIRCUIT: start-on-event=RE_GetDebouncingOfEvent, operation=ASR42_EvtInfo_EVENT_ACTUATOR_OPEN_CIRCUIT.GetDebouncingOfEvent
        ASR42_EV_GetEventFFEx_EvtEVENT_ACTUATOR_OPEN_CIRCUIT: start-on-event=RE_GetEventFreezeFrameDataEx, operation=ASR42_EvtInfo_EVENT_ACTUATOR_OPEN_CIRCUIT.GetEventFreezeFrameDataEx
        ASR42_EV_GetEventEDREx_EvtEVENT_ACTUATOR_OPEN_CIRCUIT: start-on-event=RE_GetEventExtendedDataRecordEx, operation=ASR42_EvtInfo_EVENT_ACTUATOR_OPEN_CIRCUIT.GetEventExtendedDataRecordEx
        ASR42_EV_SetEventStatus_EvtEVENT_ACTUATOR_SHORT_TO_GND: start-on-event=RE_SetEventStatus, operation=ASR42_Event_EVENT_ACTUATOR_SHORT_TO_GND.SetEventStatus
        ASR42_EV_ResetEventStatus_EvtEVENT_ACTUATOR_SHORT_TO_GND: start-on-event=RE_ResetEventStatus, operation=ASR42_Event_EVENT_ACTUATOR_SHORT_TO_GND.ResetEventStatus
        ASR42_EV_PrestoreFreezeFrame_EvtEVENT_ACTUATOR_SHORT_TO_GND: start-on-event=RE_PrestoreFreezeFrame, operation=ASR42_Event_EVENT_ACTUATOR_SHORT_TO_GND.PrestoreFreezeFrame
        ASR42_EV_ClearPrestoredFF_EvtEVENT_ACTUATOR_SHORT_TO_GND: start-on-event=RE_ClearPrestoredFreezeFrame, operation=ASR42_Event_EVENT_ACTUATOR_SHORT_TO_GND.ClearPrestoredFreezeFrame
        ASR42_EV_ResetEventDebounceStatus_EvtEVENT_ACTUATOR_SHORT_TO_GND: start-on-event=RE_ResetEventDebounceStatus, operation=ASR42_Event_EVENT_ACTUATOR_SHORT_TO_GND.ResetEventDebounceStatus
        ASR42_EV_GetEventStatus_EvtEVENT_ACTUATOR_SHORT_TO_GND: start-on-event=RE_GetEventStatus, operation=ASR42_EvtInfo_EVENT_ACTUATOR_SHORT_TO_GND.GetEventStatus
        ASR42_EV_GetEventFailed_EvtEVENT_ACTUATOR_SHORT_TO_GND: start-on-event=RE_GetEventFailed, operation=ASR42_EvtInfo_EVENT_ACTUATOR_SHORT_TO_GND.GetEventFailed
        ASR42_EV_GetEventTested_EvtEVENT_ACTUATOR_SHORT_TO_GND: start-on-event=RE_GetEventTested, operation=ASR42_EvtInfo_EVENT_ACTUATOR_SHORT_TO_GND.GetEventTested
        ASR42_EV_GetDTCOfEvent_EvtEVENT_ACTUATOR_SHORT_TO_GND: start-on-event=RE_GetDTCOfEvent, operation=ASR42_EvtInfo_EVENT_ACTUATOR_SHORT_TO_GND.GetDTCOfEvent
        ASR42_EV_GetFDC_EvtEVENT_ACTUATOR_SHORT_TO_GND: start-on-event=RE_GetFaultDetectionCounter, operation=ASR42_EvtInfo_EVENT_ACTUATOR_SHORT_TO_GND.GetFaultDetectionCounter
        ASR42_EV_GetEventFF_EvtEVENT_ACTUATOR_SHORT_TO_GND: start-on-event=RE_GetEventFreezeFrameData, operation=ASR42_EvtInfo_EVENT_ACTUATOR_SHORT_TO_GND.GetEventFreezeFrameData
        ASR42_EV_GetEventEDR_EvtEVENT_ACTUATOR_SHORT_TO_GND: start-on-event=RE_GetEventExtendedDataRecord, operation=ASR42_EvtInfo_EVENT_ACTUATOR_SHORT_TO_GND.GetEventExtendedDataRecord
        ASR42_EV_GetDebouncingOfEvent_EvtEVENT_ACTUATOR_SHORT_TO_GND: start-on-event=RE_GetDebouncingOfEvent, operation=ASR42_EvtInfo_EVENT_ACTUATOR_SHORT_TO_GND.GetDebouncingOfEvent
        ASR42_EV_GetEventFFEx_EvtEVENT_ACTUATOR_SHORT_TO_GND: start-on-event=RE_GetEventFreezeFrameDataEx, operation=ASR42_EvtInfo_EVENT_ACTUATOR_SHORT_TO_GND.GetEventFreezeFrameDataEx
        ASR42_EV_GetEventEDREx_EvtEVENT_ACTUATOR_SHORT_TO_GND: start-on-event=RE_GetEventExtendedDataRecordEx, operation=ASR42_EvtInfo_EVENT_ACTUATOR_SHORT_TO_GND.GetEventExtendedDataRecordEx
        ASR42_EV_SetEventStatus_EvtEVENT_ACTUATOR_SHORT_TO_VBAT: start-on-event=RE_SetEventStatus, operation=ASR42_Event_EVENT_ACTUATOR_SHORT_TO_VBAT.SetEventStatus
        ASR42_EV_ResetEventStatus_EvtEVENT_ACTUATOR_SHORT_TO_VBAT: start-on-event=RE_ResetEventStatus, operation=ASR42_Event_EVENT_ACTUATOR_SHORT_TO_VBAT.ResetEventStatus
        ASR42_EV_PrestoreFreezeFrame_EvtEVENT_ACTUATOR_SHORT_TO_VBAT: start-on-event=RE_PrestoreFreezeFrame, operation=ASR42_Event_EVENT_ACTUATOR_SHORT_TO_VBAT.PrestoreFreezeFrame
        ASR42_EV_ClearPrestoredFF_EvtEVENT_ACTUATOR_SHORT_TO_VBAT: start-on-event=RE_ClearPrestoredFreezeFrame, operation=ASR42_Event_EVENT_ACTUATOR_SHORT_TO_VBAT.ClearPrestoredFreezeFrame
        ASR42_EV_ResetEventDebounceStatus_EvtEVENT_ACTUATOR_SHORT_TO_VBAT: start-on-event=RE_ResetEventDebounceStatus, operation=ASR42_Event_EVENT_ACTUATOR_SHORT_TO_VBAT.ResetEventDebounceStatus
        ASR42_EV_GetEventStatus_EvtEVENT_ACTUATOR_SHORT_TO_VBAT: start-on-event=RE_GetEventStatus, operation=ASR42_EvtInfo_EVENT_ACTUATOR_SHORT_TO_VBAT.GetEventStatus
        ASR42_EV_GetEventFailed_EvtEVENT_ACTUATOR_SHORT_TO_VBAT: start-on-event=RE_GetEventFailed, operation=ASR42_EvtInfo_EVENT_ACTUATOR_SHORT_TO_VBAT.GetEventFailed
        ASR42_EV_GetEventTested_EvtEVENT_ACTUATOR_SHORT_TO_VBAT: start-on-event=RE_GetEventTested, operation=ASR42_EvtInfo_EVENT_ACTUATOR_SHORT_TO_VBAT.GetEventTested
        ASR42_EV_GetDTCOfEvent_EvtEVENT_ACTUATOR_SHORT_TO_VBAT: start-on-event=RE_GetDTCOfEvent, operation=ASR42_EvtInfo_EVENT_ACTUATOR_SHORT_TO_VBAT.GetDTCOfEvent
        ASR42_EV_GetFDC_EvtEVENT_ACTUATOR_SHORT_TO_VBAT: start-on-event=RE_GetFaultDetectionCounter, operation=ASR42_EvtInfo_EVENT_ACTUATOR_SHORT_TO_VBAT.GetFaultDetectionCounter
        ASR42_EV_GetEventFF_EvtEVENT_ACTUATOR_SHORT_TO_VBAT: start-on-event=RE_GetEventFreezeFrameData, operation=ASR42_EvtInfo_EVENT_ACTUATOR_SHORT_TO_VBAT.GetEventFreezeFrameData
        ASR42_EV_GetEventEDR_EvtEVENT_ACTUATOR_SHORT_TO_VBAT: start-on-event=RE_GetEventExtendedDataRecord, operation=ASR42_EvtInfo_EVENT_ACTUATOR_SHORT_TO_VBAT.GetEventExtendedDataRecord
        ASR42_EV_GetDebouncingOfEvent_EvtEVENT_ACTUATOR_SHORT_TO_VBAT: start-on-event=RE_GetDebouncingOfEvent, operation=ASR42_EvtInfo_EVENT_ACTUATOR_SHORT_TO_VBAT.GetDebouncingOfEvent
        ASR42_EV_GetEventFFEx_EvtEVENT_ACTUATOR_SHORT_TO_VBAT: start-on-event=RE_GetEventFreezeFrameDataEx, operation=ASR42_EvtInfo_EVENT_ACTUATOR_SHORT_TO_VBAT.GetEventFreezeFrameDataEx
        ASR42_EV_GetEventEDREx_EvtEVENT_ACTUATOR_SHORT_TO_VBAT: start-on-event=RE_GetEventExtendedDataRecordEx, operation=ASR42_EvtInfo_EVENT_ACTUATOR_SHORT_TO_VBAT.GetEventExtendedDataRecordEx
        ASR42_EV_SetEventStatus_EvtEVENT_ACC_STATUS_FAILURE: start-on-event=RE_SetEventStatus, operation=ASR42_Event_EVENT_ACC_STATUS_FAILURE.SetEventStatus
        ASR42_EV_ResetEventStatus_EvtEVENT_ACC_STATUS_FAILURE: start-on-event=RE_ResetEventStatus, operation=ASR42_Event_EVENT_ACC_STATUS_FAILURE.ResetEventStatus
        ASR42_EV_PrestoreFreezeFrame_EvtEVENT_ACC_STATUS_FAILURE: start-on-event=RE_PrestoreFreezeFrame, operation=ASR42_Event_EVENT_ACC_STATUS_FAILURE.PrestoreFreezeFrame
        ASR42_EV_ClearPrestoredFF_EvtEVENT_ACC_STATUS_FAILURE: start-on-event=RE_ClearPrestoredFreezeFrame, operation=ASR42_Event_EVENT_ACC_STATUS_FAILURE.ClearPrestoredFreezeFrame
        ASR42_EV_ResetEventDebounceStatus_EvtEVENT_ACC_STATUS_FAILURE: start-on-event=RE_ResetEventDebounceStatus, operation=ASR42_Event_EVENT_ACC_STATUS_FAILURE.ResetEventDebounceStatus
        ASR42_EV_GetEventStatus_EvtEVENT_ACC_STATUS_FAILURE: start-on-event=RE_GetEventStatus, operation=ASR42_EvtInfo_EVENT_ACC_STATUS_FAILURE.GetEventStatus
        ASR42_EV_GetEventFailed_EvtEVENT_ACC_STATUS_FAILURE: start-on-event=RE_GetEventFailed, operation=ASR42_EvtInfo_EVENT_ACC_STATUS_FAILURE.GetEventFailed
        ASR42_EV_GetEventTested_EvtEVENT_ACC_STATUS_FAILURE: start-on-event=RE_GetEventTested, operation=ASR42_EvtInfo_EVENT_ACC_STATUS_FAILURE.GetEventTested
        ASR42_EV_GetDTCOfEvent_EvtEVENT_ACC_STATUS_FAILURE: start-on-event=RE_GetDTCOfEvent, operation=ASR42_EvtInfo_EVENT_ACC_STATUS_FAILURE.GetDTCOfEvent
        ASR42_EV_GetFDC_EvtEVENT_ACC_STATUS_FAILURE: start-on-event=RE_GetFaultDetectionCounter, operation=ASR42_EvtInfo_EVENT_ACC_STATUS_FAILURE.GetFaultDetectionCounter
        ASR42_EV_GetEventFF_EvtEVENT_ACC_STATUS_FAILURE: start-on-event=RE_GetEventFreezeFrameData, operation=ASR42_EvtInfo_EVENT_ACC_STATUS_FAILURE.GetEventFreezeFrameData
        ASR42_EV_GetEventEDR_EvtEVENT_ACC_STATUS_FAILURE: start-on-event=RE_GetEventExtendedDataRecord, operation=ASR42_EvtInfo_EVENT_ACC_STATUS_FAILURE.GetEventExtendedDataRecord
        ASR42_EV_GetDebouncingOfEvent_EvtEVENT_ACC_STATUS_FAILURE: start-on-event=RE_GetDebouncingOfEvent, operation=ASR42_EvtInfo_EVENT_ACC_STATUS_FAILURE.GetDebouncingOfEvent
        ASR42_EV_GetEventFFEx_EvtEVENT_ACC_STATUS_FAILURE: start-on-event=RE_GetEventFreezeFrameDataEx, operation=ASR42_EvtInfo_EVENT_ACC_STATUS_FAILURE.GetEventFreezeFrameDataEx
        ASR42_EV_GetEventEDREx_EvtEVENT_ACC_STATUS_FAILURE: start-on-event=RE_GetEventExtendedDataRecordEx, operation=ASR42_EvtInfo_EVENT_ACC_STATUS_FAILURE.GetEventExtendedDataRecordEx
        ASR42_EV_GetEventStatus_EvtEVENT_SPI_E_HW_ERROR: start-on-event=RE_GetEventStatus, operation=ASR42_EvtInfo_EVENT_SPI_E_HW_ERROR.GetEventStatus
        ASR42_EV_GetEventFailed_EvtEVENT_SPI_E_HW_ERROR: start-on-event=RE_GetEventFailed, operation=ASR42_EvtInfo_EVENT_SPI_E_HW_ERROR.GetEventFailed
        ASR42_EV_GetEventTested_EvtEVENT_SPI_E_HW_ERROR: start-on-event=RE_GetEventTested, operation=ASR42_EvtInfo_EVENT_SPI_E_HW_ERROR.GetEventTested
        ASR42_EV_GetDTCOfEvent_EvtEVENT_SPI_E_HW_ERROR: start-on-event=RE_GetDTCOfEvent, operation=ASR42_EvtInfo_EVENT_SPI_E_HW_ERROR.GetDTCOfEvent
        ASR42_EV_GetFDC_EvtEVENT_SPI_E_HW_ERROR: start-on-event=RE_GetFaultDetectionCounter, operation=ASR42_EvtInfo_EVENT_SPI_E_HW_ERROR.GetFaultDetectionCounter
        ASR42_EV_GetEventFF_EvtEVENT_SPI_E_HW_ERROR: start-on-event=RE_GetEventFreezeFrameData, operation=ASR42_EvtInfo_EVENT_SPI_E_HW_ERROR.GetEventFreezeFrameData
        ASR42_EV_GetEventEDR_EvtEVENT_SPI_E_HW_ERROR: start-on-event=RE_GetEventExtendedDataRecord, operation=ASR42_EvtInfo_EVENT_SPI_E_HW_ERROR.GetEventExtendedDataRecord
        ASR42_EV_GetDebouncingOfEvent_EvtEVENT_SPI_E_HW_ERROR: start-on-event=RE_GetDebouncingOfEvent, operation=ASR42_EvtInfo_EVENT_SPI_E_HW_ERROR.GetDebouncingOfEvent
        ASR42_EV_GetEventFFEx_EvtEVENT_SPI_E_HW_ERROR: start-on-event=RE_GetEventFreezeFrameDataEx, operation=ASR42_EvtInfo_EVENT_SPI_E_HW_ERROR.GetEventFreezeFrameDataEx
        ASR42_EV_GetEventEDREx_EvtEVENT_SPI_E_HW_ERROR: start-on-event=RE_GetEventExtendedDataRecordEx, operation=ASR42_EvtInfo_EVENT_SPI_E_HW_ERROR.GetEventExtendedDataRecordEx
        ASR42_EV_SetEventStatus_EvtEVENT_SOLENOID_OVERVOLTAGE: start-on-event=RE_SetEventStatus, operation=ASR42_Event_EVENT_SOLENOID_OVERVOLTAGE.SetEventStatus
        ASR42_EV_ResetEventStatus_EvtEVENT_SOLENOID_OVERVOLTAGE: start-on-event=RE_ResetEventStatus, operation=ASR42_Event_EVENT_SOLENOID_OVERVOLTAGE.ResetEventStatus
        ASR42_EV_PrestoreFreezeFrame_EvtEVENT_SOLENOID_OVERVOLTAGE: start-on-event=RE_PrestoreFreezeFrame, operation=ASR42_Event_EVENT_SOLENOID_OVERVOLTAGE.PrestoreFreezeFrame
        ASR42_EV_ClearPrestoredFF_EvtEVENT_SOLENOID_OVERVOLTAGE: start-on-event=RE_ClearPrestoredFreezeFrame, operation=ASR42_Event_EVENT_SOLENOID_OVERVOLTAGE.ClearPrestoredFreezeFrame
        ASR42_EV_ResetEventDebounceStatus_EvtEVENT_SOLENOID_OVERVOLTAGE: start-on-event=RE_ResetEventDebounceStatus, operation=ASR42_Event_EVENT_SOLENOID_OVERVOLTAGE.ResetEventDebounceStatus
        ASR42_EV_GetEventStatus_EvtEVENT_SOLENOID_OVERVOLTAGE: start-on-event=RE_GetEventStatus, operation=ASR42_EvtInfo_EVENT_SOLENOID_OVERVOLTAGE.GetEventStatus
        ASR42_EV_GetEventFailed_EvtEVENT_SOLENOID_OVERVOLTAGE: start-on-event=RE_GetEventFailed, operation=ASR42_EvtInfo_EVENT_SOLENOID_OVERVOLTAGE.GetEventFailed
        ASR42_EV_GetEventTested_EvtEVENT_SOLENOID_OVERVOLTAGE: start-on-event=RE_GetEventTested, operation=ASR42_EvtInfo_EVENT_SOLENOID_OVERVOLTAGE.GetEventTested
        ASR42_EV_GetDTCOfEvent_EvtEVENT_SOLENOID_OVERVOLTAGE: start-on-event=RE_GetDTCOfEvent, operation=ASR42_EvtInfo_EVENT_SOLENOID_OVERVOLTAGE.GetDTCOfEvent
        ASR42_EV_GetFDC_EvtEVENT_SOLENOID_OVERVOLTAGE: start-on-event=RE_GetFaultDetectionCounter, operation=ASR42_EvtInfo_EVENT_SOLENOID_OVERVOLTAGE.GetFaultDetectionCounter
        ASR42_EV_GetEventFF_EvtEVENT_SOLENOID_OVERVOLTAGE: start-on-event=RE_GetEventFreezeFrameData, operation=ASR42_EvtInfo_EVENT_SOLENOID_OVERVOLTAGE.GetEventFreezeFrameData
        ASR42_EV_GetEventEDR_EvtEVENT_SOLENOID_OVERVOLTAGE: start-on-event=RE_GetEventExtendedDataRecord, operation=ASR42_EvtInfo_EVENT_SOLENOID_OVERVOLTAGE.GetEventExtendedDataRecord
        ASR42_EV_GetDebouncingOfEvent_EvtEVENT_SOLENOID_OVERVOLTAGE: start-on-event=RE_GetDebouncingOfEvent, operation=ASR42_EvtInfo_EVENT_SOLENOID_OVERVOLTAGE.GetDebouncingOfEvent
        ASR42_EV_GetEventFFEx_EvtEVENT_SOLENOID_OVERVOLTAGE: start-on-event=RE_GetEventFreezeFrameDataEx, operation=ASR42_EvtInfo_EVENT_SOLENOID_OVERVOLTAGE.GetEventFreezeFrameDataEx
        ASR42_EV_GetEventEDREx_EvtEVENT_SOLENOID_OVERVOLTAGE: start-on-event=RE_GetEventExtendedDataRecordEx, operation=ASR42_EvtInfo_EVENT_SOLENOID_OVERVOLTAGE.GetEventExtendedDataRecordEx
        ASR42_EV_SetEventStatus_EvtEVENT_POWER_STAGE_FAILIURE: start-on-event=RE_SetEventStatus, operation=ASR42_Event_EVENT_POWER_STAGE_FAILIURE.SetEventStatus
        ASR42_EV_ResetEventStatus_EvtEVENT_POWER_STAGE_FAILIURE: start-on-event=RE_ResetEventStatus, operation=ASR42_Event_EVENT_POWER_STAGE_FAILIURE.ResetEventStatus
        ASR42_EV_PrestoreFreezeFrame_EvtEVENT_POWER_STAGE_FAILIURE: start-on-event=RE_PrestoreFreezeFrame, operation=ASR42_Event_EVENT_POWER_STAGE_FAILIURE.PrestoreFreezeFrame
        ASR42_EV_ClearPrestoredFF_EvtEVENT_POWER_STAGE_FAILIURE: start-on-event=RE_ClearPrestoredFreezeFrame, operation=ASR42_Event_EVENT_POWER_STAGE_FAILIURE.ClearPrestoredFreezeFrame
        ASR42_EV_ResetEventDebounceStatus_EvtEVENT_POWER_STAGE_FAILIURE: start-on-event=RE_ResetEventDebounceStatus, operation=ASR42_Event_EVENT_POWER_STAGE_FAILIURE.ResetEventDebounceStatus
        ASR42_EV_GetEventStatus_EvtEVENT_POWER_STAGE_FAILIURE: start-on-event=RE_GetEventStatus, operation=ASR42_EvtInfo_EVENT_POWER_STAGE_FAILIURE.GetEventStatus
        ASR42_EV_GetEventFailed_EvtEVENT_POWER_STAGE_FAILIURE: start-on-event=RE_GetEventFailed, operation=ASR42_EvtInfo_EVENT_POWER_STAGE_FAILIURE.GetEventFailed
        ASR42_EV_GetEventTested_EvtEVENT_POWER_STAGE_FAILIURE: start-on-event=RE_GetEventTested, operation=ASR42_EvtInfo_EVENT_POWER_STAGE_FAILIURE.GetEventTested
        ASR42_EV_GetDTCOfEvent_EvtEVENT_POWER_STAGE_FAILIURE: start-on-event=RE_GetDTCOfEvent, operation=ASR42_EvtInfo_EVENT_POWER_STAGE_FAILIURE.GetDTCOfEvent
        ASR42_EV_GetFDC_EvtEVENT_POWER_STAGE_FAILIURE: start-on-event=RE_GetFaultDetectionCounter, operation=ASR42_EvtInfo_EVENT_POWER_STAGE_FAILIURE.GetFaultDetectionCounter
        ASR42_EV_GetEventFF_EvtEVENT_POWER_STAGE_FAILIURE: start-on-event=RE_GetEventFreezeFrameData, operation=ASR42_EvtInfo_EVENT_POWER_STAGE_FAILIURE.GetEventFreezeFrameData
        ASR42_EV_GetEventEDR_EvtEVENT_POWER_STAGE_FAILIURE: start-on-event=RE_GetEventExtendedDataRecord, operation=ASR42_EvtInfo_EVENT_POWER_STAGE_FAILIURE.GetEventExtendedDataRecord
        ASR42_EV_GetDebouncingOfEvent_EvtEVENT_POWER_STAGE_FAILIURE: start-on-event=RE_GetDebouncingOfEvent, operation=ASR42_EvtInfo_EVENT_POWER_STAGE_FAILIURE.GetDebouncingOfEvent
        ASR42_EV_GetEventFFEx_EvtEVENT_POWER_STAGE_FAILIURE: start-on-event=RE_GetEventFreezeFrameDataEx, operation=ASR42_EvtInfo_EVENT_POWER_STAGE_FAILIURE.GetEventFreezeFrameDataEx
        ASR42_EV_GetEventEDREx_EvtEVENT_POWER_STAGE_FAILIURE: start-on-event=RE_GetEventExtendedDataRecordEx, operation=ASR42_EvtInfo_EVENT_POWER_STAGE_FAILIURE.GetEventExtendedDataRecordEx
        ASR42_EV_SetEventStatus_EvtEVENT_MCU_CRC_REGISTERS: start-on-event=RE_SetEventStatus, operation=ASR42_Event_EVENT_MCU_CRC_REGISTERS.SetEventStatus
        ASR42_EV_ResetEventStatus_EvtEVENT_MCU_CRC_REGISTERS: start-on-event=RE_ResetEventStatus, operation=ASR42_Event_EVENT_MCU_CRC_REGISTERS.ResetEventStatus
        ASR42_EV_PrestoreFreezeFrame_EvtEVENT_MCU_CRC_REGISTERS: start-on-event=RE_PrestoreFreezeFrame, operation=ASR42_Event_EVENT_MCU_CRC_REGISTERS.PrestoreFreezeFrame
        ASR42_EV_ClearPrestoredFF_EvtEVENT_MCU_CRC_REGISTERS: start-on-event=RE_ClearPrestoredFreezeFrame, operation=ASR42_Event_EVENT_MCU_CRC_REGISTERS.ClearPrestoredFreezeFrame
        ASR42_EV_ResetEventDebounceStatus_EvtEVENT_MCU_CRC_REGISTERS: start-on-event=RE_ResetEventDebounceStatus, operation=ASR42_Event_EVENT_MCU_CRC_REGISTERS.ResetEventDebounceStatus
        ASR42_EV_GetEventStatus_EvtEVENT_MCU_CRC_REGISTERS: start-on-event=RE_GetEventStatus, operation=ASR42_EvtInfo_EVENT_MCU_CRC_REGISTERS.GetEventStatus
        ASR42_EV_GetEventFailed_EvtEVENT_MCU_CRC_REGISTERS: start-on-event=RE_GetEventFailed, operation=ASR42_EvtInfo_EVENT_MCU_CRC_REGISTERS.GetEventFailed
        ASR42_EV_GetEventTested_EvtEVENT_MCU_CRC_REGISTERS: start-on-event=RE_GetEventTested, operation=ASR42_EvtInfo_EVENT_MCU_CRC_REGISTERS.GetEventTested
        ASR42_EV_GetDTCOfEvent_EvtEVENT_MCU_CRC_REGISTERS: start-on-event=RE_GetDTCOfEvent, operation=ASR42_EvtInfo_EVENT_MCU_CRC_REGISTERS.GetDTCOfEvent
        ASR42_EV_GetFDC_EvtEVENT_MCU_CRC_REGISTERS: start-on-event=RE_GetFaultDetectionCounter, operation=ASR42_EvtInfo_EVENT_MCU_CRC_REGISTERS.GetFaultDetectionCounter
        ASR42_EV_GetEventFF_EvtEVENT_MCU_CRC_REGISTERS: start-on-event=RE_GetEventFreezeFrameData, operation=ASR42_EvtInfo_EVENT_MCU_CRC_REGISTERS.GetEventFreezeFrameData
        ASR42_EV_GetEventEDR_EvtEVENT_MCU_CRC_REGISTERS: start-on-event=RE_GetEventExtendedDataRecord, operation=ASR42_EvtInfo_EVENT_MCU_CRC_REGISTERS.GetEventExtendedDataRecord
        ASR42_EV_GetDebouncingOfEvent_EvtEVENT_MCU_CRC_REGISTERS: start-on-event=RE_GetDebouncingOfEvent, operation=ASR42_EvtInfo_EVENT_MCU_CRC_REGISTERS.GetDebouncingOfEvent
        ASR42_EV_GetEventFFEx_EvtEVENT_MCU_CRC_REGISTERS: start-on-event=RE_GetEventFreezeFrameDataEx, operation=ASR42_EvtInfo_EVENT_MCU_CRC_REGISTERS.GetEventFreezeFrameDataEx
        ASR42_EV_GetEventEDREx_EvtEVENT_MCU_CRC_REGISTERS: start-on-event=RE_GetEventExtendedDataRecordEx, operation=ASR42_EvtInfo_EVENT_MCU_CRC_REGISTERS.GetEventExtendedDataRecordEx
        ASR42_EV_GetEventStatus_GeneralEvt: start-on-event=RE_GetEventStatus, operation=ASR42_GeneralEvtInfo.GetEventStatus
        ASR42_EV_GetEventFailed_GeneralEvt: start-on-event=RE_GetEventFailed, operation=ASR42_GeneralEvtInfo.GetEventFailed
        ASR42_EV_GetEventTested_GeneralEvt: start-on-event=RE_GetEventTested, operation=ASR42_GeneralEvtInfo.GetEventTested
        ASR42_EV_GetDTCOfEvent_GeneralEvt: start-on-event=RE_GetDTCOfEvent, operation=ASR42_GeneralEvtInfo.GetDTCOfEvent
        ASR42_EV_GetFDC_GeneralEvt: start-on-event=RE_GetFaultDetectionCounter, operation=ASR42_GeneralEvtInfo.GetFaultDetectionCounter
        ASR42_EV_GetEventFF_GeneralEvt: start-on-event=RE_GetEventFreezeFrameData, operation=ASR42_GeneralEvtInfo.GetEventFreezeFrameData
        ASR42_EV_GetEventEDR_GeneralEvt: start-on-event=RE_GetEventExtendedDataRecord, operation=ASR42_GeneralEvtInfo.GetEventExtendedDataRecord
        ASR42_EV_GetDebouncingOfEvent_GeneralEvt: start-on-event=RE_GetDebouncingOfEvent, operation=ASR42_GeneralEvtInfo.GetDebouncingOfEvent
        ASR42_EV_GetEventFFEx_GeneralEvt: start-on-event=RE_GetEventFreezeFrameDataEx, operation=ASR42_GeneralEvtInfo.GetEventFreezeFrameDataEx
        ASR42_EV_GetEventEDREx_GeneralEvt: start-on-event=RE_GetEventExtendedDataRecordEx, operation=ASR42_GeneralEvtInfo.GetEventExtendedDataRecordEx
        ASR42_EV_SetOperationCycleState_OpCycDEM_OPCYC_POWER: start-on-event=RE_SetOperationCycleState, operation=ASR42_OpCycle_DEM_OPCYC_POWER.SetOperationCycleState
        ASR42_EV_SetCycleQualified_OpCycDEM_OPCYC_POWER: start-on-event=RE_SetCycleQualified, operation=ASR42_OpCycle_DEM_OPCYC_POWER.SetCycleQualified
        ASR42_EV_GetEventMemoryOverflow_Primary: start-on-event=RE_GetEventMemoryOverflow, operation=ASR42_OverflowIndPrimaryMemory.GetEventMemoryOverflow
        ASR42_EV_GetNumberOfEventMemoryEntries_Primary: start-on-event=RE_GetNumberOfEventMemoryEntries, operation=ASR42_OverflowIndPrimaryMemory.GetNumberOfEventMemoryEntries
        EV_GetEventStatus_EvtEVENT_CANSM_E_BUS_OFF: start-on-event=RE_GetEventStatus, operation=EvtInfo_EVENT_CANSM_E_BUS_OFF.GetEventStatus
        EV_GetEventFailed_EvtEVENT_CANSM_E_BUS_OFF: start-on-event=RE_GetEventFailed, operation=EvtInfo_EVENT_CANSM_E_BUS_OFF.GetEventFailed
        EV_GetEventTested_EvtEVENT_CANSM_E_BUS_OFF: start-on-event=RE_GetEventTested, operation=EvtInfo_EVENT_CANSM_E_BUS_OFF.GetEventTested
        EV_GetDTCOfEvent_EvtEVENT_CANSM_E_BUS_OFF: start-on-event=RE_GetDTCOfEvent, operation=EvtInfo_EVENT_CANSM_E_BUS_OFF.GetDTCOfEvent
        EV_GetFDC_EvtEVENT_CANSM_E_BUS_OFF: start-on-event=RE_GetFaultDetectionCounter, operation=EvtInfo_EVENT_CANSM_E_BUS_OFF.GetFaultDetectionCounter
        EV_GetEventFF_EvtEVENT_CANSM_E_BUS_OFF: start-on-event=RE_GetEventFreezeFrameData, operation=EvtInfo_EVENT_CANSM_E_BUS_OFF.GetEventFreezeFrameData
        EV_GetEventEDR_EvtEVENT_CANSM_E_BUS_OFF: start-on-event=RE_GetEventExtendedDataRecord, operation=EvtInfo_EVENT_CANSM_E_BUS_OFF.GetEventExtendedDataRecord
        EV_GetDebouncingOfEvent_EvtEVENT_CANSM_E_BUS_OFF: start-on-event=RE_GetDebouncingOfEvent, operation=EvtInfo_EVENT_CANSM_E_BUS_OFF.GetDebouncingOfEvent
        EV_GetEventFFEx_EvtEVENT_CANSM_E_BUS_OFF: start-on-event=RE_GetEventFreezeFrameDataEx, operation=EvtInfo_EVENT_CANSM_E_BUS_OFF.GetEventFreezeFrameDataEx
        EV_GetEventEDREx_EvtEVENT_CANSM_E_BUS_OFF: start-on-event=RE_GetEventExtendedDataRecordEx, operation=EvtInfo_EVENT_CANSM_E_BUS_OFF.GetEventExtendedDataRecordEx
        EV_SetEventStatus_EvtEVENT_ADC_OUT_OF_ORDER: start-on-event=RE_SetEventStatus, operation=Event_EVENT_ADC_OUT_OF_ORDER.SetEventStatus
        EV_ResetEventStatus_EvtEVENT_ADC_OUT_OF_ORDER: start-on-event=RE_ResetEventStatus, operation=Event_EVENT_ADC_OUT_OF_ORDER.ResetEventStatus
        EV_PrestoreFreezeFrame_EvtEVENT_ADC_OUT_OF_ORDER: start-on-event=RE_PrestoreFreezeFrame, operation=Event_EVENT_ADC_OUT_OF_ORDER.PrestoreFreezeFrame
        EV_ClearPrestoredFF_EvtEVENT_ADC_OUT_OF_ORDER: start-on-event=RE_ClearPrestoredFreezeFrame, operation=Event_EVENT_ADC_OUT_OF_ORDER.ClearPrestoredFreezeFrame
        EV_ResetEventDebounceStatus_EvtEVENT_ADC_OUT_OF_ORDER: start-on-event=RE_ResetEventDebounceStatus, operation=Event_EVENT_ADC_OUT_OF_ORDER.ResetEventDebounceStatus
        EV_GetEventStatus_EvtEVENT_ADC_OUT_OF_ORDER: start-on-event=RE_GetEventStatus, operation=EvtInfo_EVENT_ADC_OUT_OF_ORDER.GetEventStatus
        EV_GetEventFailed_EvtEVENT_ADC_OUT_OF_ORDER: start-on-event=RE_GetEventFailed, operation=EvtInfo_EVENT_ADC_OUT_OF_ORDER.GetEventFailed
        EV_GetEventTested_EvtEVENT_ADC_OUT_OF_ORDER: start-on-event=RE_GetEventTested, operation=EvtInfo_EVENT_ADC_OUT_OF_ORDER.GetEventTested
        EV_GetDTCOfEvent_EvtEVENT_ADC_OUT_OF_ORDER: start-on-event=RE_GetDTCOfEvent, operation=EvtInfo_EVENT_ADC_OUT_OF_ORDER.GetDTCOfEvent
        EV_GetFDC_EvtEVENT_ADC_OUT_OF_ORDER: start-on-event=RE_GetFaultDetectionCounter, operation=EvtInfo_EVENT_ADC_OUT_OF_ORDER.GetFaultDetectionCounter
        EV_GetEventFF_EvtEVENT_ADC_OUT_OF_ORDER: start-on-event=RE_GetEventFreezeFrameData, operation=EvtInfo_EVENT_ADC_OUT_OF_ORDER.GetEventFreezeFrameData
        EV_GetEventEDR_EvtEVENT_ADC_OUT_OF_ORDER: start-on-event=RE_GetEventExtendedDataRecord, operation=EvtInfo_EVENT_ADC_OUT_OF_ORDER.GetEventExtendedDataRecord
        EV_GetDebouncingOfEvent_EvtEVENT_ADC_OUT_OF_ORDER: start-on-event=RE_GetDebouncingOfEvent, operation=EvtInfo_EVENT_ADC_OUT_OF_ORDER.GetDebouncingOfEvent
        EV_GetEventFFEx_EvtEVENT_ADC_OUT_OF_ORDER: start-on-event=RE_GetEventFreezeFrameDataEx, operation=EvtInfo_EVENT_ADC_OUT_OF_ORDER.GetEventFreezeFrameDataEx
        EV_GetEventEDREx_EvtEVENT_ADC_OUT_OF_ORDER: start-on-event=RE_GetEventExtendedDataRecordEx, operation=EvtInfo_EVENT_ADC_OUT_OF_ORDER.GetEventExtendedDataRecordEx
        EV_SetEventStatus_EvtEVENT_WARM_RESET: start-on-event=RE_SetEventStatus, operation=Event_EVENT_WARM_RESET.SetEventStatus
        EV_ResetEventStatus_EvtEVENT_WARM_RESET: start-on-event=RE_ResetEventStatus, operation=Event_EVENT_WARM_RESET.ResetEventStatus
        EV_PrestoreFreezeFrame_EvtEVENT_WARM_RESET: start-on-event=RE_PrestoreFreezeFrame, operation=Event_EVENT_WARM_RESET.PrestoreFreezeFrame
        EV_ClearPrestoredFF_EvtEVENT_WARM_RESET: start-on-event=RE_ClearPrestoredFreezeFrame, operation=Event_EVENT_WARM_RESET.ClearPrestoredFreezeFrame
        EV_ResetEventDebounceStatus_EvtEVENT_WARM_RESET: start-on-event=RE_ResetEventDebounceStatus, operation=Event_EVENT_WARM_RESET.ResetEventDebounceStatus
        EV_GetEventStatus_EvtEVENT_WARM_RESET: start-on-event=RE_GetEventStatus, operation=EvtInfo_EVENT_WARM_RESET.GetEventStatus
        EV_GetEventFailed_EvtEVENT_WARM_RESET: start-on-event=RE_GetEventFailed, operation=EvtInfo_EVENT_WARM_RESET.GetEventFailed
        EV_GetEventTested_EvtEVENT_WARM_RESET: start-on-event=RE_GetEventTested, operation=EvtInfo_EVENT_WARM_RESET.GetEventTested
        EV_GetDTCOfEvent_EvtEVENT_WARM_RESET: start-on-event=RE_GetDTCOfEvent, operation=EvtInfo_EVENT_WARM_RESET.GetDTCOfEvent
        EV_GetFDC_EvtEVENT_WARM_RESET: start-on-event=RE_GetFaultDetectionCounter, operation=EvtInfo_EVENT_WARM_RESET.GetFaultDetectionCounter
        EV_GetEventFF_EvtEVENT_WARM_RESET: start-on-event=RE_GetEventFreezeFrameData, operation=EvtInfo_EVENT_WARM_RESET.GetEventFreezeFrameData
        EV_GetEventEDR_EvtEVENT_WARM_RESET: start-on-event=RE_GetEventExtendedDataRecord, operation=EvtInfo_EVENT_WARM_RESET.GetEventExtendedDataRecord
        EV_GetDebouncingOfEvent_EvtEVENT_WARM_RESET: start-on-event=RE_GetDebouncingOfEvent, operation=EvtInfo_EVENT_WARM_RESET.GetDebouncingOfEvent
        EV_GetEventFFEx_EvtEVENT_WARM_RESET: start-on-event=RE_GetEventFreezeFrameDataEx, operation=EvtInfo_EVENT_WARM_RESET.GetEventFreezeFrameDataEx
        EV_GetEventEDREx_EvtEVENT_WARM_RESET: start-on-event=RE_GetEventExtendedDataRecordEx, operation=EvtInfo_EVENT_WARM_RESET.GetEventExtendedDataRecordEx
        EV_SetEventStatus_EvtEVENT_PFLASH_MEM_CORRUPT: start-on-event=RE_SetEventStatus, operation=Event_EVENT_PFLASH_MEM_CORRUPT.SetEventStatus
        EV_ResetEventStatus_EvtEVENT_PFLASH_MEM_CORRUPT: start-on-event=RE_ResetEventStatus, operation=Event_EVENT_PFLASH_MEM_CORRUPT.ResetEventStatus
        EV_PrestoreFreezeFrame_EvtEVENT_PFLASH_MEM_CORRUPT: start-on-event=RE_PrestoreFreezeFrame, operation=Event_EVENT_PFLASH_MEM_CORRUPT.PrestoreFreezeFrame
        EV_ClearPrestoredFF_EvtEVENT_PFLASH_MEM_CORRUPT: start-on-event=RE_ClearPrestoredFreezeFrame, operation=Event_EVENT_PFLASH_MEM_CORRUPT.ClearPrestoredFreezeFrame
        EV_ResetEventDebounceStatus_EvtEVENT_PFLASH_MEM_CORRUPT: start-on-event=RE_ResetEventDebounceStatus, operation=Event_EVENT_PFLASH_MEM_CORRUPT.ResetEventDebounceStatus
        EV_GetEventStatus_EvtEVENT_PFLASH_MEM_CORRUPT: start-on-event=RE_GetEventStatus, operation=EvtInfo_EVENT_PFLASH_MEM_CORRUPT.GetEventStatus
        EV_GetEventFailed_EvtEVENT_PFLASH_MEM_CORRUPT: start-on-event=RE_GetEventFailed, operation=EvtInfo_EVENT_PFLASH_MEM_CORRUPT.GetEventFailed
        EV_GetEventTested_EvtEVENT_PFLASH_MEM_CORRUPT: start-on-event=RE_GetEventTested, operation=EvtInfo_EVENT_PFLASH_MEM_CORRUPT.GetEventTested
        EV_GetDTCOfEvent_EvtEVENT_PFLASH_MEM_CORRUPT: start-on-event=RE_GetDTCOfEvent, operation=EvtInfo_EVENT_PFLASH_MEM_CORRUPT.GetDTCOfEvent
        EV_GetFDC_EvtEVENT_PFLASH_MEM_CORRUPT: start-on-event=RE_GetFaultDetectionCounter, operation=EvtInfo_EVENT_PFLASH_MEM_CORRUPT.GetFaultDetectionCounter
        EV_GetEventFF_EvtEVENT_PFLASH_MEM_CORRUPT: start-on-event=RE_GetEventFreezeFrameData, operation=EvtInfo_EVENT_PFLASH_MEM_CORRUPT.GetEventFreezeFrameData
        EV_GetEventEDR_EvtEVENT_PFLASH_MEM_CORRUPT: start-on-event=RE_GetEventExtendedDataRecord, operation=EvtInfo_EVENT_PFLASH_MEM_CORRUPT.GetEventExtendedDataRecord
        EV_GetDebouncingOfEvent_EvtEVENT_PFLASH_MEM_CORRUPT: start-on-event=RE_GetDebouncingOfEvent, operation=EvtInfo_EVENT_PFLASH_MEM_CORRUPT.GetDebouncingOfEvent
        EV_GetEventFFEx_EvtEVENT_PFLASH_MEM_CORRUPT: start-on-event=RE_GetEventFreezeFrameDataEx, operation=EvtInfo_EVENT_PFLASH_MEM_CORRUPT.GetEventFreezeFrameDataEx
        EV_GetEventEDREx_EvtEVENT_PFLASH_MEM_CORRUPT: start-on-event=RE_GetEventExtendedDataRecordEx, operation=EvtInfo_EVENT_PFLASH_MEM_CORRUPT.GetEventExtendedDataRecordEx
        EV_SetEventStatus_EvtEVENT_EXT_WDG_OUT_OF_ORDER: start-on-event=RE_SetEventStatus, operation=Event_EVENT_EXT_WDG_OUT_OF_ORDER.SetEventStatus
        EV_ResetEventStatus_EvtEVENT_EXT_WDG_OUT_OF_ORDER: start-on-event=RE_ResetEventStatus, operation=Event_EVENT_EXT_WDG_OUT_OF_ORDER.ResetEventStatus
        EV_PrestoreFreezeFrame_EvtEVENT_EXT_WDG_OUT_OF_ORDER: start-on-event=RE_PrestoreFreezeFrame, operation=Event_EVENT_EXT_WDG_OUT_OF_ORDER.PrestoreFreezeFrame
        EV_ClearPrestoredFF_EvtEVENT_EXT_WDG_OUT_OF_ORDER: start-on-event=RE_ClearPrestoredFreezeFrame, operation=Event_EVENT_EXT_WDG_OUT_OF_ORDER.ClearPrestoredFreezeFrame
        EV_ResetEventDebounceStatus_EvtEVENT_EXT_WDG_OUT_OF_ORDER: start-on-event=RE_ResetEventDebounceStatus, operation=Event_EVENT_EXT_WDG_OUT_OF_ORDER.ResetEventDebounceStatus
        EV_GetEventStatus_EvtEVENT_EXT_WDG_OUT_OF_ORDER: start-on-event=RE_GetEventStatus, operation=EvtInfo_EVENT_EXT_WDG_OUT_OF_ORDER.GetEventStatus
        EV_GetEventFailed_EvtEVENT_EXT_WDG_OUT_OF_ORDER: start-on-event=RE_GetEventFailed, operation=EvtInfo_EVENT_EXT_WDG_OUT_OF_ORDER.GetEventFailed
        EV_GetEventTested_EvtEVENT_EXT_WDG_OUT_OF_ORDER: start-on-event=RE_GetEventTested, operation=EvtInfo_EVENT_EXT_WDG_OUT_OF_ORDER.GetEventTested
        EV_GetDTCOfEvent_EvtEVENT_EXT_WDG_OUT_OF_ORDER: start-on-event=RE_GetDTCOfEvent, operation=EvtInfo_EVENT_EXT_WDG_OUT_OF_ORDER.GetDTCOfEvent
        EV_GetFDC_EvtEVENT_EXT_WDG_OUT_OF_ORDER: start-on-event=RE_GetFaultDetectionCounter, operation=EvtInfo_EVENT_EXT_WDG_OUT_OF_ORDER.GetFaultDetectionCounter
        EV_GetEventFF_EvtEVENT_EXT_WDG_OUT_OF_ORDER: start-on-event=RE_GetEventFreezeFrameData, operation=EvtInfo_EVENT_EXT_WDG_OUT_OF_ORDER.GetEventFreezeFrameData
        EV_GetEventEDR_EvtEVENT_EXT_WDG_OUT_OF_ORDER: start-on-event=RE_GetEventExtendedDataRecord, operation=EvtInfo_EVENT_EXT_WDG_OUT_OF_ORDER.GetEventExtendedDataRecord
        EV_GetDebouncingOfEvent_EvtEVENT_EXT_WDG_OUT_OF_ORDER: start-on-event=RE_GetDebouncingOfEvent, operation=EvtInfo_EVENT_EXT_WDG_OUT_OF_ORDER.GetDebouncingOfEvent
        EV_GetEventFFEx_EvtEVENT_EXT_WDG_OUT_OF_ORDER: start-on-event=RE_GetEventFreezeFrameDataEx, operation=EvtInfo_EVENT_EXT_WDG_OUT_OF_ORDER.GetEventFreezeFrameDataEx
        EV_GetEventEDREx_EvtEVENT_EXT_WDG_OUT_OF_ORDER: start-on-event=RE_GetEventExtendedDataRecordEx, operation=EvtInfo_EVENT_EXT_WDG_OUT_OF_ORDER.GetEventExtendedDataRecordEx
        EV_SetEventStatus_EvtEVENT_NVM_NOT_PRG: start-on-event=RE_SetEventStatus, operation=Event_EVENT_NVM_NOT_PRG.SetEventStatus
        EV_ResetEventStatus_EvtEVENT_NVM_NOT_PRG: start-on-event=RE_ResetEventStatus, operation=Event_EVENT_NVM_NOT_PRG.ResetEventStatus
        EV_PrestoreFreezeFrame_EvtEVENT_NVM_NOT_PRG: start-on-event=RE_PrestoreFreezeFrame, operation=Event_EVENT_NVM_NOT_PRG.PrestoreFreezeFrame
        EV_ClearPrestoredFF_EvtEVENT_NVM_NOT_PRG: start-on-event=RE_ClearPrestoredFreezeFrame, operation=Event_EVENT_NVM_NOT_PRG.ClearPrestoredFreezeFrame
        EV_ResetEventDebounceStatus_EvtEVENT_NVM_NOT_PRG: start-on-event=RE_ResetEventDebounceStatus, operation=Event_EVENT_NVM_NOT_PRG.ResetEventDebounceStatus
        EV_GetEventStatus_EvtEVENT_NVM_NOT_PRG: start-on-event=RE_GetEventStatus, operation=EvtInfo_EVENT_NVM_NOT_PRG.GetEventStatus
        EV_GetEventFailed_EvtEVENT_NVM_NOT_PRG: start-on-event=RE_GetEventFailed, operation=EvtInfo_EVENT_NVM_NOT_PRG.GetEventFailed
        EV_GetEventTested_EvtEVENT_NVM_NOT_PRG: start-on-event=RE_GetEventTested, operation=EvtInfo_EVENT_NVM_NOT_PRG.GetEventTested
        EV_GetDTCOfEvent_EvtEVENT_NVM_NOT_PRG: start-on-event=RE_GetDTCOfEvent, operation=EvtInfo_EVENT_NVM_NOT_PRG.GetDTCOfEvent
        EV_GetFDC_EvtEVENT_NVM_NOT_PRG: start-on-event=RE_GetFaultDetectionCounter, operation=EvtInfo_EVENT_NVM_NOT_PRG.GetFaultDetectionCounter
        EV_GetEventFF_EvtEVENT_NVM_NOT_PRG: start-on-event=RE_GetEventFreezeFrameData, operation=EvtInfo_EVENT_NVM_NOT_PRG.GetEventFreezeFrameData
        EV_GetEventEDR_EvtEVENT_NVM_NOT_PRG: start-on-event=RE_GetEventExtendedDataRecord, operation=EvtInfo_EVENT_NVM_NOT_PRG.GetEventExtendedDataRecord
        EV_GetDebouncingOfEvent_EvtEVENT_NVM_NOT_PRG: start-on-event=RE_GetDebouncingOfEvent, operation=EvtInfo_EVENT_NVM_NOT_PRG.GetDebouncingOfEvent
        EV_GetEventFFEx_EvtEVENT_NVM_NOT_PRG: start-on-event=RE_GetEventFreezeFrameDataEx, operation=EvtInfo_EVENT_NVM_NOT_PRG.GetEventFreezeFrameDataEx
        EV_GetEventEDREx_EvtEVENT_NVM_NOT_PRG: start-on-event=RE_GetEventExtendedDataRecordEx, operation=EvtInfo_EVENT_NVM_NOT_PRG.GetEventExtendedDataRecordEx
        EV_SetEventStatus_EvtEVENT_RAM_MEM_CORRUPT: start-on-event=RE_SetEventStatus, operation=Event_EVENT_RAM_MEM_CORRUPT.SetEventStatus
        EV_ResetEventStatus_EvtEVENT_RAM_MEM_CORRUPT: start-on-event=RE_ResetEventStatus, operation=Event_EVENT_RAM_MEM_CORRUPT.ResetEventStatus
        EV_PrestoreFreezeFrame_EvtEVENT_RAM_MEM_CORRUPT: start-on-event=RE_PrestoreFreezeFrame, operation=Event_EVENT_RAM_MEM_CORRUPT.PrestoreFreezeFrame
        EV_ClearPrestoredFF_EvtEVENT_RAM_MEM_CORRUPT: start-on-event=RE_ClearPrestoredFreezeFrame, operation=Event_EVENT_RAM_MEM_CORRUPT.ClearPrestoredFreezeFrame
        EV_ResetEventDebounceStatus_EvtEVENT_RAM_MEM_CORRUPT: start-on-event=RE_ResetEventDebounceStatus, operation=Event_EVENT_RAM_MEM_CORRUPT.ResetEventDebounceStatus
        EV_GetEventStatus_EvtEVENT_RAM_MEM_CORRUPT: start-on-event=RE_GetEventStatus, operation=EvtInfo_EVENT_RAM_MEM_CORRUPT.GetEventStatus
        EV_GetEventFailed_EvtEVENT_RAM_MEM_CORRUPT: start-on-event=RE_GetEventFailed, operation=EvtInfo_EVENT_RAM_MEM_CORRUPT.GetEventFailed
        EV_GetEventTested_EvtEVENT_RAM_MEM_CORRUPT: start-on-event=RE_GetEventTested, operation=EvtInfo_EVENT_RAM_MEM_CORRUPT.GetEventTested
        EV_GetDTCOfEvent_EvtEVENT_RAM_MEM_CORRUPT: start-on-event=RE_GetDTCOfEvent, operation=EvtInfo_EVENT_RAM_MEM_CORRUPT.GetDTCOfEvent
        EV_GetFDC_EvtEVENT_RAM_MEM_CORRUPT: start-on-event=RE_GetFaultDetectionCounter, operation=EvtInfo_EVENT_RAM_MEM_CORRUPT.GetFaultDetectionCounter
        EV_GetEventFF_EvtEVENT_RAM_MEM_CORRUPT: start-on-event=RE_GetEventFreezeFrameData, operation=EvtInfo_EVENT_RAM_MEM_CORRUPT.GetEventFreezeFrameData
        EV_GetEventEDR_EvtEVENT_RAM_MEM_CORRUPT: start-on-event=RE_GetEventExtendedDataRecord, operation=EvtInfo_EVENT_RAM_MEM_CORRUPT.GetEventExtendedDataRecord
        EV_GetDebouncingOfEvent_EvtEVENT_RAM_MEM_CORRUPT: start-on-event=RE_GetDebouncingOfEvent, operation=EvtInfo_EVENT_RAM_MEM_CORRUPT.GetDebouncingOfEvent
        EV_GetEventFFEx_EvtEVENT_RAM_MEM_CORRUPT: start-on-event=RE_GetEventFreezeFrameDataEx, operation=EvtInfo_EVENT_RAM_MEM_CORRUPT.GetEventFreezeFrameDataEx
        EV_GetEventEDREx_EvtEVENT_RAM_MEM_CORRUPT: start-on-event=RE_GetEventExtendedDataRecordEx, operation=EvtInfo_EVENT_RAM_MEM_CORRUPT.GetEventExtendedDataRecordEx
        EV_SetEventStatus_EvtEVENT_ADC_CALIB: start-on-event=RE_SetEventStatus, operation=Event_EVENT_ADC_CALIB.SetEventStatus
        EV_ResetEventStatus_EvtEVENT_ADC_CALIB: start-on-event=RE_ResetEventStatus, operation=Event_EVENT_ADC_CALIB.ResetEventStatus
        EV_PrestoreFreezeFrame_EvtEVENT_ADC_CALIB: start-on-event=RE_PrestoreFreezeFrame, operation=Event_EVENT_ADC_CALIB.PrestoreFreezeFrame
        EV_ClearPrestoredFF_EvtEVENT_ADC_CALIB: start-on-event=RE_ClearPrestoredFreezeFrame, operation=Event_EVENT_ADC_CALIB.ClearPrestoredFreezeFrame
        EV_ResetEventDebounceStatus_EvtEVENT_ADC_CALIB: start-on-event=RE_ResetEventDebounceStatus, operation=Event_EVENT_ADC_CALIB.ResetEventDebounceStatus
        EV_GetEventStatus_EvtEVENT_ADC_CALIB: start-on-event=RE_GetEventStatus, operation=EvtInfo_EVENT_ADC_CALIB.GetEventStatus
        EV_GetEventFailed_EvtEVENT_ADC_CALIB: start-on-event=RE_GetEventFailed, operation=EvtInfo_EVENT_ADC_CALIB.GetEventFailed
        EV_GetEventTested_EvtEVENT_ADC_CALIB: start-on-event=RE_GetEventTested, operation=EvtInfo_EVENT_ADC_CALIB.GetEventTested
        EV_GetDTCOfEvent_EvtEVENT_ADC_CALIB: start-on-event=RE_GetDTCOfEvent, operation=EvtInfo_EVENT_ADC_CALIB.GetDTCOfEvent
        EV_GetFDC_EvtEVENT_ADC_CALIB: start-on-event=RE_GetFaultDetectionCounter, operation=EvtInfo_EVENT_ADC_CALIB.GetFaultDetectionCounter
        EV_GetEventFF_EvtEVENT_ADC_CALIB: start-on-event=RE_GetEventFreezeFrameData, operation=EvtInfo_EVENT_ADC_CALIB.GetEventFreezeFrameData
        EV_GetEventEDR_EvtEVENT_ADC_CALIB: start-on-event=RE_GetEventExtendedDataRecord, operation=EvtInfo_EVENT_ADC_CALIB.GetEventExtendedDataRecord
        EV_GetDebouncingOfEvent_EvtEVENT_ADC_CALIB: start-on-event=RE_GetDebouncingOfEvent, operation=EvtInfo_EVENT_ADC_CALIB.GetDebouncingOfEvent
        EV_GetEventFFEx_EvtEVENT_ADC_CALIB: start-on-event=RE_GetEventFreezeFrameDataEx, operation=EvtInfo_EVENT_ADC_CALIB.GetEventFreezeFrameDataEx
        EV_GetEventEDREx_EvtEVENT_ADC_CALIB: start-on-event=RE_GetEventExtendedDataRecordEx, operation=EvtInfo_EVENT_ADC_CALIB.GetEventExtendedDataRecordEx
        EV_SetEventStatus_EvtEVENT_ECU_OVER_TEMPERATURE: start-on-event=RE_SetEventStatus, operation=Event_EVENT_ECU_OVER_TEMPERATURE.SetEventStatus
        EV_ResetEventStatus_EvtEVENT_ECU_OVER_TEMPERATURE: start-on-event=RE_ResetEventStatus, operation=Event_EVENT_ECU_OVER_TEMPERATURE.ResetEventStatus
        EV_PrestoreFreezeFrame_EvtEVENT_ECU_OVER_TEMPERATURE: start-on-event=RE_PrestoreFreezeFrame, operation=Event_EVENT_ECU_OVER_TEMPERATURE.PrestoreFreezeFrame
        EV_ClearPrestoredFF_EvtEVENT_ECU_OVER_TEMPERATURE: start-on-event=RE_ClearPrestoredFreezeFrame, operation=Event_EVENT_ECU_OVER_TEMPERATURE.ClearPrestoredFreezeFrame
        EV_ResetEventDebounceStatus_EvtEVENT_ECU_OVER_TEMPERATURE: start-on-event=RE_ResetEventDebounceStatus, operation=Event_EVENT_ECU_OVER_TEMPERATURE.ResetEventDebounceStatus
        EV_GetEventStatus_EvtEVENT_ECU_OVER_TEMPERATURE: start-on-event=RE_GetEventStatus, operation=EvtInfo_EVENT_ECU_OVER_TEMPERATURE.GetEventStatus
        EV_GetEventFailed_EvtEVENT_ECU_OVER_TEMPERATURE: start-on-event=RE_GetEventFailed, operation=EvtInfo_EVENT_ECU_OVER_TEMPERATURE.GetEventFailed
        EV_GetEventTested_EvtEVENT_ECU_OVER_TEMPERATURE: start-on-event=RE_GetEventTested, operation=EvtInfo_EVENT_ECU_OVER_TEMPERATURE.GetEventTested
        EV_GetDTCOfEvent_EvtEVENT_ECU_OVER_TEMPERATURE: start-on-event=RE_GetDTCOfEvent, operation=EvtInfo_EVENT_ECU_OVER_TEMPERATURE.GetDTCOfEvent
        EV_GetFDC_EvtEVENT_ECU_OVER_TEMPERATURE: start-on-event=RE_GetFaultDetectionCounter, operation=EvtInfo_EVENT_ECU_OVER_TEMPERATURE.GetFaultDetectionCounter
        EV_GetEventFF_EvtEVENT_ECU_OVER_TEMPERATURE: start-on-event=RE_GetEventFreezeFrameData, operation=EvtInfo_EVENT_ECU_OVER_TEMPERATURE.GetEventFreezeFrameData
        EV_GetEventEDR_EvtEVENT_ECU_OVER_TEMPERATURE: start-on-event=RE_GetEventExtendedDataRecord, operation=EvtInfo_EVENT_ECU_OVER_TEMPERATURE.GetEventExtendedDataRecord
        EV_GetDebouncingOfEvent_EvtEVENT_ECU_OVER_TEMPERATURE: start-on-event=RE_GetDebouncingOfEvent, operation=EvtInfo_EVENT_ECU_OVER_TEMPERATURE.GetDebouncingOfEvent
        EV_GetEventFFEx_EvtEVENT_ECU_OVER_TEMPERATURE: start-on-event=RE_GetEventFreezeFrameDataEx, operation=EvtInfo_EVENT_ECU_OVER_TEMPERATURE.GetEventFreezeFrameDataEx
        EV_GetEventEDREx_EvtEVENT_ECU_OVER_TEMPERATURE: start-on-event=RE_GetEventExtendedDataRecordEx, operation=EvtInfo_EVENT_ECU_OVER_TEMPERATURE.GetEventExtendedDataRecordEx
        EV_SetEventStatus_EvtEVENT_DFLASH_MEM_CORRUPT: start-on-event=RE_SetEventStatus, operation=Event_EVENT_DFLASH_MEM_CORRUPT.SetEventStatus
        EV_ResetEventStatus_EvtEVENT_DFLASH_MEM_CORRUPT: start-on-event=RE_ResetEventStatus, operation=Event_EVENT_DFLASH_MEM_CORRUPT.ResetEventStatus
        EV_PrestoreFreezeFrame_EvtEVENT_DFLASH_MEM_CORRUPT: start-on-event=RE_PrestoreFreezeFrame, operation=Event_EVENT_DFLASH_MEM_CORRUPT.PrestoreFreezeFrame
        EV_ClearPrestoredFF_EvtEVENT_DFLASH_MEM_CORRUPT: start-on-event=RE_ClearPrestoredFreezeFrame, operation=Event_EVENT_DFLASH_MEM_CORRUPT.ClearPrestoredFreezeFrame
        EV_ResetEventDebounceStatus_EvtEVENT_DFLASH_MEM_CORRUPT: start-on-event=RE_ResetEventDebounceStatus, operation=Event_EVENT_DFLASH_MEM_CORRUPT.ResetEventDebounceStatus
        EV_GetEventStatus_EvtEVENT_DFLASH_MEM_CORRUPT: start-on-event=RE_GetEventStatus, operation=EvtInfo_EVENT_DFLASH_MEM_CORRUPT.GetEventStatus
        EV_GetEventFailed_EvtEVENT_DFLASH_MEM_CORRUPT: start-on-event=RE_GetEventFailed, operation=EvtInfo_EVENT_DFLASH_MEM_CORRUPT.GetEventFailed
        EV_GetEventTested_EvtEVENT_DFLASH_MEM_CORRUPT: start-on-event=RE_GetEventTested, operation=EvtInfo_EVENT_DFLASH_MEM_CORRUPT.GetEventTested
        EV_GetDTCOfEvent_EvtEVENT_DFLASH_MEM_CORRUPT: start-on-event=RE_GetDTCOfEvent, operation=EvtInfo_EVENT_DFLASH_MEM_CORRUPT.GetDTCOfEvent
        EV_GetFDC_EvtEVENT_DFLASH_MEM_CORRUPT: start-on-event=RE_GetFaultDetectionCounter, operation=EvtInfo_EVENT_DFLASH_MEM_CORRUPT.GetFaultDetectionCounter
        EV_GetEventFF_EvtEVENT_DFLASH_MEM_CORRUPT: start-on-event=RE_GetEventFreezeFrameData, operation=EvtInfo_EVENT_DFLASH_MEM_CORRUPT.GetEventFreezeFrameData
        EV_GetEventEDR_EvtEVENT_DFLASH_MEM_CORRUPT: start-on-event=RE_GetEventExtendedDataRecord, operation=EvtInfo_EVENT_DFLASH_MEM_CORRUPT.GetEventExtendedDataRecord
        EV_GetDebouncingOfEvent_EvtEVENT_DFLASH_MEM_CORRUPT: start-on-event=RE_GetDebouncingOfEvent, operation=EvtInfo_EVENT_DFLASH_MEM_CORRUPT.GetDebouncingOfEvent
        EV_GetEventFFEx_EvtEVENT_DFLASH_MEM_CORRUPT: start-on-event=RE_GetEventFreezeFrameDataEx, operation=EvtInfo_EVENT_DFLASH_MEM_CORRUPT.GetEventFreezeFrameDataEx
        EV_GetEventEDREx_EvtEVENT_DFLASH_MEM_CORRUPT: start-on-event=RE_GetEventExtendedDataRecordEx, operation=EvtInfo_EVENT_DFLASH_MEM_CORRUPT.GetEventExtendedDataRecordEx
        EV_SetEventStatus_EvtEVENT_SBC_STATUS_FAILURE: start-on-event=RE_SetEventStatus, operation=Event_EVENT_SBC_STATUS_FAILURE.SetEventStatus
        EV_ResetEventStatus_EvtEVENT_SBC_STATUS_FAILURE: start-on-event=RE_ResetEventStatus, operation=Event_EVENT_SBC_STATUS_FAILURE.ResetEventStatus
        EV_PrestoreFreezeFrame_EvtEVENT_SBC_STATUS_FAILURE: start-on-event=RE_PrestoreFreezeFrame, operation=Event_EVENT_SBC_STATUS_FAILURE.PrestoreFreezeFrame
        EV_ClearPrestoredFF_EvtEVENT_SBC_STATUS_FAILURE: start-on-event=RE_ClearPrestoredFreezeFrame, operation=Event_EVENT_SBC_STATUS_FAILURE.ClearPrestoredFreezeFrame
        EV_ResetEventDebounceStatus_EvtEVENT_SBC_STATUS_FAILURE: start-on-event=RE_ResetEventDebounceStatus, operation=Event_EVENT_SBC_STATUS_FAILURE.ResetEventDebounceStatus
        EV_GetEventStatus_EvtEVENT_SBC_STATUS_FAILURE: start-on-event=RE_GetEventStatus, operation=EvtInfo_EVENT_SBC_STATUS_FAILURE.GetEventStatus
        EV_GetEventFailed_EvtEVENT_SBC_STATUS_FAILURE: start-on-event=RE_GetEventFailed, operation=EvtInfo_EVENT_SBC_STATUS_FAILURE.GetEventFailed
        EV_GetEventTested_EvtEVENT_SBC_STATUS_FAILURE: start-on-event=RE_GetEventTested, operation=EvtInfo_EVENT_SBC_STATUS_FAILURE.GetEventTested
        EV_GetDTCOfEvent_EvtEVENT_SBC_STATUS_FAILURE: start-on-event=RE_GetDTCOfEvent, operation=EvtInfo_EVENT_SBC_STATUS_FAILURE.GetDTCOfEvent
        EV_GetFDC_EvtEVENT_SBC_STATUS_FAILURE: start-on-event=RE_GetFaultDetectionCounter, operation=EvtInfo_EVENT_SBC_STATUS_FAILURE.GetFaultDetectionCounter
        EV_GetEventFF_EvtEVENT_SBC_STATUS_FAILURE: start-on-event=RE_GetEventFreezeFrameData, operation=EvtInfo_EVENT_SBC_STATUS_FAILURE.GetEventFreezeFrameData
        EV_GetEventEDR_EvtEVENT_SBC_STATUS_FAILURE: start-on-event=RE_GetEventExtendedDataRecord, operation=EvtInfo_EVENT_SBC_STATUS_FAILURE.GetEventExtendedDataRecord
        EV_GetDebouncingOfEvent_EvtEVENT_SBC_STATUS_FAILURE: start-on-event=RE_GetDebouncingOfEvent, operation=EvtInfo_EVENT_SBC_STATUS_FAILURE.GetDebouncingOfEvent
        EV_GetEventFFEx_EvtEVENT_SBC_STATUS_FAILURE: start-on-event=RE_GetEventFreezeFrameDataEx, operation=EvtInfo_EVENT_SBC_STATUS_FAILURE.GetEventFreezeFrameDataEx
        EV_GetEventEDREx_EvtEVENT_SBC_STATUS_FAILURE: start-on-event=RE_GetEventExtendedDataRecordEx, operation=EvtInfo_EVENT_SBC_STATUS_FAILURE.GetEventExtendedDataRecordEx
        EV_SetEventStatus_EvtEVENT_POWER_SUPPLY_OV: start-on-event=RE_SetEventStatus, operation=Event_EVENT_POWER_SUPPLY_OV.SetEventStatus
        EV_ResetEventStatus_EvtEVENT_POWER_SUPPLY_OV: start-on-event=RE_ResetEventStatus, operation=Event_EVENT_POWER_SUPPLY_OV.ResetEventStatus
        EV_PrestoreFreezeFrame_EvtEVENT_POWER_SUPPLY_OV: start-on-event=RE_PrestoreFreezeFrame, operation=Event_EVENT_POWER_SUPPLY_OV.PrestoreFreezeFrame
        EV_ClearPrestoredFF_EvtEVENT_POWER_SUPPLY_OV: start-on-event=RE_ClearPrestoredFreezeFrame, operation=Event_EVENT_POWER_SUPPLY_OV.ClearPrestoredFreezeFrame
        EV_ResetEventDebounceStatus_EvtEVENT_POWER_SUPPLY_OV: start-on-event=RE_ResetEventDebounceStatus, operation=Event_EVENT_POWER_SUPPLY_OV.ResetEventDebounceStatus
        EV_GetEventStatus_EvtEVENT_POWER_SUPPLY_OV: start-on-event=RE_GetEventStatus, operation=EvtInfo_EVENT_POWER_SUPPLY_OV.GetEventStatus
        EV_GetEventFailed_EvtEVENT_POWER_SUPPLY_OV: start-on-event=RE_GetEventFailed, operation=EvtInfo_EVENT_POWER_SUPPLY_OV.GetEventFailed
        EV_GetEventTested_EvtEVENT_POWER_SUPPLY_OV: start-on-event=RE_GetEventTested, operation=EvtInfo_EVENT_POWER_SUPPLY_OV.GetEventTested
        EV_GetDTCOfEvent_EvtEVENT_POWER_SUPPLY_OV: start-on-event=RE_GetDTCOfEvent, operation=EvtInfo_EVENT_POWER_SUPPLY_OV.GetDTCOfEvent
        EV_GetFDC_EvtEVENT_POWER_SUPPLY_OV: start-on-event=RE_GetFaultDetectionCounter, operation=EvtInfo_EVENT_POWER_SUPPLY_OV.GetFaultDetectionCounter
        EV_GetEventFF_EvtEVENT_POWER_SUPPLY_OV: start-on-event=RE_GetEventFreezeFrameData, operation=EvtInfo_EVENT_POWER_SUPPLY_OV.GetEventFreezeFrameData
        EV_GetEventEDR_EvtEVENT_POWER_SUPPLY_OV: start-on-event=RE_GetEventExtendedDataRecord, operation=EvtInfo_EVENT_POWER_SUPPLY_OV.GetEventExtendedDataRecord
        EV_GetDebouncingOfEvent_EvtEVENT_POWER_SUPPLY_OV: start-on-event=RE_GetDebouncingOfEvent, operation=EvtInfo_EVENT_POWER_SUPPLY_OV.GetDebouncingOfEvent
        EV_GetEventFFEx_EvtEVENT_POWER_SUPPLY_OV: start-on-event=RE_GetEventFreezeFrameDataEx, operation=EvtInfo_EVENT_POWER_SUPPLY_OV.GetEventFreezeFrameDataEx
        EV_GetEventEDREx_EvtEVENT_POWER_SUPPLY_OV: start-on-event=RE_GetEventExtendedDataRecordEx, operation=EvtInfo_EVENT_POWER_SUPPLY_OV.GetEventExtendedDataRecordEx
        EV_SetEventStatus_EvtEVENT_POWER_SUPPLY_UV: start-on-event=RE_SetEventStatus, operation=Event_EVENT_POWER_SUPPLY_UV.SetEventStatus
        EV_ResetEventStatus_EvtEVENT_POWER_SUPPLY_UV: start-on-event=RE_ResetEventStatus, operation=Event_EVENT_POWER_SUPPLY_UV.ResetEventStatus
        EV_PrestoreFreezeFrame_EvtEVENT_POWER_SUPPLY_UV: start-on-event=RE_PrestoreFreezeFrame, operation=Event_EVENT_POWER_SUPPLY_UV.PrestoreFreezeFrame
        EV_ClearPrestoredFF_EvtEVENT_POWER_SUPPLY_UV: start-on-event=RE_ClearPrestoredFreezeFrame, operation=Event_EVENT_POWER_SUPPLY_UV.ClearPrestoredFreezeFrame
        EV_ResetEventDebounceStatus_EvtEVENT_POWER_SUPPLY_UV: start-on-event=RE_ResetEventDebounceStatus, operation=Event_EVENT_POWER_SUPPLY_UV.ResetEventDebounceStatus
        EV_GetEventStatus_EvtEVENT_POWER_SUPPLY_UV: start-on-event=RE_GetEventStatus, operation=EvtInfo_EVENT_POWER_SUPPLY_UV.GetEventStatus
        EV_GetEventFailed_EvtEVENT_POWER_SUPPLY_UV: start-on-event=RE_GetEventFailed, operation=EvtInfo_EVENT_POWER_SUPPLY_UV.GetEventFailed
        EV_GetEventTested_EvtEVENT_POWER_SUPPLY_UV: start-on-event=RE_GetEventTested, operation=EvtInfo_EVENT_POWER_SUPPLY_UV.GetEventTested
        EV_GetDTCOfEvent_EvtEVENT_POWER_SUPPLY_UV: start-on-event=RE_GetDTCOfEvent, operation=EvtInfo_EVENT_POWER_SUPPLY_UV.GetDTCOfEvent
        EV_GetFDC_EvtEVENT_POWER_SUPPLY_UV: start-on-event=RE_GetFaultDetectionCounter, operation=EvtInfo_EVENT_POWER_SUPPLY_UV.GetFaultDetectionCounter
        EV_GetEventFF_EvtEVENT_POWER_SUPPLY_UV: start-on-event=RE_GetEventFreezeFrameData, operation=EvtInfo_EVENT_POWER_SUPPLY_UV.GetEventFreezeFrameData
        EV_GetEventEDR_EvtEVENT_POWER_SUPPLY_UV: start-on-event=RE_GetEventExtendedDataRecord, operation=EvtInfo_EVENT_POWER_SUPPLY_UV.GetEventExtendedDataRecord
        EV_GetDebouncingOfEvent_EvtEVENT_POWER_SUPPLY_UV: start-on-event=RE_GetDebouncingOfEvent, operation=EvtInfo_EVENT_POWER_SUPPLY_UV.GetDebouncingOfEvent
        EV_GetEventFFEx_EvtEVENT_POWER_SUPPLY_UV: start-on-event=RE_GetEventFreezeFrameDataEx, operation=EvtInfo_EVENT_POWER_SUPPLY_UV.GetEventFreezeFrameDataEx
        EV_GetEventEDREx_EvtEVENT_POWER_SUPPLY_UV: start-on-event=RE_GetEventExtendedDataRecordEx, operation=EvtInfo_EVENT_POWER_SUPPLY_UV.GetEventExtendedDataRecordEx
        EV_SetEventStatus_EvtEVENT_ACTUATOR_STATUS: start-on-event=RE_SetEventStatus, operation=Event_EVENT_ACTUATOR_STATUS.SetEventStatus
        EV_ResetEventStatus_EvtEVENT_ACTUATOR_STATUS: start-on-event=RE_ResetEventStatus, operation=Event_EVENT_ACTUATOR_STATUS.ResetEventStatus
        EV_PrestoreFreezeFrame_EvtEVENT_ACTUATOR_STATUS: start-on-event=RE_PrestoreFreezeFrame, operation=Event_EVENT_ACTUATOR_STATUS.PrestoreFreezeFrame
        EV_ClearPrestoredFF_EvtEVENT_ACTUATOR_STATUS: start-on-event=RE_ClearPrestoredFreezeFrame, operation=Event_EVENT_ACTUATOR_STATUS.ClearPrestoredFreezeFrame
        EV_ResetEventDebounceStatus_EvtEVENT_ACTUATOR_STATUS: start-on-event=RE_ResetEventDebounceStatus, operation=Event_EVENT_ACTUATOR_STATUS.ResetEventDebounceStatus
        EV_GetEventStatus_EvtEVENT_ACTUATOR_STATUS: start-on-event=RE_GetEventStatus, operation=EvtInfo_EVENT_ACTUATOR_STATUS.GetEventStatus
        EV_GetEventFailed_EvtEVENT_ACTUATOR_STATUS: start-on-event=RE_GetEventFailed, operation=EvtInfo_EVENT_ACTUATOR_STATUS.GetEventFailed
        EV_GetEventTested_EvtEVENT_ACTUATOR_STATUS: start-on-event=RE_GetEventTested, operation=EvtInfo_EVENT_ACTUATOR_STATUS.GetEventTested
        EV_GetDTCOfEvent_EvtEVENT_ACTUATOR_STATUS: start-on-event=RE_GetDTCOfEvent, operation=EvtInfo_EVENT_ACTUATOR_STATUS.GetDTCOfEvent
        EV_GetFDC_EvtEVENT_ACTUATOR_STATUS: start-on-event=RE_GetFaultDetectionCounter, operation=EvtInfo_EVENT_ACTUATOR_STATUS.GetFaultDetectionCounter
        EV_GetEventFF_EvtEVENT_ACTUATOR_STATUS: start-on-event=RE_GetEventFreezeFrameData, operation=EvtInfo_EVENT_ACTUATOR_STATUS.GetEventFreezeFrameData
        EV_GetEventEDR_EvtEVENT_ACTUATOR_STATUS: start-on-event=RE_GetEventExtendedDataRecord, operation=EvtInfo_EVENT_ACTUATOR_STATUS.GetEventExtendedDataRecord
        EV_GetDebouncingOfEvent_EvtEVENT_ACTUATOR_STATUS: start-on-event=RE_GetDebouncingOfEvent, operation=EvtInfo_EVENT_ACTUATOR_STATUS.GetDebouncingOfEvent
        EV_GetEventFFEx_EvtEVENT_ACTUATOR_STATUS: start-on-event=RE_GetEventFreezeFrameDataEx, operation=EvtInfo_EVENT_ACTUATOR_STATUS.GetEventFreezeFrameDataEx
        EV_GetEventEDREx_EvtEVENT_ACTUATOR_STATUS: start-on-event=RE_GetEventExtendedDataRecordEx, operation=EvtInfo_EVENT_ACTUATOR_STATUS.GetEventExtendedDataRecordEx
        EV_SetEventStatus_EvtEVENT_MCU_SELFTEST: start-on-event=RE_SetEventStatus, operation=Event_EVENT_MCU_SELFTEST.SetEventStatus
        EV_ResetEventStatus_EvtEVENT_MCU_SELFTEST: start-on-event=RE_ResetEventStatus, operation=Event_EVENT_MCU_SELFTEST.ResetEventStatus
        EV_PrestoreFreezeFrame_EvtEVENT_MCU_SELFTEST: start-on-event=RE_PrestoreFreezeFrame, operation=Event_EVENT_MCU_SELFTEST.PrestoreFreezeFrame
        EV_ClearPrestoredFF_EvtEVENT_MCU_SELFTEST: start-on-event=RE_ClearPrestoredFreezeFrame, operation=Event_EVENT_MCU_SELFTEST.ClearPrestoredFreezeFrame
        EV_ResetEventDebounceStatus_EvtEVENT_MCU_SELFTEST: start-on-event=RE_ResetEventDebounceStatus, operation=Event_EVENT_MCU_SELFTEST.ResetEventDebounceStatus
        EV_GetEventStatus_EvtEVENT_MCU_SELFTEST: start-on-event=RE_GetEventStatus, operation=EvtInfo_EVENT_MCU_SELFTEST.GetEventStatus
        EV_GetEventFailed_EvtEVENT_MCU_SELFTEST: start-on-event=RE_GetEventFailed, operation=EvtInfo_EVENT_MCU_SELFTEST.GetEventFailed
        EV_GetEventTested_EvtEVENT_MCU_SELFTEST: start-on-event=RE_GetEventTested, operation=EvtInfo_EVENT_MCU_SELFTEST.GetEventTested
        EV_GetDTCOfEvent_EvtEVENT_MCU_SELFTEST: start-on-event=RE_GetDTCOfEvent, operation=EvtInfo_EVENT_MCU_SELFTEST.GetDTCOfEvent
        EV_GetFDC_EvtEVENT_MCU_SELFTEST: start-on-event=RE_GetFaultDetectionCounter, operation=EvtInfo_EVENT_MCU_SELFTEST.GetFaultDetectionCounter
        EV_GetEventFF_EvtEVENT_MCU_SELFTEST: start-on-event=RE_GetEventFreezeFrameData, operation=EvtInfo_EVENT_MCU_SELFTEST.GetEventFreezeFrameData
        EV_GetEventEDR_EvtEVENT_MCU_SELFTEST: start-on-event=RE_GetEventExtendedDataRecord, operation=EvtInfo_EVENT_MCU_SELFTEST.GetEventExtendedDataRecord
        EV_GetDebouncingOfEvent_EvtEVENT_MCU_SELFTEST: start-on-event=RE_GetDebouncingOfEvent, operation=EvtInfo_EVENT_MCU_SELFTEST.GetDebouncingOfEvent
        EV_GetEventFFEx_EvtEVENT_MCU_SELFTEST: start-on-event=RE_GetEventFreezeFrameDataEx, operation=EvtInfo_EVENT_MCU_SELFTEST.GetEventFreezeFrameDataEx
        EV_GetEventEDREx_EvtEVENT_MCU_SELFTEST: start-on-event=RE_GetEventExtendedDataRecordEx, operation=EvtInfo_EVENT_MCU_SELFTEST.GetEventExtendedDataRecordEx
        EV_SetEventStatus_EvtEVENT_ACTUATOR_OPEN_CIRCUIT: start-on-event=RE_SetEventStatus, operation=Event_EVENT_ACTUATOR_OPEN_CIRCUIT.SetEventStatus
        EV_ResetEventStatus_EvtEVENT_ACTUATOR_OPEN_CIRCUIT: start-on-event=RE_ResetEventStatus, operation=Event_EVENT_ACTUATOR_OPEN_CIRCUIT.ResetEventStatus
        EV_PrestoreFreezeFrame_EvtEVENT_ACTUATOR_OPEN_CIRCUIT: start-on-event=RE_PrestoreFreezeFrame, operation=Event_EVENT_ACTUATOR_OPEN_CIRCUIT.PrestoreFreezeFrame
        EV_ClearPrestoredFF_EvtEVENT_ACTUATOR_OPEN_CIRCUIT: start-on-event=RE_ClearPrestoredFreezeFrame, operation=Event_EVENT_ACTUATOR_OPEN_CIRCUIT.ClearPrestoredFreezeFrame
        EV_ResetEventDebounceStatus_EvtEVENT_ACTUATOR_OPEN_CIRCUIT: start-on-event=RE_ResetEventDebounceStatus, operation=Event_EVENT_ACTUATOR_OPEN_CIRCUIT.ResetEventDebounceStatus
        EV_GetEventStatus_EvtEVENT_ACTUATOR_OPEN_CIRCUIT: start-on-event=RE_GetEventStatus, operation=EvtInfo_EVENT_ACTUATOR_OPEN_CIRCUIT.GetEventStatus
        EV_GetEventFailed_EvtEVENT_ACTUATOR_OPEN_CIRCUIT: start-on-event=RE_GetEventFailed, operation=EvtInfo_EVENT_ACTUATOR_OPEN_CIRCUIT.GetEventFailed
        EV_GetEventTested_EvtEVENT_ACTUATOR_OPEN_CIRCUIT: start-on-event=RE_GetEventTested, operation=EvtInfo_EVENT_ACTUATOR_OPEN_CIRCUIT.GetEventTested
        EV_GetDTCOfEvent_EvtEVENT_ACTUATOR_OPEN_CIRCUIT: start-on-event=RE_GetDTCOfEvent, operation=EvtInfo_EVENT_ACTUATOR_OPEN_CIRCUIT.GetDTCOfEvent
        EV_GetFDC_EvtEVENT_ACTUATOR_OPEN_CIRCUIT: start-on-event=RE_GetFaultDetectionCounter, operation=EvtInfo_EVENT_ACTUATOR_OPEN_CIRCUIT.GetFaultDetectionCounter
        EV_GetEventFF_EvtEVENT_ACTUATOR_OPEN_CIRCUIT: start-on-event=RE_GetEventFreezeFrameData, operation=EvtInfo_EVENT_ACTUATOR_OPEN_CIRCUIT.GetEventFreezeFrameData
        EV_GetEventEDR_EvtEVENT_ACTUATOR_OPEN_CIRCUIT: start-on-event=RE_GetEventExtendedDataRecord, operation=EvtInfo_EVENT_ACTUATOR_OPEN_CIRCUIT.GetEventExtendedDataRecord
        EV_GetDebouncingOfEvent_EvtEVENT_ACTUATOR_OPEN_CIRCUIT: start-on-event=RE_GetDebouncingOfEvent, operation=EvtInfo_EVENT_ACTUATOR_OPEN_CIRCUIT.GetDebouncingOfEvent
        EV_GetEventFFEx_EvtEVENT_ACTUATOR_OPEN_CIRCUIT: start-on-event=RE_GetEventFreezeFrameDataEx, operation=EvtInfo_EVENT_ACTUATOR_OPEN_CIRCUIT.GetEventFreezeFrameDataEx
        EV_GetEventEDREx_EvtEVENT_ACTUATOR_OPEN_CIRCUIT: start-on-event=RE_GetEventExtendedDataRecordEx, operation=EvtInfo_EVENT_ACTUATOR_OPEN_CIRCUIT.GetEventExtendedDataRecordEx
        EV_SetEventStatus_EvtEVENT_ACTUATOR_SHORT_TO_GND: start-on-event=RE_SetEventStatus, operation=Event_EVENT_ACTUATOR_SHORT_TO_GND.SetEventStatus
        EV_ResetEventStatus_EvtEVENT_ACTUATOR_SHORT_TO_GND: start-on-event=RE_ResetEventStatus, operation=Event_EVENT_ACTUATOR_SHORT_TO_GND.ResetEventStatus
        EV_PrestoreFreezeFrame_EvtEVENT_ACTUATOR_SHORT_TO_GND: start-on-event=RE_PrestoreFreezeFrame, operation=Event_EVENT_ACTUATOR_SHORT_TO_GND.PrestoreFreezeFrame
        EV_ClearPrestoredFF_EvtEVENT_ACTUATOR_SHORT_TO_GND: start-on-event=RE_ClearPrestoredFreezeFrame, operation=Event_EVENT_ACTUATOR_SHORT_TO_GND.ClearPrestoredFreezeFrame
        EV_ResetEventDebounceStatus_EvtEVENT_ACTUATOR_SHORT_TO_GND: start-on-event=RE_ResetEventDebounceStatus, operation=Event_EVENT_ACTUATOR_SHORT_TO_GND.ResetEventDebounceStatus
        EV_GetEventStatus_EvtEVENT_ACTUATOR_SHORT_TO_GND: start-on-event=RE_GetEventStatus, operation=EvtInfo_EVENT_ACTUATOR_SHORT_TO_GND.GetEventStatus
        EV_GetEventFailed_EvtEVENT_ACTUATOR_SHORT_TO_GND: start-on-event=RE_GetEventFailed, operation=EvtInfo_EVENT_ACTUATOR_SHORT_TO_GND.GetEventFailed
        EV_GetEventTested_EvtEVENT_ACTUATOR_SHORT_TO_GND: start-on-event=RE_GetEventTested, operation=EvtInfo_EVENT_ACTUATOR_SHORT_TO_GND.GetEventTested
        EV_GetDTCOfEvent_EvtEVENT_ACTUATOR_SHORT_TO_GND: start-on-event=RE_GetDTCOfEvent, operation=EvtInfo_EVENT_ACTUATOR_SHORT_TO_GND.GetDTCOfEvent
        EV_GetFDC_EvtEVENT_ACTUATOR_SHORT_TO_GND: start-on-event=RE_GetFaultDetectionCounter, operation=EvtInfo_EVENT_ACTUATOR_SHORT_TO_GND.GetFaultDetectionCounter
        EV_GetEventFF_EvtEVENT_ACTUATOR_SHORT_TO_GND: start-on-event=RE_GetEventFreezeFrameData, operation=EvtInfo_EVENT_ACTUATOR_SHORT_TO_GND.GetEventFreezeFrameData
        EV_GetEventEDR_EvtEVENT_ACTUATOR_SHORT_TO_GND: start-on-event=RE_GetEventExtendedDataRecord, operation=EvtInfo_EVENT_ACTUATOR_SHORT_TO_GND.GetEventExtendedDataRecord
        EV_GetDebouncingOfEvent_EvtEVENT_ACTUATOR_SHORT_TO_GND: start-on-event=RE_GetDebouncingOfEvent, operation=EvtInfo_EVENT_ACTUATOR_SHORT_TO_GND.GetDebouncingOfEvent
        EV_GetEventFFEx_EvtEVENT_ACTUATOR_SHORT_TO_GND: start-on-event=RE_GetEventFreezeFrameDataEx, operation=EvtInfo_EVENT_ACTUATOR_SHORT_TO_GND.GetEventFreezeFrameDataEx
        EV_GetEventEDREx_EvtEVENT_ACTUATOR_SHORT_TO_GND: start-on-event=RE_GetEventExtendedDataRecordEx, operation=EvtInfo_EVENT_ACTUATOR_SHORT_TO_GND.GetEventExtendedDataRecordEx
        EV_SetEventStatus_EvtEVENT_ACTUATOR_SHORT_TO_VBAT: start-on-event=RE_SetEventStatus, operation=Event_EVENT_ACTUATOR_SHORT_TO_VBAT.SetEventStatus
        EV_ResetEventStatus_EvtEVENT_ACTUATOR_SHORT_TO_VBAT: start-on-event=RE_ResetEventStatus, operation=Event_EVENT_ACTUATOR_SHORT_TO_VBAT.ResetEventStatus
        EV_PrestoreFreezeFrame_EvtEVENT_ACTUATOR_SHORT_TO_VBAT: start-on-event=RE_PrestoreFreezeFrame, operation=Event_EVENT_ACTUATOR_SHORT_TO_VBAT.PrestoreFreezeFrame
        EV_ClearPrestoredFF_EvtEVENT_ACTUATOR_SHORT_TO_VBAT: start-on-event=RE_ClearPrestoredFreezeFrame, operation=Event_EVENT_ACTUATOR_SHORT_TO_VBAT.ClearPrestoredFreezeFrame
        EV_ResetEventDebounceStatus_EvtEVENT_ACTUATOR_SHORT_TO_VBAT: start-on-event=RE_ResetEventDebounceStatus, operation=Event_EVENT_ACTUATOR_SHORT_TO_VBAT.ResetEventDebounceStatus
        EV_GetEventStatus_EvtEVENT_ACTUATOR_SHORT_TO_VBAT: start-on-event=RE_GetEventStatus, operation=EvtInfo_EVENT_ACTUATOR_SHORT_TO_VBAT.GetEventStatus
        EV_GetEventFailed_EvtEVENT_ACTUATOR_SHORT_TO_VBAT: start-on-event=RE_GetEventFailed, operation=EvtInfo_EVENT_ACTUATOR_SHORT_TO_VBAT.GetEventFailed
        EV_GetEventTested_EvtEVENT_ACTUATOR_SHORT_TO_VBAT: start-on-event=RE_GetEventTested, operation=EvtInfo_EVENT_ACTUATOR_SHORT_TO_VBAT.GetEventTested
        EV_GetDTCOfEvent_EvtEVENT_ACTUATOR_SHORT_TO_VBAT: start-on-event=RE_GetDTCOfEvent, operation=EvtInfo_EVENT_ACTUATOR_SHORT_TO_VBAT.GetDTCOfEvent
        EV_GetFDC_EvtEVENT_ACTUATOR_SHORT_TO_VBAT: start-on-event=RE_GetFaultDetectionCounter, operation=EvtInfo_EVENT_ACTUATOR_SHORT_TO_VBAT.GetFaultDetectionCounter
        EV_GetEventFF_EvtEVENT_ACTUATOR_SHORT_TO_VBAT: start-on-event=RE_GetEventFreezeFrameData, operation=EvtInfo_EVENT_ACTUATOR_SHORT_TO_VBAT.GetEventFreezeFrameData
        EV_GetEventEDR_EvtEVENT_ACTUATOR_SHORT_TO_VBAT: start-on-event=RE_GetEventExtendedDataRecord, operation=EvtInfo_EVENT_ACTUATOR_SHORT_TO_VBAT.GetEventExtendedDataRecord
        EV_GetDebouncingOfEvent_EvtEVENT_ACTUATOR_SHORT_TO_VBAT: start-on-event=RE_GetDebouncingOfEvent, operation=EvtInfo_EVENT_ACTUATOR_SHORT_TO_VBAT.GetDebouncingOfEvent
        EV_GetEventFFEx_EvtEVENT_ACTUATOR_SHORT_TO_VBAT: start-on-event=RE_GetEventFreezeFrameDataEx, operation=EvtInfo_EVENT_ACTUATOR_SHORT_TO_VBAT.GetEventFreezeFrameDataEx
        EV_GetEventEDREx_EvtEVENT_ACTUATOR_SHORT_TO_VBAT: start-on-event=RE_GetEventExtendedDataRecordEx, operation=EvtInfo_EVENT_ACTUATOR_SHORT_TO_VBAT.GetEventExtendedDataRecordEx
        EV_SetEventStatus_EvtEVENT_ACC_STATUS_FAILURE: start-on-event=RE_SetEventStatus, operation=Event_EVENT_ACC_STATUS_FAILURE.SetEventStatus
        EV_ResetEventStatus_EvtEVENT_ACC_STATUS_FAILURE: start-on-event=RE_ResetEventStatus, operation=Event_EVENT_ACC_STATUS_FAILURE.ResetEventStatus
        EV_PrestoreFreezeFrame_EvtEVENT_ACC_STATUS_FAILURE: start-on-event=RE_PrestoreFreezeFrame, operation=Event_EVENT_ACC_STATUS_FAILURE.PrestoreFreezeFrame
        EV_ClearPrestoredFF_EvtEVENT_ACC_STATUS_FAILURE: start-on-event=RE_ClearPrestoredFreezeFrame, operation=Event_EVENT_ACC_STATUS_FAILURE.ClearPrestoredFreezeFrame
        EV_ResetEventDebounceStatus_EvtEVENT_ACC_STATUS_FAILURE: start-on-event=RE_ResetEventDebounceStatus, operation=Event_EVENT_ACC_STATUS_FAILURE.ResetEventDebounceStatus
        EV_GetEventStatus_EvtEVENT_ACC_STATUS_FAILURE: start-on-event=RE_GetEventStatus, operation=EvtInfo_EVENT_ACC_STATUS_FAILURE.GetEventStatus
        EV_GetEventFailed_EvtEVENT_ACC_STATUS_FAILURE: start-on-event=RE_GetEventFailed, operation=EvtInfo_EVENT_ACC_STATUS_FAILURE.GetEventFailed
        EV_GetEventTested_EvtEVENT_ACC_STATUS_FAILURE: start-on-event=RE_GetEventTested, operation=EvtInfo_EVENT_ACC_STATUS_FAILURE.GetEventTested
        EV_GetDTCOfEvent_EvtEVENT_ACC_STATUS_FAILURE: start-on-event=RE_GetDTCOfEvent, operation=EvtInfo_EVENT_ACC_STATUS_FAILURE.GetDTCOfEvent
        EV_GetFDC_EvtEVENT_ACC_STATUS_FAILURE: start-on-event=RE_GetFaultDetectionCounter, operation=EvtInfo_EVENT_ACC_STATUS_FAILURE.GetFaultDetectionCounter
        EV_GetEventFF_EvtEVENT_ACC_STATUS_FAILURE: start-on-event=RE_GetEventFreezeFrameData, operation=EvtInfo_EVENT_ACC_STATUS_FAILURE.GetEventFreezeFrameData
        EV_GetEventEDR_EvtEVENT_ACC_STATUS_FAILURE: start-on-event=RE_GetEventExtendedDataRecord, operation=EvtInfo_EVENT_ACC_STATUS_FAILURE.GetEventExtendedDataRecord
        EV_GetDebouncingOfEvent_EvtEVENT_ACC_STATUS_FAILURE: start-on-event=RE_GetDebouncingOfEvent, operation=EvtInfo_EVENT_ACC_STATUS_FAILURE.GetDebouncingOfEvent
        EV_GetEventFFEx_EvtEVENT_ACC_STATUS_FAILURE: start-on-event=RE_GetEventFreezeFrameDataEx, operation=EvtInfo_EVENT_ACC_STATUS_FAILURE.GetEventFreezeFrameDataEx
        EV_GetEventEDREx_EvtEVENT_ACC_STATUS_FAILURE: start-on-event=RE_GetEventExtendedDataRecordEx, operation=EvtInfo_EVENT_ACC_STATUS_FAILURE.GetEventExtendedDataRecordEx
        EV_GetEventStatus_EvtEVENT_SPI_E_HW_ERROR: start-on-event=RE_GetEventStatus, operation=EvtInfo_EVENT_SPI_E_HW_ERROR.GetEventStatus
        EV_GetEventFailed_EvtEVENT_SPI_E_HW_ERROR: start-on-event=RE_GetEventFailed, operation=EvtInfo_EVENT_SPI_E_HW_ERROR.GetEventFailed
        EV_GetEventTested_EvtEVENT_SPI_E_HW_ERROR: start-on-event=RE_GetEventTested, operation=EvtInfo_EVENT_SPI_E_HW_ERROR.GetEventTested
        EV_GetDTCOfEvent_EvtEVENT_SPI_E_HW_ERROR: start-on-event=RE_GetDTCOfEvent, operation=EvtInfo_EVENT_SPI_E_HW_ERROR.GetDTCOfEvent
        EV_GetFDC_EvtEVENT_SPI_E_HW_ERROR: start-on-event=RE_GetFaultDetectionCounter, operation=EvtInfo_EVENT_SPI_E_HW_ERROR.GetFaultDetectionCounter
        EV_GetEventFF_EvtEVENT_SPI_E_HW_ERROR: start-on-event=RE_GetEventFreezeFrameData, operation=EvtInfo_EVENT_SPI_E_HW_ERROR.GetEventFreezeFrameData
        EV_GetEventEDR_EvtEVENT_SPI_E_HW_ERROR: start-on-event=RE_GetEventExtendedDataRecord, operation=EvtInfo_EVENT_SPI_E_HW_ERROR.GetEventExtendedDataRecord
        EV_GetDebouncingOfEvent_EvtEVENT_SPI_E_HW_ERROR: start-on-event=RE_GetDebouncingOfEvent, operation=EvtInfo_EVENT_SPI_E_HW_ERROR.GetDebouncingOfEvent
        EV_GetEventFFEx_EvtEVENT_SPI_E_HW_ERROR: start-on-event=RE_GetEventFreezeFrameDataEx, operation=EvtInfo_EVENT_SPI_E_HW_ERROR.GetEventFreezeFrameDataEx
        EV_GetEventEDREx_EvtEVENT_SPI_E_HW_ERROR: start-on-event=RE_GetEventExtendedDataRecordEx, operation=EvtInfo_EVENT_SPI_E_HW_ERROR.GetEventExtendedDataRecordEx
        EV_SetEventStatus_EvtEVENT_SOLENOID_OVERVOLTAGE: start-on-event=RE_SetEventStatus, operation=Event_EVENT_SOLENOID_OVERVOLTAGE.SetEventStatus
        EV_ResetEventStatus_EvtEVENT_SOLENOID_OVERVOLTAGE: start-on-event=RE_ResetEventStatus, operation=Event_EVENT_SOLENOID_OVERVOLTAGE.ResetEventStatus
        EV_PrestoreFreezeFrame_EvtEVENT_SOLENOID_OVERVOLTAGE: start-on-event=RE_PrestoreFreezeFrame, operation=Event_EVENT_SOLENOID_OVERVOLTAGE.PrestoreFreezeFrame
        EV_ClearPrestoredFF_EvtEVENT_SOLENOID_OVERVOLTAGE: start-on-event=RE_ClearPrestoredFreezeFrame, operation=Event_EVENT_SOLENOID_OVERVOLTAGE.ClearPrestoredFreezeFrame
        EV_ResetEventDebounceStatus_EvtEVENT_SOLENOID_OVERVOLTAGE: start-on-event=RE_ResetEventDebounceStatus, operation=Event_EVENT_SOLENOID_OVERVOLTAGE.ResetEventDebounceStatus
        EV_GetEventStatus_EvtEVENT_SOLENOID_OVERVOLTAGE: start-on-event=RE_GetEventStatus, operation=EvtInfo_EVENT_SOLENOID_OVERVOLTAGE.GetEventStatus
        EV_GetEventFailed_EvtEVENT_SOLENOID_OVERVOLTAGE: start-on-event=RE_GetEventFailed, operation=EvtInfo_EVENT_SOLENOID_OVERVOLTAGE.GetEventFailed
        EV_GetEventTested_EvtEVENT_SOLENOID_OVERVOLTAGE: start-on-event=RE_GetEventTested, operation=EvtInfo_EVENT_SOLENOID_OVERVOLTAGE.GetEventTested
        EV_GetDTCOfEvent_EvtEVENT_SOLENOID_OVERVOLTAGE: start-on-event=RE_GetDTCOfEvent, operation=EvtInfo_EVENT_SOLENOID_OVERVOLTAGE.GetDTCOfEvent
        EV_GetFDC_EvtEVENT_SOLENOID_OVERVOLTAGE: start-on-event=RE_GetFaultDetectionCounter, operation=EvtInfo_EVENT_SOLENOID_OVERVOLTAGE.GetFaultDetectionCounter
        EV_GetEventFF_EvtEVENT_SOLENOID_OVERVOLTAGE: start-on-event=RE_GetEventFreezeFrameData, operation=EvtInfo_EVENT_SOLENOID_OVERVOLTAGE.GetEventFreezeFrameData
        EV_GetEventEDR_EvtEVENT_SOLENOID_OVERVOLTAGE: start-on-event=RE_GetEventExtendedDataRecord, operation=EvtInfo_EVENT_SOLENOID_OVERVOLTAGE.GetEventExtendedDataRecord
        EV_GetDebouncingOfEvent_EvtEVENT_SOLENOID_OVERVOLTAGE: start-on-event=RE_GetDebouncingOfEvent, operation=EvtInfo_EVENT_SOLENOID_OVERVOLTAGE.GetDebouncingOfEvent
        EV_GetEventFFEx_EvtEVENT_SOLENOID_OVERVOLTAGE: start-on-event=RE_GetEventFreezeFrameDataEx, operation=EvtInfo_EVENT_SOLENOID_OVERVOLTAGE.GetEventFreezeFrameDataEx
        EV_GetEventEDREx_EvtEVENT_SOLENOID_OVERVOLTAGE: start-on-event=RE_GetEventExtendedDataRecordEx, operation=EvtInfo_EVENT_SOLENOID_OVERVOLTAGE.GetEventExtendedDataRecordEx
        EV_SetEventStatus_EvtEVENT_POWER_STAGE_FAILIURE: start-on-event=RE_SetEventStatus, operation=Event_EVENT_POWER_STAGE_FAILIURE.SetEventStatus
        EV_ResetEventStatus_EvtEVENT_POWER_STAGE_FAILIURE: start-on-event=RE_ResetEventStatus, operation=Event_EVENT_POWER_STAGE_FAILIURE.ResetEventStatus
        EV_PrestoreFreezeFrame_EvtEVENT_POWER_STAGE_FAILIURE: start-on-event=RE_PrestoreFreezeFrame, operation=Event_EVENT_POWER_STAGE_FAILIURE.PrestoreFreezeFrame
        EV_ClearPrestoredFF_EvtEVENT_POWER_STAGE_FAILIURE: start-on-event=RE_ClearPrestoredFreezeFrame, operation=Event_EVENT_POWER_STAGE_FAILIURE.ClearPrestoredFreezeFrame
        EV_ResetEventDebounceStatus_EvtEVENT_POWER_STAGE_FAILIURE: start-on-event=RE_ResetEventDebounceStatus, operation=Event_EVENT_POWER_STAGE_FAILIURE.ResetEventDebounceStatus
        EV_GetEventStatus_EvtEVENT_POWER_STAGE_FAILIURE: start-on-event=RE_GetEventStatus, operation=EvtInfo_EVENT_POWER_STAGE_FAILIURE.GetEventStatus
        EV_GetEventFailed_EvtEVENT_POWER_STAGE_FAILIURE: start-on-event=RE_GetEventFailed, operation=EvtInfo_EVENT_POWER_STAGE_FAILIURE.GetEventFailed
        EV_GetEventTested_EvtEVENT_POWER_STAGE_FAILIURE: start-on-event=RE_GetEventTested, operation=EvtInfo_EVENT_POWER_STAGE_FAILIURE.GetEventTested
        EV_GetDTCOfEvent_EvtEVENT_POWER_STAGE_FAILIURE: start-on-event=RE_GetDTCOfEvent, operation=EvtInfo_EVENT_POWER_STAGE_FAILIURE.GetDTCOfEvent
        EV_GetFDC_EvtEVENT_POWER_STAGE_FAILIURE: start-on-event=RE_GetFaultDetectionCounter, operation=EvtInfo_EVENT_POWER_STAGE_FAILIURE.GetFaultDetectionCounter
        EV_GetEventFF_EvtEVENT_POWER_STAGE_FAILIURE: start-on-event=RE_GetEventFreezeFrameData, operation=EvtInfo_EVENT_POWER_STAGE_FAILIURE.GetEventFreezeFrameData
        EV_GetEventEDR_EvtEVENT_POWER_STAGE_FAILIURE: start-on-event=RE_GetEventExtendedDataRecord, operation=EvtInfo_EVENT_POWER_STAGE_FAILIURE.GetEventExtendedDataRecord
        EV_GetDebouncingOfEvent_EvtEVENT_POWER_STAGE_FAILIURE: start-on-event=RE_GetDebouncingOfEvent, operation=EvtInfo_EVENT_POWER_STAGE_FAILIURE.GetDebouncingOfEvent
        EV_GetEventFFEx_EvtEVENT_POWER_STAGE_FAILIURE: start-on-event=RE_GetEventFreezeFrameDataEx, operation=EvtInfo_EVENT_POWER_STAGE_FAILIURE.GetEventFreezeFrameDataEx
        EV_GetEventEDREx_EvtEVENT_POWER_STAGE_FAILIURE: start-on-event=RE_GetEventExtendedDataRecordEx, operation=EvtInfo_EVENT_POWER_STAGE_FAILIURE.GetEventExtendedDataRecordEx
        EV_SetEventStatus_EvtEVENT_MCU_CRC_REGISTERS: start-on-event=RE_SetEventStatus, operation=Event_EVENT_MCU_CRC_REGISTERS.SetEventStatus
        EV_ResetEventStatus_EvtEVENT_MCU_CRC_REGISTERS: start-on-event=RE_ResetEventStatus, operation=Event_EVENT_MCU_CRC_REGISTERS.ResetEventStatus
        EV_PrestoreFreezeFrame_EvtEVENT_MCU_CRC_REGISTERS: start-on-event=RE_PrestoreFreezeFrame, operation=Event_EVENT_MCU_CRC_REGISTERS.PrestoreFreezeFrame
        EV_ClearPrestoredFF_EvtEVENT_MCU_CRC_REGISTERS: start-on-event=RE_ClearPrestoredFreezeFrame, operation=Event_EVENT_MCU_CRC_REGISTERS.ClearPrestoredFreezeFrame
        EV_ResetEventDebounceStatus_EvtEVENT_MCU_CRC_REGISTERS: start-on-event=RE_ResetEventDebounceStatus, operation=Event_EVENT_MCU_CRC_REGISTERS.ResetEventDebounceStatus
        EV_GetEventStatus_EvtEVENT_MCU_CRC_REGISTERS: start-on-event=RE_GetEventStatus, operation=EvtInfo_EVENT_MCU_CRC_REGISTERS.GetEventStatus
        EV_GetEventFailed_EvtEVENT_MCU_CRC_REGISTERS: start-on-event=RE_GetEventFailed, operation=EvtInfo_EVENT_MCU_CRC_REGISTERS.GetEventFailed
        EV_GetEventTested_EvtEVENT_MCU_CRC_REGISTERS: start-on-event=RE_GetEventTested, operation=EvtInfo_EVENT_MCU_CRC_REGISTERS.GetEventTested
        EV_GetDTCOfEvent_EvtEVENT_MCU_CRC_REGISTERS: start-on-event=RE_GetDTCOfEvent, operation=EvtInfo_EVENT_MCU_CRC_REGISTERS.GetDTCOfEvent
        EV_GetFDC_EvtEVENT_MCU_CRC_REGISTERS: start-on-event=RE_GetFaultDetectionCounter, operation=EvtInfo_EVENT_MCU_CRC_REGISTERS.GetFaultDetectionCounter
        EV_GetEventFF_EvtEVENT_MCU_CRC_REGISTERS: start-on-event=RE_GetEventFreezeFrameData, operation=EvtInfo_EVENT_MCU_CRC_REGISTERS.GetEventFreezeFrameData
        EV_GetEventEDR_EvtEVENT_MCU_CRC_REGISTERS: start-on-event=RE_GetEventExtendedDataRecord, operation=EvtInfo_EVENT_MCU_CRC_REGISTERS.GetEventExtendedDataRecord
        EV_GetDebouncingOfEvent_EvtEVENT_MCU_CRC_REGISTERS: start-on-event=RE_GetDebouncingOfEvent, operation=EvtInfo_EVENT_MCU_CRC_REGISTERS.GetDebouncingOfEvent
        EV_GetEventFFEx_EvtEVENT_MCU_CRC_REGISTERS: start-on-event=RE_GetEventFreezeFrameDataEx, operation=EvtInfo_EVENT_MCU_CRC_REGISTERS.GetEventFreezeFrameDataEx
        EV_GetEventEDREx_EvtEVENT_MCU_CRC_REGISTERS: start-on-event=RE_GetEventExtendedDataRecordEx, operation=EvtInfo_EVENT_MCU_CRC_REGISTERS.GetEventExtendedDataRecordEx
        EV_GetEventStatus_GeneralEvt: start-on-event=RE_GetEventStatus, operation=GeneralEvtInfo.GetEventStatus
        EV_GetEventFailed_GeneralEvt: start-on-event=RE_GetEventFailed, operation=GeneralEvtInfo.GetEventFailed
        EV_GetEventTested_GeneralEvt: start-on-event=RE_GetEventTested, operation=GeneralEvtInfo.GetEventTested
        EV_GetDTCOfEvent_GeneralEvt: start-on-event=RE_GetDTCOfEvent, operation=GeneralEvtInfo.GetDTCOfEvent
        EV_GetFDC_GeneralEvt: start-on-event=RE_GetFaultDetectionCounter, operation=GeneralEvtInfo.GetFaultDetectionCounter
        EV_GetEventFF_GeneralEvt: start-on-event=RE_GetEventFreezeFrameData, operation=GeneralEvtInfo.GetEventFreezeFrameData
        EV_GetEventEDR_GeneralEvt: start-on-event=RE_GetEventExtendedDataRecord, operation=GeneralEvtInfo.GetEventExtendedDataRecord
        EV_GetDebouncingOfEvent_GeneralEvt: start-on-event=RE_GetDebouncingOfEvent, operation=GeneralEvtInfo.GetDebouncingOfEvent
        EV_GetEventFFEx_GeneralEvt: start-on-event=RE_GetEventFreezeFrameDataEx, operation=GeneralEvtInfo.GetEventFreezeFrameDataEx
        EV_GetEventEDREx_GeneralEvt: start-on-event=RE_GetEventExtendedDataRecordEx, operation=GeneralEvtInfo.GetEventExtendedDataRecordEx
        EV_SetOperationCycleState_OpCycDEM_OPCYC_POWER: start-on-event=RE_SetOperationCycleState, operation=OpCycle_DEM_OPCYC_POWER.SetOperationCycleState
        EV_SetCycleQualified_OpCycDEM_OPCYC_POWER: start-on-event=RE_SetCycleQualified, operation=OpCycle_DEM_OPCYC_POWER.SetCycleQualified
        EV_GetEventMemoryOverflow_Primary: start-on-event=RE_GetEventMemoryOverflow, operation=OverflowIndPrimaryMemory.GetEventMemoryOverflow
        EV_GetNumberOfEventMemoryEntries_Primary: start-on-event=RE_GetNumberOfEventMemoryEntries, operation=OverflowIndPrimaryMemory.GetNumberOfEventMemoryEntries
        EV_ClearDTC: start-on-event=RE_CddIfClearDTC, operation=CddIf.ClearDTC
      port-api-options:
        {enable-take-address=false, indirect-api=false, port-defined-argument-value{value=DemConf_DemEventParameter_EVENT_CANSM_E_BUS_OFF, value-type=Dem_ASR42_EventIdType}, port=ASR42_EvtInfo_EVENT_CANSM_E_BUS_OFF}
        {enable-take-address=false, indirect-api=false, port-defined-argument-value{value=DemConf_DemEventParameter_EVENT_ADC_OUT_OF_ORDER, value-type=Dem_ASR42_EventIdType}, port=ASR42_Event_EVENT_ADC_OUT_OF_ORDER}
        {enable-take-address=false, indirect-api=false, port-defined-argument-value{value=DemConf_DemEventParameter_EVENT_ADC_OUT_OF_ORDER, value-type=Dem_ASR42_EventIdType}, port=ASR42_EvtInfo_EVENT_ADC_OUT_OF_ORDER}
        {enable-take-address=false, indirect-api=false, port-defined-argument-value{value=DemConf_DemEventParameter_EVENT_WARM_RESET, value-type=Dem_ASR42_EventIdType}, port=ASR42_Event_EVENT_WARM_RESET}
        {enable-take-address=false, indirect-api=false, port-defined-argument-value{value=DemConf_DemEventParameter_EVENT_WARM_RESET, value-type=Dem_ASR42_EventIdType}, port=ASR42_EvtInfo_EVENT_WARM_RESET}
        {enable-take-address=false, indirect-api=false, port-defined-argument-value{value=DemConf_DemEventParameter_EVENT_PFLASH_MEM_CORRUPT, value-type=Dem_ASR42_EventIdType}, port=ASR42_Event_EVENT_PFLASH_MEM_CORRUPT}
        {enable-take-address=false, indirect-api=false, port-defined-argument-value{value=DemConf_DemEventParameter_EVENT_PFLASH_MEM_CORRUPT, value-type=Dem_ASR42_EventIdType}, port=ASR42_EvtInfo_EVENT_PFLASH_MEM_CORRUPT}
        {enable-take-address=false, indirect-api=false, port-defined-argument-value{value=DemConf_DemEventParameter_EVENT_EXT_WDG_OUT_OF_ORDER, value-type=Dem_ASR42_EventIdType}, port=ASR42_Event_EVENT_EXT_WDG_OUT_OF_ORDER}
        {enable-take-address=false, indirect-api=false, port-defined-argument-value{value=DemConf_DemEventParameter_EVENT_EXT_WDG_OUT_OF_ORDER, value-type=Dem_ASR42_EventIdType}, port=ASR42_EvtInfo_EVENT_EXT_WDG_OUT_OF_ORDER}
        {enable-take-address=false, indirect-api=false, port-defined-argument-value{value=DemConf_DemEventParameter_EVENT_NVM_NOT_PRG, value-type=Dem_ASR42_EventIdType}, port=ASR42_Event_EVENT_NVM_NOT_PRG}
        {enable-take-address=false, indirect-api=false, port-defined-argument-value{value=DemConf_DemEventParameter_EVENT_NVM_NOT_PRG, value-type=Dem_ASR42_EventIdType}, port=ASR42_EvtInfo_EVENT_NVM_NOT_PRG}
        {enable-take-address=false, indirect-api=false, port-defined-argument-value{value=DemConf_DemEventParameter_EVENT_RAM_MEM_CORRUPT, value-type=Dem_ASR42_EventIdType}, port=ASR42_Event_EVENT_RAM_MEM_CORRUPT}
        {enable-take-address=false, indirect-api=false, port-defined-argument-value{value=DemConf_DemEventParameter_EVENT_RAM_MEM_CORRUPT, value-type=Dem_ASR42_EventIdType}, port=ASR42_EvtInfo_EVENT_RAM_MEM_CORRUPT}
        {enable-take-address=false, indirect-api=false, port-defined-argument-value{value=DemConf_DemEventParameter_EVENT_ADC_CALIB, value-type=Dem_ASR42_EventIdType}, port=ASR42_Event_EVENT_ADC_CALIB}
        {enable-take-address=false, indirect-api=false, port-defined-argument-value{value=DemConf_DemEventParameter_EVENT_ADC_CALIB, value-type=Dem_ASR42_EventIdType}, port=ASR42_EvtInfo_EVENT_ADC_CALIB}
        {enable-take-address=false, indirect-api=false, port-defined-argument-value{value=DemConf_DemEventParameter_EVENT_ECU_OVER_TEMPERATURE, value-type=Dem_ASR42_EventIdType}, port=ASR42_Event_EVENT_ECU_OVER_TEMPERATURE}
        {enable-take-address=false, indirect-api=false, port-defined-argument-value{value=DemConf_DemEventParameter_EVENT_ECU_OVER_TEMPERATURE, value-type=Dem_ASR42_EventIdType}, port=ASR42_EvtInfo_EVENT_ECU_OVER_TEMPERATURE}
        {enable-take-address=false, indirect-api=false, port-defined-argument-value{value=DemConf_DemEventParameter_EVENT_DFLASH_MEM_CORRUPT, value-type=Dem_ASR42_EventIdType}, port=ASR42_Event_EVENT_DFLASH_MEM_CORRUPT}
        {enable-take-address=false, indirect-api=false, port-defined-argument-value{value=DemConf_DemEventParameter_EVENT_DFLASH_MEM_CORRUPT, value-type=Dem_ASR42_EventIdType}, port=ASR42_EvtInfo_EVENT_DFLASH_MEM_CORRUPT}
        {enable-take-address=false, indirect-api=false, port-defined-argument-value{value=DemConf_DemEventParameter_EVENT_SBC_STATUS_FAILURE, value-type=Dem_ASR42_EventIdType}, port=ASR42_Event_EVENT_SBC_STATUS_FAILURE}
        {enable-take-address=false, indirect-api=false, port-defined-argument-value{value=DemConf_DemEventParameter_EVENT_SBC_STATUS_FAILURE, value-type=Dem_ASR42_EventIdType}, port=ASR42_EvtInfo_EVENT_SBC_STATUS_FAILURE}
        {enable-take-address=false, indirect-api=false, port-defined-argument-value{value=DemConf_DemEventParameter_EVENT_POWER_SUPPLY_OV, value-type=Dem_ASR42_EventIdType}, port=ASR42_Event_EVENT_POWER_SUPPLY_OV}
        {enable-take-address=false, indirect-api=false, port-defined-argument-value{value=DemConf_DemEventParameter_EVENT_POWER_SUPPLY_OV, value-type=Dem_ASR42_EventIdType}, port=ASR42_EvtInfo_EVENT_POWER_SUPPLY_OV}
        {enable-take-address=false, indirect-api=false, port-defined-argument-value{value=DemConf_DemEventParameter_EVENT_POWER_SUPPLY_UV, value-type=Dem_ASR42_EventIdType}, port=ASR42_Event_EVENT_POWER_SUPPLY_UV}
        {enable-take-address=false, indirect-api=false, port-defined-argument-value{value=DemConf_DemEventParameter_EVENT_POWER_SUPPLY_UV, value-type=Dem_ASR42_EventIdType}, port=ASR42_EvtInfo_EVENT_POWER_SUPPLY_UV}
        {enable-take-address=false, indirect-api=false, port-defined-argument-value{value=DemConf_DemEventParameter_EVENT_ACTUATOR_STATUS, value-type=Dem_ASR42_EventIdType}, port=ASR42_Event_EVENT_ACTUATOR_STATUS}
        {enable-take-address=false, indirect-api=false, port-defined-argument-value{value=DemConf_DemEventParameter_EVENT_ACTUATOR_STATUS, value-type=Dem_ASR42_EventIdType}, port=ASR42_EvtInfo_EVENT_ACTUATOR_STATUS}
        {enable-take-address=false, indirect-api=false, port-defined-argument-value{value=DemConf_DemEventParameter_EVENT_MCU_SELFTEST, value-type=Dem_ASR42_EventIdType}, port=ASR42_Event_EVENT_MCU_SELFTEST}
        {enable-take-address=false, indirect-api=false, port-defined-argument-value{value=DemConf_DemEventParameter_EVENT_MCU_SELFTEST, value-type=Dem_ASR42_EventIdType}, port=ASR42_EvtInfo_EVENT_MCU_SELFTEST}
        {enable-take-address=false, indirect-api=false, port-defined-argument-value{value=DemConf_DemEventParameter_EVENT_ACTUATOR_OPEN_CIRCUIT, value-type=Dem_ASR42_EventIdType}, port=ASR42_Event_EVENT_ACTUATOR_OPEN_CIRCUIT}
        {enable-take-address=false, indirect-api=false, port-defined-argument-value{value=DemConf_DemEventParameter_EVENT_ACTUATOR_OPEN_CIRCUIT, value-type=Dem_ASR42_EventIdType}, port=ASR42_EvtInfo_EVENT_ACTUATOR_OPEN_CIRCUIT}
        {enable-take-address=false, indirect-api=false, port-defined-argument-value{value=DemConf_DemEventParameter_EVENT_ACTUATOR_SHORT_TO_GND, value-type=Dem_ASR42_EventIdType}, port=ASR42_Event_EVENT_ACTUATOR_SHORT_TO_GND}
        {enable-take-address=false, indirect-api=false, port-defined-argument-value{value=DemConf_DemEventParameter_EVENT_ACTUATOR_SHORT_TO_GND, value-type=Dem_ASR42_EventIdType}, port=ASR42_EvtInfo_EVENT_ACTUATOR_SHORT_TO_GND}
        {enable-take-address=false, indirect-api=false, port-defined-argument-value{value=DemConf_DemEventParameter_EVENT_ACTUATOR_SHORT_TO_VBAT, value-type=Dem_ASR42_EventIdType}, port=ASR42_Event_EVENT_ACTUATOR_SHORT_TO_VBAT}
        {enable-take-address=false, indirect-api=false, port-defined-argument-value{value=DemConf_DemEventParameter_EVENT_ACTUATOR_SHORT_TO_VBAT, value-type=Dem_ASR42_EventIdType}, port=ASR42_EvtInfo_EVENT_ACTUATOR_SHORT_TO_VBAT}
        {enable-take-address=false, indirect-api=false, port-defined-argument-value{value=DemConf_DemEventParameter_EVENT_ACC_STATUS_FAILURE, value-type=Dem_ASR42_EventIdType}, port=ASR42_Event_EVENT_ACC_STATUS_FAILURE}
        {enable-take-address=false, indirect-api=false, port-defined-argument-value{value=DemConf_DemEventParameter_EVENT_ACC_STATUS_FAILURE, value-type=Dem_ASR42_EventIdType}, port=ASR42_EvtInfo_EVENT_ACC_STATUS_FAILURE}
        {enable-take-address=false, indirect-api=false, port-defined-argument-value{value=DemConf_DemEventParameter_EVENT_SPI_E_HW_ERROR, value-type=Dem_ASR42_EventIdType}, port=ASR42_EvtInfo_EVENT_SPI_E_HW_ERROR}
        {enable-take-address=false, indirect-api=false, port-defined-argument-value{value=DemConf_DemEventParameter_EVENT_SOLENOID_OVERVOLTAGE, value-type=Dem_ASR42_EventIdType}, port=ASR42_Event_EVENT_SOLENOID_OVERVOLTAGE}
        {enable-take-address=false, indirect-api=false, port-defined-argument-value{value=DemConf_DemEventParameter_EVENT_SOLENOID_OVERVOLTAGE, value-type=Dem_ASR42_EventIdType}, port=ASR42_EvtInfo_EVENT_SOLENOID_OVERVOLTAGE}
        {enable-take-address=false, indirect-api=false, port-defined-argument-value{value=DemConf_DemEventParameter_EVENT_POWER_STAGE_FAILIURE, value-type=Dem_ASR42_EventIdType}, port=ASR42_Event_EVENT_POWER_STAGE_FAILIURE}
        {enable-take-address=false, indirect-api=false, port-defined-argument-value{value=DemConf_DemEventParameter_EVENT_POWER_STAGE_FAILIURE, value-type=Dem_ASR42_EventIdType}, port=ASR42_EvtInfo_EVENT_POWER_STAGE_FAILIURE}
        {enable-take-address=false, indirect-api=false, port-defined-argument-value{value=DemConf_DemEventParameter_EVENT_MCU_CRC_REGISTERS, value-type=Dem_ASR42_EventIdType}, port=ASR42_Event_EVENT_MCU_CRC_REGISTERS}
        {enable-take-address=false, indirect-api=false, port-defined-argument-value{value=DemConf_DemEventParameter_EVENT_MCU_CRC_REGISTERS, value-type=Dem_ASR42_EventIdType}, port=ASR42_EvtInfo_EVENT_MCU_CRC_REGISTERS}
        {enable-take-address=false, indirect-api=false, port-defined-argument-value{value=DEM_OPCYC_POWER, value-type=Dem_OperationCycleIdType}, port=ASR42_OpCycle_DEM_OPCYC_POWER}
        {enable-take-address=false, indirect-api=false, port-defined-argument-value{value=DEM_DTC_ORIGIN_PRIMARY_MEMORY, value-type=Dem_ASR42_DTCOriginType}, port=ASR42_OverflowIndPrimaryMemory}
        {enable-take-address=false, indirect-api=false, port-defined-argument-value{value=DemConf_DemEventParameter_EVENT_CANSM_E_BUS_OFF, value-type=Dem_EventIdType}, port=EvtInfo_EVENT_CANSM_E_BUS_OFF}
        {enable-take-address=false, indirect-api=false, port-defined-argument-value{value=DemConf_DemEventParameter_EVENT_ADC_OUT_OF_ORDER, value-type=Dem_EventIdType}, port=Event_EVENT_ADC_OUT_OF_ORDER}
        {enable-take-address=false, indirect-api=false, port-defined-argument-value{value=DemConf_DemEventParameter_EVENT_ADC_OUT_OF_ORDER, value-type=Dem_EventIdType}, port=EvtInfo_EVENT_ADC_OUT_OF_ORDER}
        {enable-take-address=false, indirect-api=false, port-defined-argument-value{value=DemConf_DemEventParameter_EVENT_WARM_RESET, value-type=Dem_EventIdType}, port=Event_EVENT_WARM_RESET}
        {enable-take-address=false, indirect-api=false, port-defined-argument-value{value=DemConf_DemEventParameter_EVENT_WARM_RESET, value-type=Dem_EventIdType}, port=EvtInfo_EVENT_WARM_RESET}
        {enable-take-address=false, indirect-api=false, port-defined-argument-value{value=DemConf_DemEventParameter_EVENT_PFLASH_MEM_CORRUPT, value-type=Dem_EventIdType}, port=Event_EVENT_PFLASH_MEM_CORRUPT}
        {enable-take-address=false, indirect-api=false, port-defined-argument-value{value=DemConf_DemEventParameter_EVENT_PFLASH_MEM_CORRUPT, value-type=Dem_EventIdType}, port=EvtInfo_EVENT_PFLASH_MEM_CORRUPT}
        {enable-take-address=false, indirect-api=false, port-defined-argument-value{value=DemConf_DemEventParameter_EVENT_EXT_WDG_OUT_OF_ORDER, value-type=Dem_EventIdType}, port=Event_EVENT_EXT_WDG_OUT_OF_ORDER}
        {enable-take-address=false, indirect-api=false, port-defined-argument-value{value=DemConf_DemEventParameter_EVENT_EXT_WDG_OUT_OF_ORDER, value-type=Dem_EventIdType}, port=EvtInfo_EVENT_EXT_WDG_OUT_OF_ORDER}
        {enable-take-address=false, indirect-api=false, port-defined-argument-value{value=DemConf_DemEventParameter_EVENT_NVM_NOT_PRG, value-type=Dem_EventIdType}, port=Event_EVENT_NVM_NOT_PRG}
        {enable-take-address=false, indirect-api=false, port-defined-argument-value{value=DemConf_DemEventParameter_EVENT_NVM_NOT_PRG, value-type=Dem_EventIdType}, port=EvtInfo_EVENT_NVM_NOT_PRG}
        {enable-take-address=false, indirect-api=false, port-defined-argument-value{value=DemConf_DemEventParameter_EVENT_RAM_MEM_CORRUPT, value-type=Dem_EventIdType}, port=Event_EVENT_RAM_MEM_CORRUPT}
        {enable-take-address=false, indirect-api=false, port-defined-argument-value{value=DemConf_DemEventParameter_EVENT_RAM_MEM_CORRUPT, value-type=Dem_EventIdType}, port=EvtInfo_EVENT_RAM_MEM_CORRUPT}
        {enable-take-address=false, indirect-api=false, port-defined-argument-value{value=DemConf_DemEventParameter_EVENT_ADC_CALIB, value-type=Dem_EventIdType}, port=Event_EVENT_ADC_CALIB}
        {enable-take-address=false, indirect-api=false, port-defined-argument-value{value=DemConf_DemEventParameter_EVENT_ADC_CALIB, value-type=Dem_EventIdType}, port=EvtInfo_EVENT_ADC_CALIB}
        {enable-take-address=false, indirect-api=false, port-defined-argument-value{value=DemConf_DemEventParameter_EVENT_ECU_OVER_TEMPERATURE, value-type=Dem_EventIdType}, port=Event_EVENT_ECU_OVER_TEMPERATURE}
        {enable-take-address=false, indirect-api=false, port-defined-argument-value{value=DemConf_DemEventParameter_EVENT_ECU_OVER_TEMPERATURE, value-type=Dem_EventIdType}, port=EvtInfo_EVENT_ECU_OVER_TEMPERATURE}
        {enable-take-address=false, indirect-api=false, port-defined-argument-value{value=DemConf_DemEventParameter_EVENT_DFLASH_MEM_CORRUPT, value-type=Dem_EventIdType}, port=Event_EVENT_DFLASH_MEM_CORRUPT}
        {enable-take-address=false, indirect-api=false, port-defined-argument-value{value=DemConf_DemEventParameter_EVENT_DFLASH_MEM_CORRUPT, value-type=Dem_EventIdType}, port=EvtInfo_EVENT_DFLASH_MEM_CORRUPT}
        {enable-take-address=false, indirect-api=false, port-defined-argument-value{value=DemConf_DemEventParameter_EVENT_SBC_STATUS_FAILURE, value-type=Dem_EventIdType}, port=Event_EVENT_SBC_STATUS_FAILURE}
        {enable-take-address=false, indirect-api=false, port-defined-argument-value{value=DemConf_DemEventParameter_EVENT_SBC_STATUS_FAILURE, value-type=Dem_EventIdType}, port=EvtInfo_EVENT_SBC_STATUS_FAILURE}
        {enable-take-address=false, indirect-api=false, port-defined-argument-value{value=DemConf_DemEventParameter_EVENT_POWER_SUPPLY_OV, value-type=Dem_EventIdType}, port=Event_EVENT_POWER_SUPPLY_OV}
        {enable-take-address=false, indirect-api=false, port-defined-argument-value{value=DemConf_DemEventParameter_EVENT_POWER_SUPPLY_OV, value-type=Dem_EventIdType}, port=EvtInfo_EVENT_POWER_SUPPLY_OV}
        {enable-take-address=false, indirect-api=false, port-defined-argument-value{value=DemConf_DemEventParameter_EVENT_POWER_SUPPLY_UV, value-type=Dem_EventIdType}, port=Event_EVENT_POWER_SUPPLY_UV}
        {enable-take-address=false, indirect-api=false, port-defined-argument-value{value=DemConf_DemEventParameter_EVENT_POWER_SUPPLY_UV, value-type=Dem_EventIdType}, port=EvtInfo_EVENT_POWER_SUPPLY_UV}
        {enable-take-address=false, indirect-api=false, port-defined-argument-value{value=DemConf_DemEventParameter_EVENT_ACTUATOR_STATUS, value-type=Dem_EventIdType}, port=Event_EVENT_ACTUATOR_STATUS}
        {enable-take-address=false, indirect-api=false, port-defined-argument-value{value=DemConf_DemEventParameter_EVENT_ACTUATOR_STATUS, value-type=Dem_EventIdType}, port=EvtInfo_EVENT_ACTUATOR_STATUS}
        {enable-take-address=false, indirect-api=false, port-defined-argument-value{value=DemConf_DemEventParameter_EVENT_MCU_SELFTEST, value-type=Dem_EventIdType}, port=Event_EVENT_MCU_SELFTEST}
        {enable-take-address=false, indirect-api=false, port-defined-argument-value{value=DemConf_DemEventParameter_EVENT_MCU_SELFTEST, value-type=Dem_EventIdType}, port=EvtInfo_EVENT_MCU_SELFTEST}
        {enable-take-address=false, indirect-api=false, port-defined-argument-value{value=DemConf_DemEventParameter_EVENT_ACTUATOR_OPEN_CIRCUIT, value-type=Dem_EventIdType}, port=Event_EVENT_ACTUATOR_OPEN_CIRCUIT}
        {enable-take-address=false, indirect-api=false, port-defined-argument-value{value=DemConf_DemEventParameter_EVENT_ACTUATOR_OPEN_CIRCUIT, value-type=Dem_EventIdType}, port=EvtInfo_EVENT_ACTUATOR_OPEN_CIRCUIT}
        {enable-take-address=false, indirect-api=false, port-defined-argument-value{value=DemConf_DemEventParameter_EVENT_ACTUATOR_SHORT_TO_GND, value-type=Dem_EventIdType}, port=Event_EVENT_ACTUATOR_SHORT_TO_GND}
        {enable-take-address=false, indirect-api=false, port-defined-argument-value{value=DemConf_DemEventParameter_EVENT_ACTUATOR_SHORT_TO_GND, value-type=Dem_EventIdType}, port=EvtInfo_EVENT_ACTUATOR_SHORT_TO_GND}
        {enable-take-address=false, indirect-api=false, port-defined-argument-value{value=DemConf_DemEventParameter_EVENT_ACTUATOR_SHORT_TO_VBAT, value-type=Dem_EventIdType}, port=Event_EVENT_ACTUATOR_SHORT_TO_VBAT}
        {enable-take-address=false, indirect-api=false, port-defined-argument-value{value=DemConf_DemEventParameter_EVENT_ACTUATOR_SHORT_TO_VBAT, value-type=Dem_EventIdType}, port=EvtInfo_EVENT_ACTUATOR_SHORT_TO_VBAT}
        {enable-take-address=false, indirect-api=false, port-defined-argument-value{value=DemConf_DemEventParameter_EVENT_ACC_STATUS_FAILURE, value-type=Dem_EventIdType}, port=Event_EVENT_ACC_STATUS_FAILURE}
        {enable-take-address=false, indirect-api=false, port-defined-argument-value{value=DemConf_DemEventParameter_EVENT_ACC_STATUS_FAILURE, value-type=Dem_EventIdType}, port=EvtInfo_EVENT_ACC_STATUS_FAILURE}
        {enable-take-address=false, indirect-api=false, port-defined-argument-value{value=DemConf_DemEventParameter_EVENT_SPI_E_HW_ERROR, value-type=Dem_EventIdType}, port=EvtInfo_EVENT_SPI_E_HW_ERROR}
        {enable-take-address=false, indirect-api=false, port-defined-argument-value{value=DemConf_DemEventParameter_EVENT_SOLENOID_OVERVOLTAGE, value-type=Dem_EventIdType}, port=Event_EVENT_SOLENOID_OVERVOLTAGE}
        {enable-take-address=false, indirect-api=false, port-defined-argument-value{value=DemConf_DemEventParameter_EVENT_SOLENOID_OVERVOLTAGE, value-type=Dem_EventIdType}, port=EvtInfo_EVENT_SOLENOID_OVERVOLTAGE}
        {enable-take-address=false, indirect-api=false, port-defined-argument-value{value=DemConf_DemEventParameter_EVENT_POWER_STAGE_FAILIURE, value-type=Dem_EventIdType}, port=Event_EVENT_POWER_STAGE_FAILIURE}
        {enable-take-address=false, indirect-api=false, port-defined-argument-value{value=DemConf_DemEventParameter_EVENT_POWER_STAGE_FAILIURE, value-type=Dem_EventIdType}, port=EvtInfo_EVENT_POWER_STAGE_FAILIURE}
        {enable-take-address=false, indirect-api=false, port-defined-argument-value{value=DemConf_DemEventParameter_EVENT_MCU_CRC_REGISTERS, value-type=Dem_EventIdType}, port=Event_EVENT_MCU_CRC_REGISTERS}
        {enable-take-address=false, indirect-api=false, port-defined-argument-value{value=DemConf_DemEventParameter_EVENT_MCU_CRC_REGISTERS, value-type=Dem_EventIdType}, port=EvtInfo_EVENT_MCU_CRC_REGISTERS}
        {enable-take-address=false, indirect-api=false, port-defined-argument-value{value=DEM_OPCYC_POWER, value-type=Dem_OperationCycleIdType}, port=OpCycle_DEM_OPCYC_POWER}
        {enable-take-address=false, indirect-api=false, port-defined-argument-value{value=DEM_DTC_ORIGIN_PRIMARY_MEMORY, value-type=Dem_DTCOriginType}, port=OverflowIndPrimaryMemory}
      21 x runnable:
        RE_GetDTCOfEvent: arguments=[symbol=EventId, symbol=DTCFormat, symbol=DTCOfEvent], can-be-invoked-concurrently=true, symbol=Dem_GetDTCOfEvent
        RE_GetEventFreezeFrameData: arguments=[symbol=EventId, symbol=RecordNumber, symbol=ReportTotalRecord, symbol=DataId, symbol=DestBuffer], can-be-invoked-concurrently=true, symbol=Dem_ASR42_GetEventFreezeFrameData
        RE_CddIfClearDTC: symbol=Dem_ASR42_ClearDTC
        RE_SetEventStatus: arguments=[symbol=EventId, symbol=EventStatus], can-be-invoked-concurrently=true, symbol=Dem_SetEventStatus
        RE_ResetEventStatus: runnable-entity-argument=symbol=EventId, can-be-invoked-concurrently=true, symbol=Dem_ResetEventStatus
        RE_PrestoreFreezeFrame: runnable-entity-argument=symbol=EventId, can-be-invoked-concurrently=true, symbol=Dem_PrestoreFreezeFrame
        RE_ClearPrestoredFreezeFrame: runnable-entity-argument=symbol=EventId, can-be-invoked-concurrently=true, symbol=Dem_ClearPrestoredFreezeFrame
        RE_ResetEventDebounceStatus: arguments=[symbol=EventId, symbol=DebounceResetStatus], can-be-invoked-concurrently=true, symbol=Dem_ResetEventDebounceStatus
        RE_GetEventStatus: arguments=[symbol=EventId, symbol=EventStatusExtended], can-be-invoked-concurrently=true, symbol=Dem_GetEventStatus
        RE_GetEventFailed: arguments=[symbol=EventId, symbol=EventFailed], can-be-invoked-concurrently=true, symbol=Dem_GetEventFailed
        RE_GetEventTested: arguments=[symbol=EventId, symbol=EventTested], can-be-invoked-concurrently=true, symbol=Dem_GetEventTested
        RE_GetFaultDetectionCounter: arguments=[symbol=EventId, symbol=FaultDetectionCounter], can-be-invoked-concurrently=true, symbol=Dem_GetFaultDetectionCounter
        RE_GetEventExtendedDataRecord: arguments=[symbol=EventId, symbol=RecordNumber, symbol=DestBuffer], can-be-invoked-concurrently=true, symbol=Dem_GetEventExtendedDataRecord
        RE_GetDebouncingOfEvent: arguments=[symbol=EventId, symbol=DebouncingState], can-be-invoked-concurrently=true, symbol=Dem_GetDebouncingOfEvent
        RE_GetEventFreezeFrameDataEx: arguments=[symbol=EventId, symbol=RecordNumber, symbol=DataId, symbol=DestBuffer, symbol=BufSize], can-be-invoked-concurrently=true, symbol=Dem_GetEventFreezeFrameDataEx
        RE_GetEventExtendedDataRecordEx: arguments=[symbol=EventId, symbol=RecordNumber, symbol=DestBuffer, symbol=BufSize], can-be-invoked-concurrently=true, symbol=Dem_GetEventExtendedDataRecordEx
        RE_SetOperationCycleState: arguments=[symbol=OperationCycleId, symbol=CycleState], can-be-invoked-concurrently=true, symbol=Dem_SetOperationCycleState
        RE_SetCycleQualified: runnable-entity-argument=symbol=OperationCycleId, can-be-invoked-concurrently=true, symbol=Dem_SetCycleQualified
        RE_GetEventMemoryOverflow: arguments=[symbol=DTCOrigin, symbol=OverflowIndication], can-be-invoked-concurrently=true, symbol=Dem_GetEventMemoryOverflow
        RE_GetNumberOfEventMemoryEntries: arguments=[symbol=DTCOrigin, symbol=NumberOfEventMemoryEntries], can-be-invoked-concurrently=true, symbol=Dem_GetNumberOfEventMemoryEntries
        RE_MainFunction: symbol=Dem_MainFunction
package /EB_Dem/SwcImplementations
  swc implementation DemImpl: programming-language=C, sw-version=6.4.7, vendor-id=1, behavior=DemIntBeh
    code-descriptors:
      code DemCode: artifact-descriptors=autosar-engineering-object={short-label=EngObject, category=SWSRC}
    resource consumption Resources
      memory section CODE: sw-addrmethod=CODE
